// Modified by dbc-patcher V1.0F © 2009 Ingo Müller
VERSION "HNNBNNNYNNNNNNNNNNNNNNNNNNNNNNNNNNNNNNNNNN/4/%%%/4/'%**4NNN///"

NS_ :

BS_:

BU_: Airbag_MQB BAP_Tester_MQB BMS_MQB Datenlogger_MQB Gateway_MQB Getriebe_DQ_Hybrid_MQB Getriebe_DQ_MQB LEH_MQB Motor_Diesel_MQB Motor_Hybrid_MQB Motor_Otto_MQB SAK_MQB Waehlhebel_MQB

BO_ 262 ESP_05: 8 Gateway_MQB
 SG_ ESP_05_CRC : 0|8@1+ (1,0) [0|255] ""  Airbag_MQB,Getriebe_DQ_Hybrid_MQB,Getriebe_DQ_MQB,Motor_Diesel_MQB,Motor_Hybrid_MQB,Motor_Otto_MQB
 SG_ ESP_05_BZ : 8|4@1+ (1,0) [0|15] ""  Airbag_MQB,Getriebe_DQ_Hybrid_MQB,Getriebe_DQ_MQB,Motor_Diesel_MQB,Motor_Hybrid_MQB,Motor_Otto_MQB
 SG_ ESP_QBit_Bremsdruck : 12|1@1+ (1,0) [0|1] ""  Airbag_MQB,Getriebe_DQ_Hybrid_MQB,Getriebe_DQ_MQB,Motor_Diesel_MQB,Motor_Hybrid_MQB,Motor_Otto_MQB
 SG_ ESP_QBit_Fahrer_bremst : 13|1@1+ (1,0) [0|1] ""  Motor_Diesel_MQB,Motor_Hybrid_MQB,Motor_Otto_MQB
 SG_ ESP_Schwelle_Unterdruck : 14|2@1+ (1,0) [0|3] ""  Motor_Diesel_MQB,Motor_Hybrid_MQB,Motor_Otto_MQB
 SG_ ESP_Bremsdruck : 16|10@1+ (0.3,-30) [-30|276.6] "Unit_Bar"  Airbag_MQB,Getriebe_DQ_Hybrid_MQB,Getriebe_DQ_MQB,Motor_Diesel_MQB,Motor_Hybrid_MQB,Motor_Otto_MQB
 SG_ ESP_Fahrer_bremst : 26|1@1+ (1,0) [0|1] ""  Motor_Diesel_MQB,Motor_Hybrid_MQB,Motor_Otto_MQB
 SG_ ESP_Verz_TSK_aktiv : 27|1@1+ (1,0) [0|1] ""  Getriebe_DQ_Hybrid_MQB,Getriebe_DQ_MQB,Motor_Diesel_MQB,Motor_Hybrid_MQB,Motor_Otto_MQB
 SG_ ESP_Lenkeingriff_ADS : 28|1@1+ (1,0) [0|1] ""  Motor_Diesel_MQB,Motor_Hybrid_MQB,Motor_Otto_MQB
 SG_ ESP_Konsistenz_TSK : 29|1@1+ (1,0) [0|1] ""  Motor_Diesel_MQB,Motor_Hybrid_MQB,Motor_Otto_MQB
 SG_ ESP_Bremsruck_AWV2 : 30|1@1+ (1,0) [0|1] ""  Getriebe_DQ_Hybrid_MQB,Getriebe_DQ_MQB,Motor_Diesel_MQB,Motor_Hybrid_MQB,Motor_Otto_MQB
 SG_ ESP_Konsistenz_AWV2 : 31|1@1+ (1,0) [0|1] "" Vector__XXX
 SG_ ECD_Fehler : 32|1@1+ (1,0) [0|1] ""  Motor_Diesel_MQB,Motor_Hybrid_MQB,Motor_Otto_MQB
 SG_ ECD_nicht_verfuegbar : 33|1@1+ (1,0) [0|1] ""  Motor_Diesel_MQB,Motor_Hybrid_MQB,Motor_Otto_MQB
 SG_ ESP_Status_Bremsentemp : 34|1@1+ (1,0) [0|1] ""  Motor_Diesel_MQB,Motor_Hybrid_MQB,Motor_Otto_MQB
 SG_ ESP_Autohold_Standby : 35|1@1+ (1,0) [0|1] "" Vector__XXX
 SG_ ESP_HDC_Standby : 36|1@1+ (1,0) [0|1] ""  Getriebe_DQ_Hybrid_MQB,Getriebe_DQ_MQB
 SG_ ESP_HBA_aktiv : 37|1@1+ (1,0) [0|1] "" Vector__XXX
 SG_ ESP_Prefill_ausgeloest : 38|1@1+ (1,0) [0|1] ""  Motor_Diesel_MQB,Motor_Hybrid_MQB,Motor_Otto_MQB
 SG_ ESP_Rueckwaertsfahrt_erkannt : 39|1@1+ (1,0) [0|1] "" Vector__XXX
 SG_ ESP_Status_Anfahrhilfe : 40|1@1+ (1,0) [0|1] ""  Getriebe_DQ_Hybrid_MQB,Getriebe_DQ_MQB,Motor_Diesel_MQB,Motor_Hybrid_MQB,Motor_Otto_MQB
 SG_ ESP_HDC_aktiv : 41|1@1+ (1,0) [0|1] ""  Getriebe_DQ_Hybrid_MQB,Getriebe_DQ_MQB
 SG_ ESP_StartStopp_Info : 42|2@1+ (1,0) [0|3] ""  Motor_Diesel_MQB,Motor_Otto_MQB
 SG_ ESP_Eingr_HL : 44|1@1+ (1,0) [0|1] "" Vector__XXX
 SG_ ESP_Eingr_HR : 45|1@1+ (1,0) [0|1] "" Vector__XXX
 SG_ ESP_Eingr_VL : 46|1@1+ (1,0) [0|1] "" Vector__XXX
 SG_ ESP_Eingr_VR : 47|1@1+ (1,0) [0|1] "" Vector__XXX
 SG_ ESP_BKV_Unterdruck : 48|8@1+ (4,0) [0|1012] "Unit_MilliBar"  Motor_Diesel_MQB,Motor_Hybrid_MQB,Motor_Otto_MQB
 SG_ ESP_Autohold_aktiv : 56|1@1+ (1,0) [0|1] ""  Getriebe_DQ_Hybrid_MQB,Getriebe_DQ_MQB,Motor_Diesel_MQB,Motor_Hybrid_MQB,Motor_Otto_MQB
 SG_ ESP_FStatus_Anfahrhilfe : 57|1@1+ (1,0) [0|1] ""  Getriebe_DQ_Hybrid_MQB,Getriebe_DQ_MQB
 SG_ ESP_Verz_EPB_aktiv : 58|1@1+ (1,0) [0|1] "" Vector__XXX
 SG_ ECD_Bremslicht : 59|1@1+ (1,0) [0|1] ""  Motor_Diesel_MQB,Motor_Hybrid_MQB,Motor_Otto_MQB
 SG_ ESP_Verzoeg_EPB_verf : 60|1@1+ (1,0) [0|1] "" Vector__XXX
 SG_ ESP_Status_Bremsdruck : 61|1@1+ (1,0) [0|1] ""  Motor_Diesel_MQB,Motor_Hybrid_MQB,Motor_Otto_MQB
 SG_ ESP_Anforderung_EPB : 62|2@1+ (1,0) [0|3] "" Vector__XXX

BO_ 914 ESP_07: 8 Gateway_MQB
 SG_ ESP_07_CRC : 0|8@1+ (1,0) [0|255] ""  Airbag_MQB,Motor_Diesel_MQB,Motor_Hybrid_MQB,Motor_Otto_MQB
 SG_ ESP_07_BZ : 8|4@1+ (1,0) [0|15] ""  Airbag_MQB,Motor_Diesel_MQB,Motor_Hybrid_MQB,Motor_Otto_MQB
 SG_ ESP_ACC_LDE : 12|1@1+ (1,0) [0|1] "" Vector__XXX
 SG_ ESP_Quattro_Antrieb : 13|1@1+ (1,0) [0|1] "" Vector__XXX
 SG_ ESP_Codierung_ADS : 14|2@1+ (1,0) [0|3] "" Vector__XXX
 SG_ ESP_RTA_HL : 16|8@1+ (0.048828125,-6.20117) [-6.20117|6.152345625] "Unit_PerCent" Vector__XXX
 SG_ ESP_RTA_HR : 24|8@1+ (0.048828125,-6.20117) [-6.20117|6.152345625] "Unit_PerCent" Vector__XXX
 SG_ ESP_RTA_VR : 32|8@1+ (0.048828125,-6.20117) [-6.20117|6.152345625] "Unit_PerCent" Vector__XXX
 SG_ OBD_Fehler_Radsensor_HL : 40|4@1+ (1,0) [0|15] ""  Motor_Diesel_MQB,Motor_Hybrid_MQB,Motor_Otto_MQB
 SG_ OBD_Fehler_Radsensor_HR : 44|4@1+ (1,0) [0|15] ""  Motor_Diesel_MQB,Motor_Hybrid_MQB,Motor_Otto_MQB
 SG_ OBD_Fehler_Radsensor_VL : 48|4@1+ (1,0) [0|15] ""  Motor_Diesel_MQB,Motor_Hybrid_MQB,Motor_Otto_MQB
 SG_ OBD_Fehler_Radsensor_VR : 52|4@1+ (1,0) [0|15] ""  Motor_Diesel_MQB,Motor_Hybrid_MQB,Motor_Otto_MQB
 SG_ ESP_Qualifizierung_Antriebsart : 56|1@1+ (1,0) [0|1] "" Vector__XXX
 SG_ ESP_Offroad_Modus : 57|1@1+ (1,0) [0|1] "" Vector__XXX
 SG_ ESP_MKB_ausloesbar : 58|1@1+ (1,0) [0|1] ""  Airbag_MQB
 SG_ ESP_MKB_Status : 59|1@1+ (1,0) [0|1] ""  Airbag_MQB
 SG_ ESP_CM_Variante : 60|1@1+ (1,0) [0|1] "" Vector__XXX
 SG_ ESP_OBD_Status : 61|1@1+ (1,0) [0|1] "" Vector__XXX

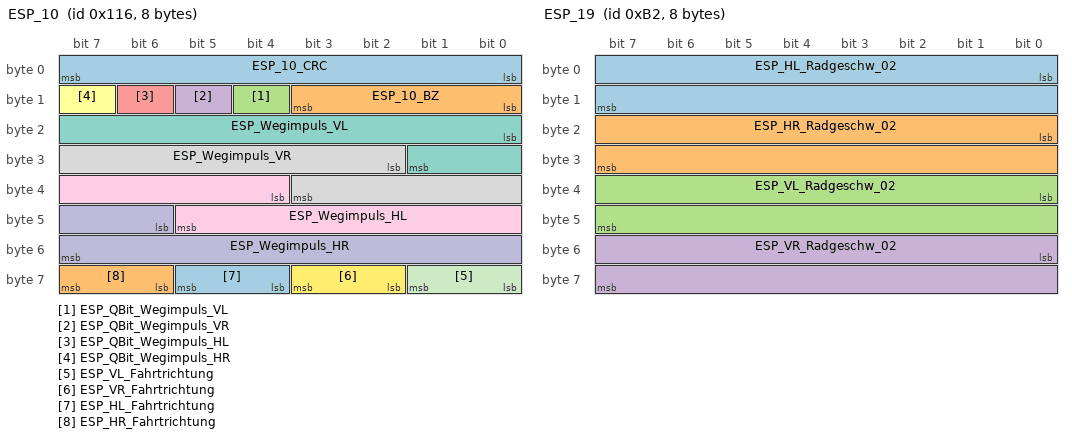
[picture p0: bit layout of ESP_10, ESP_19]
BO_ 278 ESP_10: 8 Gateway_MQB
 SG_ ESP_10_CRC : 0|8@1+ (1,0) [0|255] ""  Airbag_MQB,Motor_Diesel_MQB,Motor_Hybrid_MQB,Motor_Otto_MQB
 SG_ ESP_10_BZ : 8|4@1+ (1,0) [0|15] ""  Airbag_MQB,Motor_Diesel_MQB,Motor_Hybrid_MQB,Motor_Otto_MQB
 SG_ ESP_QBit_Wegimpuls_VL : 12|1@1+ (1,0) [0|1] ""  Getriebe_DQ_Hybrid_MQB,Getriebe_DQ_MQB,Motor_Diesel_MQB,Motor_Hybrid_MQB,Motor_Otto_MQB
 SG_ ESP_QBit_Wegimpuls_VR : 13|1@1+ (1,0) [0|1] ""  Getriebe_DQ_Hybrid_MQB,Getriebe_DQ_MQB,Motor_Diesel_MQB,Motor_Hybrid_MQB,Motor_Otto_MQB
 SG_ ESP_QBit_Wegimpuls_HL : 14|1@1+ (1,0) [0|1] ""  Getriebe_DQ_Hybrid_MQB,Getriebe_DQ_MQB,Motor_Diesel_MQB,Motor_Hybrid_MQB,Motor_Otto_MQB
 SG_ ESP_QBit_Wegimpuls_HR : 15|1@1+ (1,0) [0|1] ""  Getriebe_DQ_Hybrid_MQB,Getriebe_DQ_MQB,Motor_Diesel_MQB,Motor_Hybrid_MQB,Motor_Otto_MQB
 SG_ ESP_Wegimpuls_VL : 16|10@1+ (1,0) [0|1000] ""  Getriebe_DQ_Hybrid_MQB,Getriebe_DQ_MQB,Motor_Diesel_MQB,Motor_Hybrid_MQB,Motor_Otto_MQB
 SG_ ESP_Wegimpuls_VR : 26|10@1+ (1,0) [0|1000] ""  Getriebe_DQ_Hybrid_MQB,Getriebe_DQ_MQB,Motor_Diesel_MQB,Motor_Hybrid_MQB,Motor_Otto_MQB
 SG_ ESP_Wegimpuls_HL : 36|10@1+ (1,0) [0|1000] ""  Getriebe_DQ_Hybrid_MQB,Getriebe_DQ_MQB,Motor_Diesel_MQB,Motor_Hybrid_MQB,Motor_Otto_MQB
 SG_ ESP_Wegimpuls_HR : 46|10@1+ (1,0) [0|1000] ""  Getriebe_DQ_Hybrid_MQB,Getriebe_DQ_MQB,Motor_Diesel_MQB,Motor_Hybrid_MQB,Motor_Otto_MQB
 SG_ ESP_VL_Fahrtrichtung : 56|2@1+ (1,0) [0|3] ""  Airbag_MQB,Getriebe_DQ_Hybrid_MQB,Getriebe_DQ_MQB,Motor_Diesel_MQB,Motor_Hybrid_MQB,Motor_Otto_MQB
 SG_ ESP_VR_Fahrtrichtung : 58|2@1+ (1,0) [0|3] ""  Airbag_MQB,Getriebe_DQ_Hybrid_MQB,Getriebe_DQ_MQB,Motor_Diesel_MQB,Motor_Hybrid_MQB,Motor_Otto_MQB
 SG_ ESP_HL_Fahrtrichtung : 60|2@1+ (1,0) [0|3] ""  Airbag_MQB,Getriebe_DQ_Hybrid_MQB,Getriebe_DQ_MQB,Motor_Diesel_MQB,Motor_Hybrid_MQB,Motor_Otto_MQB
 SG_ ESP_HR_Fahrtrichtung : 62|2@1+ (1,0) [0|3] ""  Airbag_MQB,Getriebe_DQ_Hybrid_MQB,Getriebe_DQ_MQB,Motor_Diesel_MQB,Motor_Hybrid_MQB,Motor_Otto_MQB

BO_ 178 ESP_19: 8 Gateway_MQB
 SG_ ESP_HL_Radgeschw_02 : 0|16@1+ (0.0075,0) [0|491.49] "Unit_KiloMeterPerHour"  Airbag_MQB,Getriebe_DQ_Hybrid_MQB,Getriebe_DQ_MQB,Motor_Diesel_MQB,Motor_Hybrid_MQB,Motor_Otto_MQB
 SG_ ESP_HR_Radgeschw_02 : 16|16@1+ (0.0075,0) [0|491.49] "Unit_KiloMeterPerHour"  Airbag_MQB,Getriebe_DQ_Hybrid_MQB,Getriebe_DQ_MQB,Motor_Diesel_MQB,Motor_Hybrid_MQB,Motor_Otto_MQB
 SG_ ESP_VL_Radgeschw_02 : 32|16@1+ (0.0075,0) [0|491.49] "Unit_KiloMeterPerHour"  Airbag_MQB,Getriebe_DQ_Hybrid_MQB,Getriebe_DQ_MQB,Motor_Diesel_MQB,Motor_Hybrid_MQB,Motor_Otto_MQB
 SG_ ESP_VR_Radgeschw_02 : 48|16@1+ (0.0075,0) [0|491.49] "Unit_KiloMeterPerHour"  Airbag_MQB,Getriebe_DQ_Hybrid_MQB,Getriebe_DQ_MQB,Motor_Diesel_MQB,Motor_Hybrid_MQB,Motor_Otto_MQB

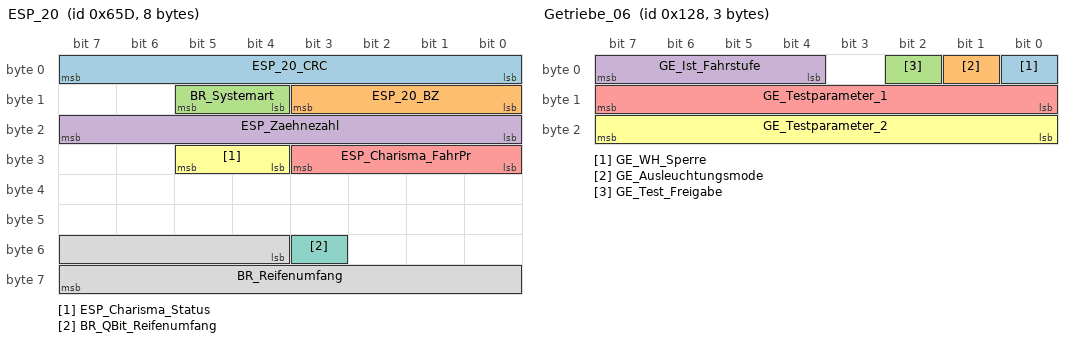
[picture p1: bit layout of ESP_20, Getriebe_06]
BO_ 1629 ESP_20: 8 Gateway_MQB
 SG_ ESP_20_CRC : 0|8@1+ (1,0) [0|255] "" Vector__XXX
 SG_ ESP_20_BZ : 8|4@1+ (1,0) [0|15] "" Vector__XXX
 SG_ BR_Systemart : 12|2@1+ (1,0) [0|3] "" Vector__XXX
 SG_ ESP_Zaehnezahl : 16|8@1+ (1,0) [0|255] ""  Getriebe_DQ_Hybrid_MQB,Getriebe_DQ_MQB
 SG_ ESP_Charisma_FahrPr : 24|4@1+ (1,0) [0|15] "" Vector__XXX
 SG_ ESP_Charisma_Status : 28|2@1+ (1,0) [0|3] "" Vector__XXX
 SG_ BR_QBit_Reifenumfang : 51|1@1+ (1,0) [0|1] ""  Getriebe_DQ_Hybrid_MQB,Getriebe_DQ_MQB
 SG_ BR_Reifenumfang : 52|12@1+ (1,0) [0|4095] "Unit_MilliMeter"  Getriebe_DQ_Hybrid_MQB,Getriebe_DQ_MQB

BO_ 253 ESP_21: 8 Gateway_MQB
 SG_ ESP_21_CRC : 0|8@1+ (1,0) [0|255] ""  Airbag_MQB,Getriebe_DQ_Hybrid_MQB,Getriebe_DQ_MQB,LEH_MQB,Motor_Diesel_MQB,Motor_Hybrid_MQB,Motor_Otto_MQB
 SG_ ESP_21_BZ : 8|4@1+ (1,0) [0|15] ""  Airbag_MQB,BMS_MQB,Getriebe_DQ_Hybrid_MQB,Getriebe_DQ_MQB,LEH_MQB,Motor_Diesel_MQB,Motor_Hybrid_MQB,Motor_Otto_MQB
 SG_ BR_Eingriffsmoment : 12|10@1+ (1,-509) [-509|509] "Unit_NewtoMeter"  Motor_Diesel_MQB,Motor_Hybrid_MQB,Motor_Otto_MQB
 SG_ ESP_v_Signal : 32|16@1+ (0.01,0) [0|655.32] "Unit_KiloMeterPerHour"  Airbag_MQB,BMS_MQB,Getriebe_DQ_Hybrid_MQB,Getriebe_DQ_MQB,LEH_MQB,Motor_Diesel_MQB,Motor_Hybrid_MQB,Motor_Otto_MQB,SAK_MQB
 SG_ ASR_Tastung_passiv : 48|1@1+ (1,0) [0|1] ""  Airbag_MQB,Getriebe_DQ_Hybrid_MQB,Getriebe_DQ_MQB,Motor_Diesel_MQB,Motor_Hybrid_MQB,Motor_Otto_MQB
 SG_ ESP_Tastung_passiv : 49|1@1+ (1,0) [0|1] ""  Airbag_MQB,Getriebe_DQ_Hybrid_MQB,Getriebe_DQ_MQB,Motor_Diesel_MQB,Motor_Hybrid_MQB,Motor_Otto_MQB
 SG_ ESP_Systemstatus : 50|1@1+ (1,0) [0|1] ""  Airbag_MQB,Getriebe_DQ_Hybrid_MQB,Getriebe_DQ_MQB,Motor_Diesel_MQB,Motor_Hybrid_MQB,Motor_Otto_MQB
 SG_ ASR_Schalteingriff : 51|2@1+ (1,0) [0|3] ""  Getriebe_DQ_Hybrid_MQB,Getriebe_DQ_MQB
 SG_ ESP_Haltebestaetigung : 53|1@1+ (1,0) [0|1] ""  Motor_Diesel_MQB,Motor_Hybrid_MQB,Motor_Otto_MQB
 SG_ ESP_QBit_v_Signal : 55|1@1+ (1,0) [0|1] ""  Airbag_MQB,Getriebe_DQ_Hybrid_MQB,Getriebe_DQ_MQB,LEH_MQB,Motor_Diesel_MQB,Motor_Hybrid_MQB,Motor_Otto_MQB
 SG_ ABS_Bremsung : 56|1@1+ (1,0) [0|1] ""  Airbag_MQB,Getriebe_DQ_Hybrid_MQB,Getriebe_DQ_MQB,Motor_Diesel_MQB,Motor_Hybrid_MQB,Motor_Otto_MQB
 SG_ ASR_Anf : 57|1@1+ (1,0) [0|1] ""  Getriebe_DQ_Hybrid_MQB,Getriebe_DQ_MQB,Motor_Diesel_MQB,Motor_Hybrid_MQB,Motor_Otto_MQB
 SG_ MSR_Anf : 58|1@1+ (1,0) [0|1] ""  Getriebe_DQ_Hybrid_MQB,Getriebe_DQ_MQB,Motor_Diesel_MQB,Motor_Hybrid_MQB,Motor_Otto_MQB
 SG_ EBV_Eingriff : 59|1@1+ (1,0) [0|1] ""  Motor_Diesel_MQB,Motor_Hybrid_MQB,Motor_Otto_MQB
 SG_ EDS_Eingriff : 60|1@1+ (1,0) [0|1] ""  Getriebe_DQ_Hybrid_MQB,Getriebe_DQ_MQB,Motor_Diesel_MQB,Motor_Hybrid_MQB,Motor_Otto_MQB
 SG_ ESP_Eingriff : 61|1@1+ (1,0) [0|1] ""  Airbag_MQB,Getriebe_DQ_Hybrid_MQB,Getriebe_DQ_MQB,Motor_Diesel_MQB,Motor_Hybrid_MQB,Motor_Otto_MQB
 SG_ ESP_ASP : 62|1@1+ (1,0) [0|1] ""  Getriebe_DQ_Hybrid_MQB,Getriebe_DQ_MQB,Motor_Diesel_MQB,Motor_Hybrid_MQB,Motor_Otto_MQB
 SG_ ESP_Anhaltevorgang_ACC_aktiv : 63|1@1+ (1,0) [0|1] ""  Motor_Diesel_MQB,Motor_Hybrid_MQB,Motor_Otto_MQB

BO_ 987 Gateway_72: 8 Gateway_MQB
 SG_ BCM_01_alt : 0|1@1+ (1,0) [0|1] ""  Airbag_MQB
 SG_ SMLS_01_alt : 1|1@1+ (1,0) [0|1] ""  Motor_Diesel_MQB,Motor_Otto_MQB
 SG_ ZV_02_alt : 2|1@1+ (1,0) [0|1] ""  Getriebe_DQ_Hybrid_MQB,Getriebe_DQ_MQB,Motor_Diesel_MQB,Motor_Hybrid_MQB,Motor_Otto_MQB
 SG_ Wischer_01_alt : 3|1@1+ (1,0) [0|1] ""  Motor_Diesel_MQB,Motor_Hybrid_MQB,Motor_Otto_MQB
 SG_ Anhaenger_01_alt : 4|1@1+ (1,0) [0|1] ""  Getriebe_DQ_Hybrid_MQB,Getriebe_DQ_MQB
 SG_ Klima_Sensor_02_alt : 5|1@1+ (1,0) [0|1] ""  Getriebe_DQ_Hybrid_MQB,Getriebe_DQ_MQB,Motor_Diesel_MQB,Motor_Hybrid_MQB,Motor_Otto_MQB
 SG_ VSG_01_alt : 6|1@1+ (1,0) [0|1] ""  Airbag_MQB
 SG_ Klima_01_alt : 7|1@1+ (1,0) [0|1] "" Vector__XXX
 SG_ WFS_01_alt : 8|1@1+ (1,0) [0|1] "" Vector__XXX
 SG_ Licht_Anf_01_alt : 9|1@1+ (1,0) [0|1] "" Vector__XXX
 SG_ ZV_HFS_offen : 20|1@1+ (1,0) [0|1] "" Vector__XXX
 SG_ ZV_HBFS_offen : 21|1@1+ (1,0) [0|1] "" Vector__XXX
 SG_ VS_VD_offen_ver : 22|1@1+ (1,0) [0|1] ""  Airbag_MQB
 SG_ VS_VD_zu_ver : 23|1@1+ (1,0) [0|1] "" Vector__XXX
 SG_ ZV_BT_offen : 24|1@1+ (1,0) [0|1] "" Vector__XXX
 SG_ BCM1_Rueckfahrlicht_Schalter : 25|1@1+ (1,0) [0|1] ""  Airbag_MQB
 SG_ ZV_FT_offen : 26|1@1+ (1,0) [0|1] ""  Getriebe_DQ_Hybrid_MQB,Getriebe_DQ_MQB,Motor_Diesel_MQB,Motor_Hybrid_MQB,Motor_Otto_MQB
 SG_ Wischer_vorne_aktiv : 27|1@1+ (1,0) [0|1] ""  Motor_Diesel_MQB,Motor_Hybrid_MQB,Motor_Otto_MQB
 SG_ AAG_Anhaenger_erkannt : 28|1@1+ (1,0) [0|1] ""  Getriebe_DQ_Hybrid_MQB,Getriebe_DQ_MQB
 SG_ BCM1_MH_Schalter : 29|1@1+ (1,0) [0|1] "" Vector__XXX
 SG_ ZV_HD_offen : 30|1@1+ (1,0) [0|1] "" Vector__XXX
 SG_ Waschen_vorne_aktiv : 31|1@1+ (1,0) [0|1] "" Vector__XXX
 SG_ KL_Thermomanagement : 32|2@1+ (1,0) [0|3] "" Vector__XXX
 SG_ WFS_Schluessel_Fahrberecht : 34|4@1+ (1,0) [0|15] "" Vector__XXX
 SG_ BCM1_RFahrlicht_Fzg_Anf : 38|1@1+ (1,0) [0|1] "" Vector__XXX
 SG_ BCM1_RFahrlicht_Ahg_Anf : 39|1@1+ (1,0) [0|1] "" Vector__XXX
 SG_ BH_Fernlicht : 49|1@1+ (1,0) [0|1] "" Vector__XXX
 SG_ BH_Blinker_li : 50|1@1+ (1,0) [0|1] ""  Motor_Diesel_MQB,Motor_Otto_MQB
 SG_ BH_Blinker_re : 51|1@1+ (1,0) [0|1] ""  Motor_Diesel_MQB,Motor_Otto_MQB
 SG_ BCM1_OBD_FStatus_ATemp : 52|4@1+ (1,0) [0|15] ""  Getriebe_DQ_Hybrid_MQB,Getriebe_DQ_MQB,Motor_Diesel_MQB,Motor_Hybrid_MQB,Motor_Otto_MQB
 SG_ BCM1_Aussen_Temp_ungef : 56|8@1+ (0.5,-50) [-50|76] "Unit_DegreCelsi"  Getriebe_DQ_Hybrid_MQB,Getriebe_DQ_MQB,Motor_Diesel_MQB,Motor_Hybrid_MQB,Motor_Otto_MQB

BO_ 989 Gateway_74: 8 Gateway_MQB
 SG_ LH_EPS_01_alt : 0|1@1+ (1,0) [0|1] ""  Motor_Diesel_MQB
 SG_ Kessy_04_alt : 1|1@1+ (1,0) [0|1] ""  Motor_Diesel_MQB,Motor_Otto_MQB
 SG_ LIN_2_alt : 2|1@1+ (1,0) [0|1] ""  Getriebe_DQ_Hybrid_MQB,Getriebe_DQ_MQB
 SG_ MFG_01_alt : 3|1@1+ (1,0) [0|1] ""  Motor_Diesel_MQB,Motor_Otto_MQB
 SG_ GW_74_va_14 : 4|1@1+ (1,0) [0|1] "" Vector__XXX
 SG_ Klima_02_alt : 5|1@1+ (1,0) [0|1] ""  BMS_MQB
 SG_ Parkhilfe_01_alt : 6|1@1+ (1,0) [0|1] ""  Motor_Diesel_MQB,Motor_Otto_MQB
 SG_ ELV_01_alt : 7|1@1+ (1,0) [0|1] ""  Motor_Diesel_MQB,Motor_Hybrid_MQB,Motor_Otto_MQB
 SG_ KY_StartStopp_Info : 16|2@1+ (1,0) [0|3] ""  Motor_Diesel_MQB,Motor_Otto_MQB
 SG_ PH_StartStopp_Info : 18|2@1+ (1,0) [0|3] ""  Motor_Diesel_MQB,Motor_Otto_MQB
 SG_ EPS_Lenkerposition : 20|2@1+ (1,0) [0|3] ""  Motor_Diesel_MQB
 SG_ ELV_Anf_Klemme_50 : 22|1@1+ (1,0) [0|1] ""  Motor_Diesel_MQB,Motor_Hybrid_MQB,Motor_Otto_MQB
 SG_ MF_StartStopp_Info : 25|2@1+ (1,0) [0|3] ""  Motor_Diesel_MQB,Motor_Otto_MQB
 SG_ KL_Geblaesespannung_Soll : 40|8@1+ (0.05,0.5) [2|13] "Unit_Volt"  BMS_MQB
 SG_ KL_Umluftklappe_Status : 48|4@1+ (1,0) [0|15] "" Vector__XXX
 SG_ MFL_Tip_Down : 56|1@1+ (1,0) [0|1] ""  Getriebe_DQ_Hybrid_MQB,Getriebe_DQ_MQB
 SG_ MFL_Tip_Up : 57|1@1+ (1,0) [0|1] ""  Getriebe_DQ_Hybrid_MQB,Getriebe_DQ_MQB
 SG_ LS_Tiptronic_Fehler : 58|1@1+ (1,0) [0|1] ""  Getriebe_DQ_Hybrid_MQB,Getriebe_DQ_MQB

BO_ 296 Getriebe_06: 3 Getriebe_DQ_Hybrid_MQB
 SG_ GE_WH_Sperre : 0|1@1+ (1,0) [0|1] ""  Waehlhebel_MQB
 SG_ GE_Ausleuchtungsmode : 1|1@1+ (1,0) [0|1] ""  Waehlhebel_MQB
 SG_ GE_Test_Freigabe : 2|1@1+ (1,0) [0|1] ""  Waehlhebel_MQB
 SG_ GE_Ist_Fahrstufe : 4|4@1+ (1,0) [0|15] ""  Waehlhebel_MQB
 SG_ GE_Testparameter_1 : 8|8@1+ (1,0) [0|255] ""  Waehlhebel_MQB
 SG_ GE_Testparameter_2 : 16|8@1+ (1,0) [0|255] ""  Waehlhebel_MQB

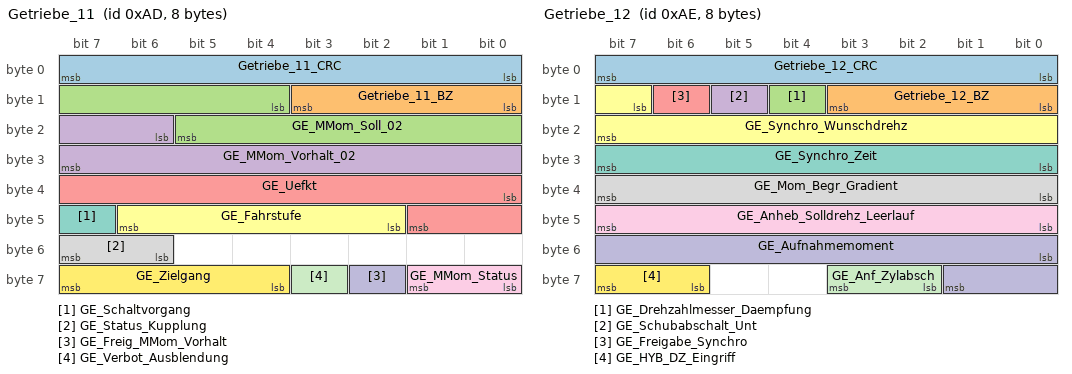
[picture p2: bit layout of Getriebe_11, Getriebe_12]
BO_ 173 Getriebe_11: 8 Getriebe_DQ_Hybrid_MQB
 SG_ Getriebe_11_CRC : 0|8@1+ (1,0) [0|255] ""  Gateway_MQB,Motor_Diesel_MQB,Motor_Hybrid_MQB,Motor_Otto_MQB
 SG_ Getriebe_11_BZ : 8|4@1+ (1,0) [0|15] ""  Gateway_MQB,Motor_Diesel_MQB,Motor_Hybrid_MQB,Motor_Otto_MQB
 SG_ GE_MMom_Soll_02 : 12|10@1+ (1,-509) [-509|509] "Unit_NewtoMeter"  Gateway_MQB,Motor_Diesel_MQB,Motor_Hybrid_MQB,Motor_Otto_MQB
 SG_ GE_MMom_Vorhalt_02 : 22|10@1+ (1,-509) [-509|509] "Unit_NewtoMeter"  Gateway_MQB,Motor_Diesel_MQB,Motor_Hybrid_MQB,Motor_Otto_MQB
 SG_ GE_Uefkt : 32|10@1+ (0.1,0) [0|102.2] ""  Gateway_MQB,Motor_Diesel_MQB,Motor_Hybrid_MQB,Motor_Otto_MQB
 SG_ GE_Fahrstufe : 42|5@1+ (1,0) [0|31] ""  Gateway_MQB,Motor_Diesel_MQB,Motor_Hybrid_MQB,Motor_Otto_MQB
 SG_ GE_Schaltvorgang : 47|1@1+ (1,0) [0|1] ""  Gateway_MQB,Motor_Diesel_MQB,Motor_Hybrid_MQB,Motor_Otto_MQB
 SG_ GE_Status_Kupplung : 54|2@1+ (1,0) [0|3] ""  Gateway_MQB,Motor_Diesel_MQB,Motor_Hybrid_MQB,Motor_Otto_MQB
 SG_ GE_MMom_Status : 56|2@1+ (1,0) [0|3] ""  Gateway_MQB,Motor_Diesel_MQB,Motor_Hybrid_MQB,Motor_Otto_MQB
 SG_ GE_Freig_MMom_Vorhalt : 58|1@1+ (1,0) [0|1] ""  Gateway_MQB,Motor_Diesel_MQB,Motor_Hybrid_MQB,Motor_Otto_MQB
 SG_ GE_Verbot_Ausblendung : 59|1@1+ (1,0) [0|1] ""  Gateway_MQB,Motor_Hybrid_MQB,Motor_Otto_MQB
 SG_ GE_Zielgang : 60|4@1+ (1,0) [0|15] ""  Gateway_MQB,Motor_Diesel_MQB,Motor_Hybrid_MQB,Motor_Otto_MQB

BO_ 174 Getriebe_12: 8 Getriebe_DQ_Hybrid_MQB
 SG_ Getriebe_12_CRC : 0|8@1+ (1,0) [0|255] ""  Motor_Diesel_MQB,Motor_Hybrid_MQB,Motor_Otto_MQB
 SG_ Getriebe_12_BZ : 8|4@1+ (1,0) [0|15] ""  Motor_Diesel_MQB,Motor_Hybrid_MQB,Motor_Otto_MQB
 SG_ GE_Drehzahlmesser_Daempfung : 12|1@1+ (1,0) [0|1] ""  Motor_Diesel_MQB,Motor_Hybrid_MQB,Motor_Otto_MQB
 SG_ GE_Schubabschalt_Unt : 13|1@1+ (1,0) [0|1] ""  Motor_Diesel_MQB,Motor_Hybrid_MQB,Motor_Otto_MQB
 SG_ GE_Freigabe_Synchro : 14|1@1+ (1,0) [0|1] ""  Motor_Diesel_MQB,Motor_Hybrid_MQB,Motor_Otto_MQB
 SG_ GE_Synchro_Wunschdrehz : 15|9@1+ (25,0) [0|12750] "Unit_MinutInver"  Motor_Diesel_MQB,Motor_Hybrid_MQB,Motor_Otto_MQB
 SG_ GE_Synchro_Zeit : 24|8@1+ (20,0) [0|5080] "Unit_MilliSecon"  Motor_Diesel_MQB,Motor_Hybrid_MQB,Motor_Otto_MQB
 SG_ GE_Mom_Begr_Gradient : 32|8@1+ (10,0) [0|2540] "Unit_NewtoMeterPerSecon"  Motor_Diesel_MQB,Motor_Hybrid_MQB,Motor_Otto_MQB
 SG_ GE_Anheb_Solldrehz_Leerlauf : 40|8@1+ (10,0) [0|2540] "Unit_MinutInver"  Motor_Diesel_MQB,Motor_Hybrid_MQB,Motor_Otto_MQB
 SG_ GE_Aufnahmemoment : 48|10@1+ (1,-509) [-509|509] "Unit_NewtoMeter"  Motor_Diesel_MQB,Motor_Hybrid_MQB,Motor_Otto_MQB
 SG_ GE_Anf_Zylabsch : 58|2@1+ (1,0) [0|3] "" Vector__XXX
 SG_ GE_HYB_DZ_Eingriff : 62|2@1+ (1,0) [0|3] ""  Motor_Hybrid_MQB

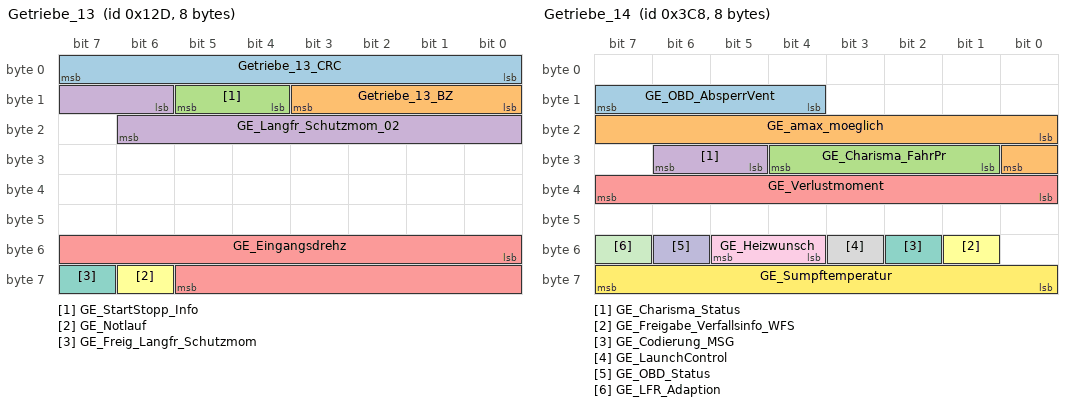
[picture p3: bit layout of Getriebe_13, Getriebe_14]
BO_ 301 Getriebe_13: 8 Getriebe_DQ_Hybrid_MQB
 SG_ Getriebe_13_CRC : 0|8@1+ (1,0) [0|255] ""  Motor_Diesel_MQB,Motor_Hybrid_MQB,Motor_Otto_MQB
 SG_ Getriebe_13_BZ : 8|4@1+ (1,0) [0|15] ""  Motor_Diesel_MQB,Motor_Hybrid_MQB,Motor_Otto_MQB
 SG_ GE_StartStopp_Info : 12|2@1+ (1,0) [0|3] ""  Motor_Diesel_MQB,Motor_Otto_MQB
 SG_ GE_Langfr_Schutzmom_02 : 14|9@1+ (1,0) [0|509] "Unit_NewtoMeter"  Motor_Diesel_MQB,Motor_Hybrid_MQB,Motor_Otto_MQB
 SG_ GE_Eingangsdrehz : 48|14@1+ (1,0) [0|16381] "Unit_MinutInver"  Motor_Diesel_MQB,Motor_Hybrid_MQB,Motor_Otto_MQB
 SG_ GE_Notlauf : 62|1@1+ (1,0) [0|1] ""  Gateway_MQB,Motor_Diesel_MQB,Motor_Hybrid_MQB,Motor_Otto_MQB
 SG_ GE_Freig_Langfr_Schutzmom : 63|1@1+ (1,0) [0|1] ""  Motor_Diesel_MQB,Motor_Hybrid_MQB,Motor_Otto_MQB

BO_ 968 Getriebe_14: 8 Getriebe_DQ_Hybrid_MQB
 SG_ GE_OBD_AbsperrVent : 12|4@1+ (1,0) [0|15] ""  Gateway_MQB,Motor_Diesel_MQB,Motor_Hybrid_MQB,Motor_Otto_MQB
 SG_ GE_amax_moeglich : 16|9@1+ (0.024,-2.016) [-2.016|10.224] "Unit_MeterPerSeconSquar"  Gateway_MQB,Motor_Diesel_MQB,Motor_Hybrid_MQB,Motor_Otto_MQB
 SG_ GE_Charisma_FahrPr : 25|4@1+ (1,0) [0|15] ""  Gateway_MQB
 SG_ GE_Charisma_Status : 29|2@1+ (1,0) [0|3] ""  Gateway_MQB
 SG_ GE_Verlustmoment : 32|8@1+ (1,0) [0|254] ""  Gateway_MQB,Motor_Diesel_MQB,Motor_Hybrid_MQB,Motor_Otto_MQB
 SG_ GE_Freigabe_Verfallsinfo_WFS : 49|1@1+ (1,0) [0|1] ""  Gateway_MQB
 SG_ GE_Codierung_MSG : 50|1@1+ (1,0) [0|1] ""  Gateway_MQB
 SG_ GE_LaunchControl : 51|1@1+ (1,0) [0|1] ""  Gateway_MQB
 SG_ GE_Heizwunsch : 52|2@1+ (1,0) [0|3] ""  Gateway_MQB,Motor_Diesel_MQB,Motor_Hybrid_MQB,Motor_Otto_MQB
 SG_ GE_OBD_Status : 54|1@1+ (1,0) [0|1] ""  Gateway_MQB,Motor_Diesel_MQB,Motor_Hybrid_MQB,Motor_Otto_MQB
 SG_ GE_LFR_Adaption : 55|1@1+ (1,0) [0|1] ""  Gateway_MQB,Motor_Diesel_MQB,Motor_Hybrid_MQB,Motor_Otto_MQB
 SG_ GE_Sumpftemperatur : 56|8@1+ (1,-58) [-58|196] "Unit_DegreCelsi"  Gateway_MQB,Motor_Diesel_MQB,Motor_Hybrid_MQB,Motor_Otto_MQB

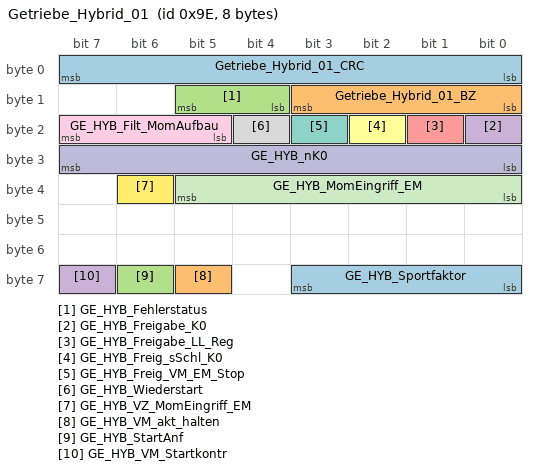
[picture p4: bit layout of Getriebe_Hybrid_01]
BO_ 158 Getriebe_Hybrid_01: 8 Getriebe_DQ_Hybrid_MQB
 SG_ Getriebe_Hybrid_01_CRC : 0|8@1+ (1,0) [0|255] ""  Motor_Hybrid_MQB
 SG_ Getriebe_Hybrid_01_BZ : 8|4@1+ (1,0) [0|15] ""  Motor_Hybrid_MQB
 SG_ GE_HYB_Fehlerstatus : 12|2@1+ (1,0) [0|3] ""  Motor_Hybrid_MQB
 SG_ GE_HYB_Freigabe_K0 : 16|1@1+ (1,0) [0|1] ""  Motor_Hybrid_MQB
 SG_ GE_HYB_Freigabe_LL_Reg : 17|1@1+ (1,0) [0|1] ""  Motor_Hybrid_MQB
 SG_ GE_HYB_Freig_sSchl_K0 : 18|1@1+ (1,0) [0|1] ""  Motor_Hybrid_MQB
 SG_ GE_HYB_Freig_VM_EM_Stop : 19|1@1+ (1,0) [0|1] ""  Motor_Hybrid_MQB
 SG_ GE_HYB_Wiederstart : 20|1@1+ (1,0) [0|1] ""  Motor_Hybrid_MQB
 SG_ GE_HYB_Filt_MomAufbau : 21|3@1+ (1,0) [0|7] ""  Motor_Hybrid_MQB
 SG_ GE_HYB_nK0 : 24|8@1+ (25,0) [0|6350] "Unit_MinutInver" Vector__XXX
 SG_ GE_HYB_MomEingriff_EM : 32|6@1+ (0.5,0) [0|31.5] "Unit_NewtoMeter"  LEH_MQB
 SG_ GE_HYB_VZ_MomEingriff_EM : 38|1@1+ (1,0) [0|1] ""  LEH_MQB
 SG_ GE_HYB_Sportfaktor : 56|4@1+ (1,0) [0|15] ""  Motor_Hybrid_MQB
 SG_ GE_HYB_VM_akt_halten : 61|1@1+ (1,0) [0|1] ""  Motor_Hybrid_MQB
 SG_ GE_HYB_StartAnf : 62|1@1+ (1,0) [0|1] ""  Motor_Hybrid_MQB
 SG_ GE_HYB_VM_Startkontr : 63|1@1+ (1,0) [0|1] ""  Motor_Hybrid_MQB

BO_TX_BU_ 296 : Getriebe_DQ_Hybrid_MQB,Getriebe_DQ_MQB;
BO_TX_BU_ 173 : Getriebe_DQ_Hybrid_MQB,Getriebe_DQ_MQB;
BO_TX_BU_ 174 : Getriebe_DQ_Hybrid_MQB,Getriebe_DQ_MQB;
BO_TX_BU_ 301 : Getriebe_DQ_Hybrid_MQB,Getriebe_DQ_MQB;
BO_TX_BU_ 968 : Getriebe_DQ_Hybrid_MQB,Getriebe_DQ_MQB;
CM_ SG_ 262 ESP_05_CRC "Für MLB:
Berechnung siehe Lastenheft 'Kommunikationsabsicherung für FlexRay und CAN''

Ab MQB und MLBevo:
Berechnung siehe Lastenheft 'End-to-End Kommunikationsabsicherung''

Endwerte siehe Begleitdokument 'S-PDU Kennungsfolgen'";
CM_ SG_ 262 ESP_QBit_Bremsdruck "QBit des Bremsdrucks. Gesetzt bei Ersatzwert, Init oder Fehler.";
CM_ SG_ 262 ESP_QBit_Fahrer_bremst "Gültigkeit der Bremsdruckschwelleninformation des Signals ESP_Fahrer_bremst vom ESP SG
0x1 = Druckschwelleninformation kann noch nicht oder aufgrund eines Fehlers nicht ausgegeben werden
";
CM_ SG_ 262 ESP_Schwelle_Unterdruck "Verwendung im MQB für HBV-Projekte";
CM_ SG_ 262 ESP_Bremsdruck "Rohwert des Bremsdrucks [Vordruck durch Fahrervorgabe (Pvor). Bei aktivem Druckaufbau (Stabilisierungseingriffe) kein Pvor]
";
CM_ SG_ 262 ESP_Fahrer_bremst "Bit wird gesetzt beim Überschreiten der Bremsdruckschwelle

Weiterführende Informationen im Lastenheft spezifiziert und in der entsprechenden Fachabteilung zu erfragen.
";
CM_ SG_ 262 ESP_Verz_TSK_aktiv "Rückmeldeinformation an den Triebsstrangkoordinator/ACC, dass die ECD-Verzögerungsanforderung aktuell umgesetzt wird";
CM_ SG_ 262 ESP_Lenkeingriff_ADS "Im Falle eines fahrzeugstabilisierenden Lenkeingriffs des ADS-Systems soll ACC/GRA deaktiviert werden.

Im MQB wird dieses Signal nicht unterstützt!";
CM_ SG_ 262 ESP_Konsistenz_TSK "Rückmeldung zum Sender einer Verzögerungsanforderung (Triebstrangskoordinator) bezüglich Prüfung der Checksumme, des Botschaftszählers, des langen Timeout und DLC. Wird auch gesetzt bei Verzögerungsanforderung größer einer applizierbaren Schwelle.
";
CM_ SG_ 262 ESP_Bremsruck_AWV2 "Das Signal dient als Rückmeldung zum ACC, dass ein angeforderter AWV2-Bremsruck durchgeführt wird. Die positive Rückmeldung löst u.a. eine entsprechende Fahrerinformation im Kombiinstrument aus";
CM_ SG_ 262 ESP_Konsistenz_AWV2 "Rückmeldung zum Sender einer AWV-Anforderung (ACC-Steuergerät) bezüglich Prüfung der Checksumme, des Botschaftszählers, des langen Timeout und DLC.
";
CM_ SG_ 262 ECD_Fehler "ESP kann die Verzögerungsregelung/Bremsenregelung aufgrund eines internen Fehlers nicht ausführen, mit Fehlereintrag im ESP.
";
CM_ SG_ 262 ECD_nicht_verfuegbar "ESP kann die Verzögerungsregelung/Bremsenregelung temporär nicht ausführen (z.B. Netzwerkmanagement-Betriebe - KL15 Aus; v<18km/h; ESP in Diagnose, ...), ohne Fehlereintrag im ESP.

";
CM_ SG_ 262 ESP_Status_Bremsentemp "ECD-Bremsscheibentemperaturmodell. Rückmeldung für Sender einer ECD Verzögerungsanforderung, ohne Fehlereintrag im ESP";
CM_ SG_ 262 ESP_Autohold_Standby "Rückmeldung an EPB, dass der Fahrer die Funktion Autohold mindestens einmal angefordert hat. Im Fall eines ESP-Ausfalles oder einer Übernahmeaufforderung erfolgt die EPB-Zuschaltung nur nach Setzen dieses Bits. Bit wird gesetzt nach Betätigung des Autohol";
CM_ SG_ 262 ESP_HDC_Standby "Verwendung/Bedienung im Q5 und MQB:
Flag wird vom ESP gesetzt, wenn über den HDC-Taster die HDC-Funktion eingeschalten wurde";
CM_ SG_ 262 ESP_HBA_aktiv "Verwendung/Bedienung ab D4
Signal gibt an, ob der hydraulische Bremsassistent im Regler aktiviert wurde

Im MQB wird das Signal nicht unterstützt!

";
CM_ SG_ 262 ESP_Prefill_ausgeloest "MLB: Verwendung/Bedienung ab D4
zeigt, ob die Funktion Prefill (aufgrund Fahrpedalgradient) ausgelöst wird; zeigt keinen Funktionszustand bezüglich Fehlerstilllegung

MQB: Wird gesetzt bei jeder Art von aktivem Prefill";
CM_ SG_ 262 ESP_Rueckwaertsfahrt_erkannt "nur bei AU57x und AU416
Info, ob Rückwärtsfahrt über internen Algorithmus sicher erkannt

Im MQB wird das Signal nicht unterstützt!";
CM_ SG_ 262 ESP_Status_Anfahrhilfe "Funktionsstatus des Berganfahrassistenten
MQB: Auswertung im Getriebe zwecks Standabkopplung";
CM_ SG_ 262 ESP_HDC_aktiv "MQB: Mit diesem Statusbit wird eine gerade aktive Regelung des Bergabfahrassistenten (Hill Descent Control) signalisiert.";
CM_ SG_ 262 ESP_StartStopp_Info "Stopp-Freigabe und Start-Anforderung an den Start-Stopp-Koordinator

Im MQB werden die Werte '1' und '2' nicht bedient!";
CM_ SG_ 262 ESP_Eingr_HL "nur für QSP
Flag wird vom ESP gesetzt, sobald aufgrund eines ESP-Eingriffs am Rad aktiv Druck aufgebaut wird.
Frühestens mit öffnen des Ventils und spätestens bei einem Bremsmoment von 100Nm. Flag bleibt solange gesetzt wie ein Bremsmoment von mehr als ";
CM_ SG_ 262 ESP_Eingr_HR "nur für QSP
Flag wird vom ESP gesetzt, sobald aufgrund eines ESP-Eingriffs am Rad aktiv Druck aufgebaut wird.
Frühestens mit öffnen des Ventils und spätestens bei einem Bremsmoment von 100Nm. Flag bleibt solange gesetzt wie ein Bremsmoment von mehr als ";
CM_ SG_ 262 ESP_Eingr_VL "nur für QSP
Flag wird vom ESP gesetzt, sobald aufgrund eines ESP-Eingriffs am Rad aktiv Druck aufgebaut wird.
Frühestens mit öffnen des Ventils und spätestens bei einem Bremsmoment von 100Nm. Flag bleibt solange gesetzt wie ein Bremsmoment von mehr als ";
CM_ SG_ 262 ESP_Eingr_VR "nur für QSP
Flag wird vom ESP gesetzt, sobald aufgrund eines ESP-Eingriffs am Rad aktiv Druck aufgebaut wird.
Frühestens mit öffnen des Ventils und spätestens bei einem Bremsmoment von 100Nm. Flag bleibt solange gesetzt wie ein Bremsmoment von mehr als ";
CM_ SG_ 262 ESP_BKV_Unterdruck "Der maximale Wert wird auf 1012 mbar begrenzt";
CM_ SG_ 262 ESP_Autohold_aktiv "Rückmeldung an EPB, dass Autohold aktiv ist.";
CM_ SG_ 262 ESP_FStatus_Anfahrhilfe "Bei gesetztem Bit steht die Funktion Berganfahrassistent (Hillhold) nicht zur Verfügung";
CM_ SG_ 262 ESP_Verz_EPB_aktiv "Bei gesetztem Bit wird die Verzögerungsanforderung von EPB umgesetzt.";
CM_ SG_ 262 ECD_Bremslicht "Bremslichtansteuerung durch ECD-Funktion";
CM_ SG_ 262 ESP_Verzoeg_EPB_verf "Bei gesetztem Bit ist der Verzögerungsregeler für EPB verfügbar.";
CM_ SG_ 262 ESP_Status_Bremsdruck "MLB: Bei gesetztem Bit liegt p > ca. 2 bar an, hervorgerufen durch Fahrer, ASR, FZR, ECD, Bremsregler ... bei Abfall des Bits ist p < X bar, bei aktivem ECD-Eingriff Ende des Eingriffs 

Im MQB wird das Signal nicht unterstützt!

Weiterführende Inform";
CM_ SG_ 262 ESP_Anforderung_EPB "ESP fordert von der EPB Öffnen bzw. Schliessen an. Notwendig wegen Autohold-Funktion.";
CM_ SG_ 914 ESP_07_CRC "Für MLB:
Berechnung siehe Lastenheft 'Kommunikationsabsicherung für FlexRay und CAN''

Ab MQB und MLBevo:
Berechnung siehe Lastenheft 'End-to-End Kommunikationsabsicherung''

Endwerte siehe Begleitdokument 'S-PDU Kennungsfolgen'";
CM_ SG_ 914 ESP_ACC_LDE "Verwendung/Bedienung ab Folgeprojekte D4, aber nicht im D4 selbst
Lebensdauerende für ACC-Bremsung erreicht";
CM_ SG_ 914 ESP_Quattro_Antrieb "Im MQB wird das Signal nicht unterstützt!";
CM_ SG_ 914 ESP_Codierung_ADS "ESP gibt für Empfänger im Fahrzeug aus, ob ADS verbaut/nicht verbaut ist.

Im MQB wird das Signal nicht unterstützt!
";
CM_ SG_ 914 ESP_RTA_HL "Physikalischer Wertebereich +/-5%. Der Reifentoleranzabgleich bezieht sich auf das linke Vorderrad.

physikalischer Wert = ( (Hex-Wert - 0x7F) / 2048 )*100%

Im MQB wird das Signal nicht unterstützt!";
CM_ SG_ 914 ESP_RTA_HR "Physikalischer Wertebereich +/-5%. Der Reifentoleranzabgleich bezieht sich auf das linke Vorderrad.

physikalischer Wert = ( (Hex-Wert - 0x7F) / 2048 )*100%

Im MQB wird das Signal nicht unterstützt!";
CM_ SG_ 914 ESP_RTA_VR "Physikalischer Wertebereich +/-5%. Der Reifentoleranzabgleich bezieht sich auf das linke Vorderrad.

physikalischer Wert = ( (Hex-Wert - 0x7F) / 2048 )*100%

Im MQB wird das Signal nicht unterstützt!";
CM_ SG_ 914 OBD_Fehler_Radsensor_HL "Für Motor-SG (gesetzliche Vorgabe)";
CM_ SG_ 914 OBD_Fehler_Radsensor_HR "Für Motor-SG (gesetzliche Vorgabe)";
CM_ SG_ 914 OBD_Fehler_Radsensor_VL "Für Motor-SG (gesetzliche Vorgabe)";
CM_ SG_ 914 OBD_Fehler_Radsensor_VR "Für Motor-SG (gesetzliche Vorgabe)";
CM_ SG_ 914 ESP_Qualifizierung_Antriebsart "Signal for Bentley BY83x: ESP_wheel_drive_selector

Bit qualifiziert für neue Projekte (ab D4 ff.) das Signal 'ESP_Quattro_Antrieb', d.h. ist 'ESP_Qualifizierung_Antriebsart'
auf 0x1 gesetzt, ändert sich die bisherige Bedeutung des Signals 'ESP_Quattro";
CM_ SG_ 914 ESP_Offroad_Modus "Nur VW526: Bei Offroad-Fahrzeugen kann über einen Schalter ein Offroadmodus gewählt werden, dieser wird hier angezeigt. Bei Offroad Plus- Fahrzeugen wird hier der Offroadmodus indirekt durch das Verteilergetriebe vorgegeben (ALR_Offroad = 1) und eingespie";
CM_ SG_ 914 ESP_MKB_ausloesbar "ESP hat Funktion Multi-Kollisions-Bremsung freigeschaltet";
CM_ SG_ 914 ESP_MKB_Status "ESP führt Multi-Kollisions-Bremsung durch";
CM_ SG_ 914 ESP_CM_Variante "Signal gibt an welche CM-Variante unterstuetzt wird. 
";
CM_ SG_ 914 ESP_OBD_Status "Dieses Bit steuert die MIL-Lampe an (Motorsteuergerät reicht diese Info an Kombi weiter).";
CM_ SG_ 278 ESP_10_CRC "Für MLB:
Berechnung siehe Lastenheft 'Kommunikationsabsicherung für FlexRay und CAN''

Ab MQB und MLBevo:
Berechnung siehe Lastenheft 'End-to-End Kommunikationsabsicherung''

Endwerte siehe Begleitdokument 'S-PDU Kennungsfolgen'";
CM_ SG_ 278 ESP_QBit_Wegimpuls_VL "Qualifizierungsbit Wegimpulszähler VL";
CM_ SG_ 278 ESP_QBit_Wegimpuls_VR "Qualifizierungsbit Wegimpulszähler VR";
CM_ SG_ 278 ESP_QBit_Wegimpuls_HL "Qualifizierungsbit Wegimpulszähler HL";
CM_ SG_ 278 ESP_QBit_Wegimpuls_HR "Qualifizierungsbit Wegimpulszähler HR";
CM_ SG_ 278 ESP_Wegimpuls_VL "Wegimpulszähler VL.
Anzahl der Wegimpulse Vorderrad links (steigende und fallende Flanke)
Zähler läuft grundsätzlich vorwärts, auch bei Rückwärtsfahrt.
Nach SG-Reset ist immer, ohne Ausnahme, 1mal der Init Wert 1021 zu senden.";
CM_ SG_ 278 ESP_Wegimpuls_VR "Wegimpulszähler VR.
Anzahl der Wegimpulse Vorderrad rechts (steigende und fallende Flanke)
Zähler läuft grundsätzlich vorwärts, auch bei Rückwärtsfahrt.
Nach SG-Reset ist immer, ohne Ausnahme, 1mal der Init Wert 1021 zu senden.";
CM_ SG_ 278 ESP_Wegimpuls_HL "Wegimpulszähler HL.
Anzahl der Wegimpulse Hinterrad links (steigende und fallende Flanke)
Zähler läuft grundsätzlich vorwärts, auch bei Rückwärtsfahrt.
Nach SG-Reset ist immer, ohne Ausnahme, 1mal der Init Wert 1021 zu senden.";
CM_ SG_ 278 ESP_Wegimpuls_HR "Wegimpulszähler HR.
Anzahl der Wegimpulse Hinterrad rechts (steigende und fallende Flanke)
Zähler läuft grundsätzlich vorwärts, auch bei Rückwärtsfahrt.
Nach SG-Reset ist immer, ohne Ausnahme, 1mal der Init Wert 1021 zu senden.";
CM_ SG_ 278 ESP_VL_Fahrtrichtung "Drehrichtung Rad VL

Weiterführende Informationen im Lastenheft spezifiziert und in der entsprechenden Fachabteilung zu erfragen.";
CM_ SG_ 278 ESP_VR_Fahrtrichtung "Drehrichtung Rad VR

Weiterführende Informationen im Lastenheft spezifiziert und in der entsprechenden Fachabteilung zu erfragen.";
CM_ SG_ 278 ESP_HL_Fahrtrichtung "Drehrichtung Rad HL

Weiterführende Informationen im Lastenheft spezifiziert und in der entsprechenden Fachabteilung zu erfragen.";
CM_ SG_ 278 ESP_HR_Fahrtrichtung "Drehrichtung Rad HR

Weiterführende Informationen im Lastenheft spezifiziert und in der entsprechenden Fachabteilung zu erfragen.";
CM_ BO_ 178 "Botschaft exklusiv für LB83x - alte Haldex-Schnittstelle, nicht zur Weiterentwicklung verwenden!";
CM_ SG_ 178 ESP_HL_Radgeschw_02 "Radgeschwindigkeit hinten links";
CM_ SG_ 178 ESP_HR_Radgeschw_02 "Radgeschwindigkeit hinten rechts";
CM_ SG_ 178 ESP_VL_Radgeschw_02 "Radgeschwindigkeit vorne links";
CM_ SG_ 178 ESP_VR_Radgeschw_02 "Radgeschwindigkeit vorne rechts";
CM_ BO_ 1629 "neu im MQB";
CM_ SG_ 1629 ESP_20_CRC "Für MLB:
Berechnung siehe Lastenheft 'Kommunikationsabsicherung für FlexRay und CAN''

Ab MQB und MLBevo:
Berechnung siehe Lastenheft 'End-to-End Kommunikationsabsicherung''

Endwerte siehe Begleitdokument 'S-PDU Kennungsfolgen'";
CM_ SG_ 1629 BR_Systemart "Identifikation des verbauten Bremssystems

Dient dem Kombi zur Plausibilisierung";
CM_ SG_ 1629 ESP_Zaehnezahl "Konstanter Wert der Zähnezahl des verwendeten Impulsrades wird ausgegeben, jeder Empfänger der Wegimpulse muss die Zähnezahl einlesen, um eine volle Umdrehung des Rades zu erkennen. 

Weiterführende Informationen im Lastenheft spezifiziert und in der en";
CM_ SG_ 1629 ESP_Charisma_FahrPr "MLBevo: Aktuelles Fahrprogramm des Charisma-Teilnehmers (siehe Systemlastenheft Drive Select)
MQB: Istwert der Kennlinie (siehe Systemlastenheft MQB FPA)

";
CM_ SG_ 1629 ESP_Charisma_Status "Systemstatus des Charismateilnehmers

Wert 0x3 ist nur für Fahrzeuge ab MQB relevant";
CM_ SG_ 1629 BR_QBit_Reifenumfang "Gesetzt bei Ersatzwert, Init oder Fehler.";
CM_ SG_ 1629 BR_Reifenumfang "Mittlerer Radumfang gerechnet in Millimeter.
Von der Bremse plausibilisierter Wert (Kopie von KBI_Reifenumfang wenn dieser plausibel) oder Ersatzwert aus Bremse wenn KBI_Reifenumfang unplausibel. Bitte das QBit beachten!";
CM_ BO_ 253 "Neue Momente im MQB
Struktur ab MQB mit CRC8 entstanden aus ESP_01";
CM_ SG_ 253 ESP_21_CRC "Für MLB:
Berechnung siehe Lastenheft 'Kommunikationsabsicherung für FlexRay und CAN''

Ab MQB und MLBevo:
Berechnung siehe Lastenheft 'End-to-End Kommunikationsabsicherung''

Endwerte siehe Begleitdokument 'S-PDU Kennungsfolgen'";
CM_ SG_ 253 BR_Eingriffsmoment "Faktor in MO_Faktor_Momente_02 in Motor_Code_01 beachten!
Schnelle reduzierende (ASR) oder erhöhende (MSR) Momentanforderung an den Motor.";
CM_ SG_ 253 ESP_v_Signal "Geschwindigkeitssignal vom ABS/ASR oder ESP. Mittelwert der angetriebenen Räder.
Bei MSR oder ABS Eingriffen wird die ABS-Referenzgeschwindigkeit für >= 200ms eingespiegelt (Zeit wird mit Aktiv-Flanke der Funktionsbits getriggert)

MQB: Bei Frontantrie";
CM_ SG_ 253 ASR_Tastung_passiv "ASR deaktiviert oder Schwellen geändert (projektabhängig)
Weiterführende Informationen im Lastenheft spezifiziert und in der entsprechenden Fachabteilung zu erfragen.
";
CM_ SG_ 253 ESP_Tastung_passiv "ESP deaktiviert oder Schwellen geändert (projektabhängig)
Weiterführende Informationen im Lastenheft spezifiziert und in der entsprechenden Fachabteilung zu erfragen.";
CM_ SG_ 253 ESP_Systemstatus "Fehler steht für Stillegung ESP mit Fehlereintrag.

MLB: Flag wird bei Unterspannung im Stand bis einmalig 6km/h (AU48x) oder 10 km/h (AU641, AU57x) überschritten nicht gesetzt (Ausblendung Startvorgang)
Im AU64x, AU57x gilt ESP D4 Funktionsanforderung";
CM_ SG_ 253 ASR_Schalteingriff "Wunsch an das Getriebe während einer ASR Regelung

MLB: Es wird nur 0x0 und 0x1 genutzt

";
CM_ SG_ 253 ESP_Haltebestaetigung "Rückmeldung vom ESP-SG, dass das Fahrzeug aufgrund einer externen Bremsanforderung (z. B. ACC, PLA, ANB, o. ä.) abgebremst wurde und im Stillstand gehalten wird.";
CM_ SG_ 253 ESP_QBit_v_Signal "Geschwindigkeit wird vom ABS/ASR oder ESP aus Ersatzwerten errechnet, wenn Bit gesetzt ist. Güte des Signals ist verändert.";
CM_ SG_ 253 ABS_Bremsung "Antiblockiersystem, Bit zeigt auch Druckabbau an (z.B. ESP hat zuviel Druck aufgebaut oder ungebremste Regelung auf Bahnübergang)
Weiterführende Informationen im Lastenheft spezifiziert und in der entsprechenden Fachabteilung zu erfragen.";
CM_ SG_ 253 ASR_Anf "MLB: Die Momentenanforderung 'ASR_MSR_Moment_schnell' und 'ASR_Moment_langsam' sind auszuführen
MQB: Die Momentenanforderung 'BR_Eingriffsmoment' ist auszuführen";
CM_ SG_ 253 MSR_Anf "MLB: Die Momentenanforderung 'ASR_MSR_Moment_schnell' ist auszuführen.
MQB: Die Momentenanforderung 'BR_Eingriffsmoment' ist auszuführen";
CM_ SG_ 253 EBV_Eingriff "Elektronische Bremskraftverteilung, aktueller Eingriff (Druckhalten, Druckabbau)

Im MLB: kein ABS / ESP-Eingriff ???";
CM_ SG_ 253 EDS_Eingriff "Elektronische Differentialsperre";
CM_ SG_ 253 ESP_Eingriff "Eingriff des Fahrdynamikreglers";
CM_ SG_ 253 ESP_ASP "MLB: Anhaenger-Stabilisierungs-Programm
MQB: Gespannstabilisierung";
CM_ SG_ 253 ESP_Anhaltevorgang_ACC_aktiv "Zeigt an, ob ACC-Anhaltevorgang aktiv";
CM_ BO_ 987 "Komfort -> Antrieb, Extended, Fahrwerk, Infotainment";
CM_ SG_ 987 BCM_01_alt "Veraltet Bit MQB für die Signale:

Botschaft Gateway_72:
BCM1_Rueckfahrlicht_Schalter
BCM1_MH_Schalter

";
CM_ SG_ 987 SMLS_01_alt "Veraltet Bit für die Signale:

Botschaft Gateway_72:
BH_Blinker_li
BH_Blinker_re
BH_Fernlicht";
CM_ SG_ 987 ZV_02_alt "Veraltet Bit MQB für die Signale:

Botschaft Gateway_72:
ZV_HD_offen
ZV_FT_offen
ZV_BT_offen
ZV_HFS_offen
ZV_HBFS_offen";
CM_ SG_ 987 Wischer_01_alt "Veraltet Bit MQB für die Signale:

Botschaft Gateway_72:
Wischer_vorne_aktiv";
CM_ SG_ 987 Anhaenger_01_alt "Veraltet Bit MQB für die Signale:

Botschaft Gateway_72:
AAG_Anhaenger_erkannt

Botschaft Gateway_76:
AAG_Bremslicht_H_def";
CM_ SG_ 987 Klima_Sensor_02_alt "Veraltet Bit für die Signale:

Botschaft Gateway_72:
BCM1_FStatus_Aussentemp_ungef
BCM1_Aussen_Temp_ungef";
CM_ SG_ 987 VSG_01_alt "Veraltet Bit für die Signale:

Botschaft Gateway_72:
VS_VD_offen_ver
VS_VD_zu_ver";
CM_ SG_ 987 Klima_01_alt "Veraltet Bit für die Signale:

Botschaft Gateway_72:
KL_Thermomanagement

Botschaft Gateway_76:
KL_Comp_rev_rq
KL_Comp_enable";
CM_ SG_ 987 WFS_01_alt "Veraltet-Bit für die Signale:

Botschaft Gateway_72:
WFS_Schluessel_Fahrberecht";
CM_ SG_ 987 Licht_Anf_01_alt "Veraltet Bit MQB für die Signale:

Botschaft Gateway_72:
BCM1_RFahrlicht_Fzg_Anf
BCM1_RFahrlicht_Ahg_Anf";
CM_ SG_ 987 ZV_HFS_offen "gespiegeltes Bit HFS_Tuer_geoeffnet TSG_HFS_1 Botschaft";
CM_ SG_ 987 ZV_HBFS_offen "gespiegeltes Bit HBFS_Tuer_geoeffnet TSG_HBFS_1 Botschaft";
CM_ SG_ 987 VS_VD_offen_ver "

";
CM_ SG_ 987 VS_VD_zu_ver "
";
CM_ SG_ 987 ZV_BT_offen "gespiegeltes Bit BT_Tuer_geoeffnet TSG_BT_1 Botschaft";
CM_ SG_ 987 BCM1_Rueckfahrlicht_Schalter "Rückfahrlichtschalter
Die Ganginformation wird unentprellt übertragen, im AT-Getriebe wird evtl. kurzzeitig der R-Gang angezeigt.
Eine Entprellung muß im Empfänger erfolgen (typisch 400ms).";
CM_ SG_ 987 ZV_FT_offen "gespiegeltes Bit FT_Tuer_geoeffnet TSG_FT_1 Botschaft";
CM_ SG_ 987 Wischer_vorne_aktiv "Status: Wischer vorne ";
CM_ SG_ 987 AAG_Anhaenger_erkannt "Erkennung Anhaenger ";
CM_ SG_ 987 BCM1_MH_Schalter "Motorhaubenkontakt";
CM_ SG_ 987 ZV_HD_offen "Status Heckdeckel
";
CM_ SG_ 987 Waschen_vorne_aktiv "Status: Waschen vorne aktiv 
";
CM_ SG_ 987 KL_Thermomanagement "Stufen des Thermomanagements";
CM_ SG_ 987 WFS_Schluessel_Fahrberecht "Schlüsselnummer Fahrberechtigung
0 = ungueltig, xxxx = Schluessel-Nr.";
CM_ SG_ 987 BCM1_RFahrlicht_Fzg_Anf "Anforderung: Rückfahrlicht Fahrzeug (Sollzustand)";
CM_ SG_ 987 BCM1_RFahrlicht_Ahg_Anf "Anforderung: Rückfahrlicht Anhänger (Sollzustand)";
CM_ SG_ 987 BH_Fernlicht "Betaetigung Fernlicht
";
CM_ SG_ 987 BH_Blinker_li "Blinkerhebel Richtung links
";
CM_ SG_ 987 BH_Blinker_re "Blinkerhebel Richtung rechts
";
CM_ SG_ 987 BCM1_OBD_FStatus_ATemp "Fehlerstatus Umgebungstemperatursensor (OBD relevanter Sensor)
";
CM_ SG_ 987 BCM1_Aussen_Temp_ungef "ungefilterter Wert des Aussentemperatursensors
";
CM_ BO_ 989 "Fahrwerk, Komfort, MFL -> Antrieb";
CM_ SG_ 989 LH_EPS_01_alt "Veraltet Bit MQB für die Signale:

Botschaft Gateway_74:
EPS_Lenkerposition
";
CM_ SG_ 989 Kessy_04_alt "Veraltet Bit MQB für die Signale:

Botschaft Gateway_74:
KY_StartStopp_Info";
CM_ SG_ 989 LIN_2_alt "ACHTUNG: Signalname kann sich noch ändern!
Veraltet Bit MQB für die (LIN)-Signale vom MFL:

Botschaft Gateway_74:
MFL_Tip_Down
MFL_Tip_Up
LS_Tiptronic_Fehler";
CM_ SG_ 989 MFG_01_alt "Veraltet Bit MQB für die Signale:

Botschaft Gateway_74:
MF_StartStopp_Info";
CM_ SG_ 989 Klima_02_alt "Veraltet Bit für die Signale:

Botschaft Gateway_74:
KL_Geblaese_Status
KL_Umluftklappe_Status

Botschaft Gateway_76:
KL_Beschlaggefahr";
CM_ SG_ 989 Parkhilfe_01_alt "Veraltet-Bit MQB für die Signale:

Botschaft Gateway_71:
PH_Anf_Audioabsenkung
PH_Systemzustand
PH_Taster

Botschaft Gateway_74:
PH_StartStopp_Info";
CM_ SG_ 989 ELV_01_alt "Veraltet-Bit MQB für die Signale:

Botschaft Gateway_74:
ELV_Anf_Klemme_50";
CM_ SG_ 989 KY_StartStopp_Info "Stopp-Freigabe und Start-Anforderung an den Start-Stopp-Koordinator";
CM_ SG_ 989 PH_StartStopp_Info "Stopp-Freigabe und Start-Anforderung an den Start-Stopp-Koordinator";
CM_ SG_ 989 EPS_Lenkerposition "Position des Lenkers im Fahrzeug";
CM_ SG_ 989 ELV_Anf_Klemme_50 "Signal wird zur Plausibilisierung parrallel zum Klemmensignal auf dem CAN übertragen
Anforderung Klemme_50";
CM_ SG_ 989 MF_StartStopp_Info "Stopp-Freigabe und Start-Anforderung an den Start-Stopp-Koordinator";
CM_ SG_ 989 KL_Geblaesespannung_Soll "Ausgabe des Sollwertes für die Spannung des Klimagebläsemotores vorne.

1..29 = 0 Volt
30..250 = 2 .. 13 Volt
251..255 = 13 Volt







";
CM_ SG_ 989 KL_Umluftklappe_Status "Status Umluftklappe

";
CM_ SG_ 989 MFL_Tip_Down "MFL-Tiptronic Tasten vom MFL für Getriebe
    0x0 = kein Tip_Down
    0x1 = Tip_Down";
CM_ SG_ 989 MFL_Tip_Up "MFL-Tiptronic Tasten vom MFL für Getriebe
    0x0 = kein Tip_Up
    0x1 = Tip_Up";
CM_ SG_ 296 GE_WH_Sperre "Bit wird auf 1 gesetzt, wenn getriebeseitigen Bedingungen erfüllt sind, um Wählhebel zu bewegen.";
CM_ SG_ 296 GE_Ausleuchtungsmode "Begrenzt die Ausleuchtungsdauer, wenn Wählhebel nicht in P (nur RDW)";
CM_ SG_ 296 GE_Test_Freigabe "Das Bit wird auf 1 gesetzt, wenn gültige Testparameter gesendet werden.";
CM_ SG_ 296 GE_Ist_Fahrstufe "Im Getriebe eingelegte Fahrstufe zur Anzeige am Bedienelement. Ist die Fahrstufe ungültig, wird keine Fahrstufe angezeigt.";
CM_ SG_ 296 GE_Testparameter_1 "Testparameter 1 (Frage) zur Überwachung des Wählhebel-SG";
CM_ SG_ 296 GE_Testparameter_2 "Testparameter 2 (Frage) zur Überwachung des Wählhebel-SG";
CM_ SG_ 173 Getriebe_11_CRC "Für MLB:
Berechnung siehe Lastenheft 'Kommunikationsabsicherung für FlexRay und CAN''

Ab MQB und MLBevo:
Berechnung siehe Lastenheft 'End-to-End Kommunikationsabsicherung''

Endwerte siehe Begleitdokument 'S-PDU Kennungsfolgen'";
CM_ SG_ 173 GE_MMom_Soll_02 "Achtung:
Faktor in MO_Faktor_Momente_02 in Motor_Code_01 beachten!

Getriebeeingriff an den Motor.";
CM_ SG_ 173 GE_MMom_Vorhalt_02 "Anforderung einer Momentenreserve durch das Getriebe, gilt nur mit Freigabe durch 
GE_Freig_MMom_Vorhalt

Achtung!
Faktor in MO_Faktor_Momente_02 in Motor_Code_01 beachten!";
CM_ SG_ 173 GE_Uefkt "Übertragungsfunktion des Getriebes
Drehzahlverhältnis = Eingangsdrehzahl / Ausgangsdrehzahl

AL: Wandlerverstärkung x Drehzahlverhältnis
VL: Drehzahlverhältnis
DL: Drehzahlverhältnis der aktiven und kraftschluß führenden Welle zum Abtrieb, bei Schalt";
CM_ SG_ 173 GE_Fahrstufe "Fahrprogramm des Getriebes

Hinweis: Zwischenstellung '0x0' darf nur für Zustandswechsel P/R, R/N, N/D ausgegeben werden, nicht für D/S oder D/Tippgasse wegen Abschaltkriterium GRA/ACC";
CM_ SG_ 173 GE_Schaltvorgang "AL-Getriebe:
Signalisiert wenn ein Gangwechsel durch die jeweiligen Gangssteller durchgeführt wird. Gangwechsel in und aus R werden nicht als Schaltvorgang signalisiert.

DL-Getriebe:
Signalisiert wenn ein Gangwechsel durch die jeweiligen Gangssteller";
CM_ SG_ 173 GE_Status_Kupplung "Status Kupplung
VL: Statusausgabe der Vorwärtskupplung
DL: Statusausgabe der Kraftschluss führenden Kupplung
AL: Statusausgabe der Wandlerüberbrückungskupplung

Alle: Keine Statusausgabe bei Rückwärtsfahrt.";
CM_ SG_ 173 GE_MMom_Status "Qualifiziert 
MLB: GE_MMom_Soll
MQB: GE_MMom_Soll_02";
CM_ SG_ 173 GE_Freig_MMom_Vorhalt "Freigabe für die Anforderung einer Momentenreserve durch das Getriebe über das Signal
MLB: GE_MMom_Vorhalt
MQB: GE_MMom_Vorhalt_02";
CM_ SG_ 173 GE_Verbot_Ausblendung "Verbot Einspritzausblendung für komfortable Schaltungen";
CM_ SG_ 173 GE_Zielgang "VL-Getriebe:
Signalisiert den Zielgang im manuellen Modus während eines Schaltvorgangs bzw. die momentane simulierte Gangstufe wenn kein Schaltvorgang aktiv ist. In den Fahrprogrammen 'D' und 'S' ist die Übersetzung variabel und somit wird dauerhaft 'Ist";
CM_ SG_ 174 Getriebe_12_CRC "Für MLB:
Berechnung siehe Lastenheft 'Kommunikationsabsicherung für FlexRay und CAN''

Ab MQB und MLBevo:
Berechnung siehe Lastenheft 'End-to-End Kommunikationsabsicherung''

Endwerte siehe Begleitdokument 'S-PDU Kennungsfolgen'";
CM_ SG_ 174 GE_Drehzahlmesser_Daempfung "Beim DQ-Getriebe kann die Anzeigedämpfung des Drehzahlmessers beim Schalten geändert werden.";
CM_ SG_ 174 GE_Schubabschalt_Unt "Signalisiert wenn aus der Sicht des Getriebes eine Schubabschaltung des Motors möglich ist. Bei aktiver Schubabschalt-Unterstützung wird sicher gestellt, dass die Kupplung nicht schlagartig geöffnet wird";
CM_ SG_ 174 GE_Freigabe_Synchro "Freigabe der Signale
GE_Synchro_Wunschdrehz' und 'GE_Synchro_Zeit'";
CM_ SG_ 174 GE_Synchro_Wunschdrehz "Gibt dem Motor eine einzuregelnde Wunschdrehzahl vor, z.B. bei einer Rückschaltung (Zwischengas). Die Motorwunschdrehzahl wird durch GE_Freigabe_Synchro freigegeben";
CM_ SG_ 174 GE_Synchro_Zeit "Signalisiert wie schnell die Wunschdrehzahl bei einem Synchronisations-Wunschdrehzahl-Eingriff aufgebaut werden soll. Die Zeitvorgabe 0x0 bedeutet so schnell wie möglich. Die geforderte Synchronisationszeit bleibt bis zum Abbruch oder erreichen der Zeit k";
CM_ SG_ 174 GE_Mom_Begr_Gradient "Gradientenbegrenzung des Motormoments durch das Getriebe";
CM_ SG_ 174 GE_Anheb_Solldrehz_Leerlauf "Anforderung einer absoluten Leerlaufdrehzahl";
CM_ SG_ 174 GE_Aufnahmemoment "Achtung:
Faktor in MO_Faktor_Momente in Motor_Code_01 beachten!

Getriebeaufnahmemoment

Beispiel: Vorsteuermoment für Leerlaufdrehzahlregler im Motor";
CM_ SG_ 174 GE_Anf_Zylabsch "GE_Anforderung_Zylinderabschaltung
Getriebe-Koordination Zylinderumschaltung TMB / VMB (Teilmotorbetrieb / Vollmotorbetrieb)";
CM_ SG_ 174 GE_HYB_DZ_Eingriff "Freigabebedingung für Drehzahleingriff-Hybrid";
CM_ SG_ 301 Getriebe_13_CRC "Für MLB:
Berechnung siehe Lastenheft 'Kommunikationsabsicherung für FlexRay und CAN''

Ab MQB und MLBevo:
Berechnung siehe Lastenheft 'End-to-End Kommunikationsabsicherung''

Endwerte siehe Begleitdokument 'S-PDU Kennungsfolgen'";
CM_ SG_ 301 GE_StartStopp_Info "Stopp-Freigabe und Start-Anforderung an den Start-Stopp-Koordinator";
CM_ SG_ 301 GE_Langfr_Schutzmom_02 "Achtung:
Faktor in MO_Faktor_Momente in Motor_Code_01 beachten!

geführter Getriebeschutz

Bei Parallelhybrid: Begrenzung des Summenmoments von VKM und ELM beachten. Begrenzung betragsmäßig sowohl in positiver als auch negativer Richtung.";
CM_ SG_ 301 GE_Eingangsdrehz "Wird gesendet, um das Lastschlagverhalten bei Schaltvorgängen zu verbessern.";
CM_ SG_ 301 GE_Notlauf "AL/DL: Signalisiert wenn sich das Getriebe (bei DL ein Teilgetriebe) im Notlauf befindet.
VL: Wird gesetzt wenn kein Kraftschluss möglich ist.";
CM_ SG_ 301 GE_Freig_Langfr_Schutzmom "Freigabeflag für das langfristige Schutzmoment für
MLB: GE_Langfr_Schutzmom
MQB: GE_Langfr_Schutzmom_02";
CM_ SG_ 968 GE_OBD_AbsperrVent "Das Getriebesteuergerät führt eine elektrische Diagnose des von ihm angesteuerten Absperrventils für den Öl-Wasser-Wärmetauscher durch und übermittelt das Ergebnis an das MSG (Standard-4Bit-OBD-Status, nicht alle Zustände müssen genutzt werden; so sind z.";
CM_ SG_ 968 GE_amax_moeglich "VL: maximal mögliche Beschleunigung bei Nenndrehzahl
AL/DL: maximal mögliche Beschleunigung im eingelegten Gang";
CM_ SG_ 968 GE_Charisma_FahrPr "MLBevo: Aktuelles Fahrprogramm des Charisma-Teilnehmers (siehe Systemlastenheft Drive Select)
MQB: Istwert der Kennlinie (siehe Systemlastenheft MQB FPA)";
CM_ SG_ 968 GE_Charisma_Status "Charisma Systemstatus des Charisma-Teilnehmers

Wert 0x3 ist nur für Fahrzeuge ab MQB relevant";
CM_ SG_ 968 GE_Verlustmoment "Achtung:
Einheitenloser CAN-Wert.
Faktor in MO_Faktor_Momente in Motor_Code_01 beachten!

Es gilt: Signalspec GE_Verlustmoment v1.0

Verlustmoment inklusive Pumpenaufnahmemoment (Rechenwert aus CAN-Werten und Kennfeldern ermittelt). Inhalt wird alle";
CM_ SG_ 968 GE_Freigabe_Verfallsinfo_WFS "WFS";
CM_ SG_ 968 GE_Codierung_MSG "Statusausgabe der Diagnose für Falschverbau. Plausibilisierung der empfangenen Motor- und Getriebevariante mit der erwarteten Motor- und Getriebevarianten.";
CM_ SG_ 968 GE_LaunchControl "Während einer LaunchControl-Anfahrt sendet das Getriebesteuergerät das Bit LaunchControl_aktiv. Die Bremse wertet dieses Bit aus, um während einer solchen Anfahrt die Regelgrenzen der Schlupfregelung zu erweitern";
CM_ SG_ 968 GE_OBD_Status "Dieses Bit steuert die MIL-Lampe an (Motorsteuergerät reicht diese Info an Kombi weiter).";
CM_ SG_ 968 GE_LFR_Adaption "Qualifiziert das ausgegeben Motorbelastungsmoment (durch GE_Vorsteuermoment) für die Verwendung zur LFR (Leerlauffüllungsregelung) im Moto";
CM_ SG_ 968 GE_Sumpftemperatur "Getriebesumpftemperatur wird über den Temperatursensor auf der Getriebeplatine ermittelt. Die absolute Sumpftemperatur wird vom Motor empfangen, um entsprechende Kühlleistung für das Getriebe einzustellen.";
CM_ BO_ 158 "Motor - Getriebe - Schnittstelle auf CAN-Antrieb (Hybrid)
ab MQB mit CRC-8";
CM_ SG_ 158 Getriebe_Hybrid_01_CRC "Für MLB:
Berechnung siehe Lastenheft 'Kommunikationsabsicherung für FlexRay und CAN''

Ab MQB und MLBevo:
Berechnung siehe Lastenheft 'End-to-End Kommunikationsabsicherung''

Endwerte siehe Begleitdokument 'S-PDU Kennungsfolgen'";
CM_ SG_ 158 Getriebe_Hybrid_01_BZ "überlaufender 4bit Botschaftszaehler; wird in jeder Sendebotschaft inkrementiert";
CM_ SG_ 158 GE_HYB_Fehlerstatus "Hybrid-spezifische Fehlerstati
PQ3x: Fehlerstatus x1b signalisiert, dass der Druck zum Öffnen der K0 nicht ausreicht (nach Kl15 ein)
PL71: Fehlerstatus x1b signalisiert eine unzureichende Druckversorgung durch die EOP.
Fehlerstatus 1xb : Verhinderung u";
CM_ SG_ 158 GE_HYB_Freigabe_K0 "PQ3x: Bit ist Zwangsanforderung für Status der K0
0 = K0 auf
1 = K0 zu
PL72: Übergang von 0 nach 1 (bzw von 1 nach 0) ist Teil des Wiederstart- (Stop-) Handshakes
0 = Freigabe K0 öffnen
1 = Freigabe K0 schließen";
CM_ SG_ 158 GE_HYB_Freigabe_LL_Reg "GSG gibt hier die Aktivierung einer DZ-Regelung von VM und/oder EM frei. (Verhinderung Selbstbeschleuniger)";
CM_ SG_ 158 GE_HYB_Freig_sSchl_K0 "PL72 Hybrid: GSG zeigt an, dass K0 bei Wiederstart schnell geschlossen werden soll (Zweck: Verwendung des folgenden DZ-Sprunges zur Synchronisierung)";
CM_ SG_ 158 GE_HYB_Freig_VM_EM_Stop "Signalisiert Bereitschaft GSG, dass VM gestoppt werden darf (Soft Stop) oder dass EM gestoppt werden darf (Übergang EM-Fahren => EMFahrbereitschaft)";
CM_ SG_ 158 GE_HYB_Wiederstart "Getriebe zeigt an, ob Wiederstart aktiv ist.";
CM_ SG_ 158 GE_HYB_Filt_MomAufbau "Faktor, der im MSG zur Berechnung der Filterkonstanten für den Fahrerwunschmomentenaufbau im Impulsstart verwendet wird.";
CM_ SG_ 158 GE_HYB_nK0 "Nur PQ3x Hybrid:
GSG teilt MSG mit, auf welcher DZ die EM nach schnellem Schließen der K0 und nach DZAngleichung durch das GSG landen wird.
Wenn Signal 'Wiederstart' nicht aktiv: EM-Drehzahl wird gespiegelt.
Wenn Signal 'Wiederstart' aktiv: DZ, auf der";
CM_ SG_ 158 GE_HYB_MomEingriff_EM "Nur PQ3x Hybrid: Direkter Eingriff des GSG auf EM.
Ist der Betrag des Absolutwertes des Eingriffsmomentes in Nm. Verwendet zur Dämpfung des Triebstranges nach Impulsstart, wenn VM-Momente noch ungenau sind.
E-Gas-Sicherheit: begrenzt auf 30 Nm, zusätzli";
CM_ SG_ 158 GE_HYB_VZ_MomEingriff_EM "PQ3x Hybrid:Vorzeichen für Getriebeeingriff auf EM (MomEingriff_EM)";
CM_ SG_ 158 GE_HYB_Sportfaktor "Sportlichkeitsfaktor Getriebe, zur Verwendung in der Hybrid-Fahrstrategie
0 = nicht sportlich
1..15 = sportlich";
CM_ SG_ 158 GE_HYB_VM_akt_halten "Im elektrischen Fahren/Tipp: Übergang von 0 auf 1 zeigt VM-Startanforderung des GSG an.
Empfehlung GSG an MSG, dass VM aktiv gehalten werden soll. Verwendbar z.B. bei den Funktionen 'fast off (Gang halten)' oder bei 'Rückschaltung bei Bremsen'.";
CM_ SG_ 158 GE_HYB_StartAnf "Auslösen des VM_Widerstart bei EM-Betrieb";
CM_ SG_ 158 GE_HYB_VM_Startkontr "Freigabe der Wiederstartkontrolle";
BA_DEF_ BO_  "GenMsgPDUConstants" STRING ;
BA_DEF_ BO_  "GenMsgAutoGenDsp" ENUM  "No","Yes";
BA_DEF_ BO_  "GenMsgAutoGenSnd" ENUM  "No","Yes";
BA_DEF_ BO_  "GenMsgCycleTime" INT 0 65535;
BA_DEF_ BO_  "GenMsgCycleTimeFast" INT 0 65535;
BA_DEF_ BO_  "GenMsgDelayTime" INT 0 100000;
BA_DEF_ BO_  "GenMsgILSupport" ENUM  "No","Yes";
BA_DEF_ BO_  "GenMsgNrOfRepetition" INT 0 100;
BA_DEF_ BO_  "GenMsgSendType" ENUM  "Cyclic","not_used","not_used","not_used","not_used","not_used","not_used","IfActive","NoMsgSendType";
BA_DEF_ BO_  "GenMsgStartDelayTime" INT 0 100000;
BA_DEF_ BO_  "NmMessage" ENUM  "No","Yes";
BA_DEF_ BO_  "NmhMessage" ENUM  "No","Yes";
BA_DEF_ BO_  "VAGTP20_API" HEX 0 255;
BA_DEF_ BO_  "VAGTP20_DynConnection" ENUM  "No","Yes";
BA_DEF_ BO_  "VAGTP20_DynSetup" ENUM  "No","Yes";
BA_DEF_ BO_  "VAGTP20_StatConnection" ENUM  "No","Yes";
BA_DEF_ BO_  "Timeoutzeit" INT 0 1000000;
BA_DEF_ BO_  "DiagRequest" ENUM  "No","Yes";
BA_DEF_ BO_  "DiagResponse" ENUM  "No","Yes";
BA_DEF_ BO_  "DiagState" ENUM  "No","Yes";
BA_DEF_ BO_  "GenMsgChkConstant" HEX 0 4095;
BA_DEF_ SG_  "GenSigAutoGenDsp" ENUM  "No","Yes";
BA_DEF_ SG_  "GenSigAutoGenSnd" ENUM  "No","Yes";
BA_DEF_ SG_  "GenSigEnvVarType" ENUM  "int","float","undef";
BA_DEF_ SG_  "GenSigInactiveValue" INT -2147483648 2147483647;
BA_DEF_ SG_  "GenSigSendType" ENUM  "Cyclic","OnWrite","OnWriteWithRepetition","OnChange","OnChangeWithRepetition","IfActive","IfActiveWithRepetition","NoSigSendType","OnChangeAndIfActive","OnChangeAndIfActiveWithRepetition";
BA_DEF_ SG_  "GenSigStartValue" INT -2147483648 2147483647;
BA_DEF_ SG_  "NWM-WakeupAllowed" ENUM  "No","Yes";
BA_DEF_ SG_  "GenSigFuncType" ENUM  "NoFunction","MsgCounter","CRC-8","XOR","XOR-2","DatedBit","SW-Kl15","CHK","Constant","Protocol";
BA_DEF_ SG_  "GenSigSwitchedByIgnition" ENUM  "No","Yes";
BA_DEF_ SG_  "Fehlerwert" HEX 0 2147483647;
BA_DEF_ SG_  "GenSigMissingSourceValue" HEX 0 2147483647;
BA_DEF_REL_ BU_SG_REL_  "GenSigTimeoutTime" INT 0 65535;
BA_DEF_DEF_  "GenMsgPDUConstants" "";
BA_DEF_DEF_  "GenMsgAutoGenDsp" "Yes";
BA_DEF_DEF_  "GenMsgAutoGenSnd" "Yes";
BA_DEF_DEF_  "GenMsgCycleTime" 0;
BA_DEF_DEF_  "GenMsgCycleTimeFast" 0;
BA_DEF_DEF_  "GenMsgDelayTime" 0;
BA_DEF_DEF_  "GenMsgILSupport" "No";
BA_DEF_DEF_  "GenMsgNrOfRepetition" 0;
BA_DEF_DEF_  "GenMsgSendType" "NoMsgSendType";
BA_DEF_DEF_  "GenMsgStartDelayTime" 0;
BA_DEF_DEF_  "NmMessage" "No";
BA_DEF_DEF_  "NmhMessage" "No";
BA_DEF_DEF_  "VAGTP20_API" 0;
BA_DEF_DEF_  "VAGTP20_DynConnection" "No";
BA_DEF_DEF_  "VAGTP20_DynSetup" "No";
BA_DEF_DEF_  "VAGTP20_StatConnection" "No";
BA_DEF_DEF_  "Timeoutzeit" 0;
BA_DEF_DEF_  "DiagRequest" "No";
BA_DEF_DEF_  "DiagResponse" "No";
BA_DEF_DEF_  "DiagState" "No";
BA_DEF_DEF_  "GenMsgChkConstant" 0;
BA_DEF_DEF_  "GenSigAutoGenDsp" "No";
BA_DEF_DEF_  "GenSigAutoGenSnd" "No";
BA_DEF_DEF_  "GenSigEnvVarType" "undef";
BA_DEF_DEF_  "GenSigInactiveValue" 0;
BA_DEF_DEF_  "GenSigSendType" "NoSigSendType";
BA_DEF_DEF_  "GenSigStartValue" 0;
BA_DEF_DEF_  "NWM-WakeupAllowed" "No";
BA_DEF_DEF_  "GenSigFuncType" "NoFunction";
BA_DEF_DEF_  "GenSigSwitchedByIgnition" "Yes";
BA_DEF_DEF_  "Fehlerwert" 0;
BA_DEF_DEF_  "GenSigMissingSourceValue" 0;
BA_DEF_DEF_REL_ "GenSigTimeoutTime" 0;
BA_ "GenMsgPDUConstants" BO_ 262 "0x07,0x07,0x07,0x07,0x07,0x07,0x07,0x07,0x07,0x07,0x07,0x07,0x07,0x07,0x07,0x07";
BA_ "GenMsgChkConstant" BO_ 262 7;
BA_ "GenMsgSendType" BO_ 262 0;
BA_ "GenMsgILSupport" BO_ 262 1;
BA_ "GenMsgCycleTime" BO_ 262 20;
BA_ "GenMsgPDUConstants" BO_ 914 "0x91,0x91,0x91,0x91,0x91,0x91,0x91,0x91,0x91,0x91,0x91,0x91,0x91,0x91,0x91,0x91";
BA_ "GenMsgChkConstant" BO_ 914 145;
BA_ "GenMsgSendType" BO_ 914 0;
BA_ "GenMsgILSupport" BO_ 914 1;
BA_ "GenMsgCycleTime" BO_ 914 100;
BA_ "GenMsgPDUConstants" BO_ 278 "0xac,0xac,0xac,0xac,0xac,0xac,0xac,0xac,0xac,0xac,0xac,0xac,0xac,0xac,0xac,0xac";
BA_ "GenMsgChkConstant" BO_ 278 172;
BA_ "GenMsgSendType" BO_ 278 0;
BA_ "GenMsgILSupport" BO_ 278 1;
BA_ "GenMsgCycleTime" BO_ 278 20;
BA_ "GenMsgSendType" BO_ 178 0;
BA_ "GenMsgCycleTime" BO_ 178 10;
BA_ "GenMsgPDUConstants" BO_ 1629 "0xac,0xb3,0xab,0xeb,0x7a,0xe1,0x3b,0xf7,0x73,0xba,0x7c,0x9e,0x06,0x5f,0x02,0xd9";
BA_ "GenMsgSendType" BO_ 1629 0;
BA_ "GenMsgILSupport" BO_ 1629 1;
BA_ "GenMsgCycleTime" BO_ 1629 1000;
BA_ "GenMsgPDUConstants" BO_ 253 "0xb4,0xef,0xf8,0x49,0x1e,0xe5,0xc2,0xc0,0x97,0x19,0x3c,0xc9,0xf1,0x98,0xd6,0x61";
BA_ "GenMsgSendType" BO_ 253 0;
BA_ "GenMsgILSupport" BO_ 253 1;
BA_ "GenMsgCycleTime" BO_ 253 20;
BA_ "GenMsgSendType" BO_ 987 0;
BA_ "GenMsgILSupport" BO_ 987 1;
BA_ "GenMsgDelayTime" BO_ 987 10;
BA_ "GenMsgCycleTime" BO_ 987 100;
BA_ "GenMsgSendType" BO_ 989 0;
BA_ "GenMsgILSupport" BO_ 989 1;
BA_ "GenMsgDelayTime" BO_ 989 10;
BA_ "GenMsgCycleTime" BO_ 989 100;
BA_ "GenMsgSendType" BO_ 296 0;
BA_ "GenMsgCycleTime" BO_ 296 20;
BA_ "GenMsgPDUConstants" BO_ 173 "0x3f,0x69,0x39,0xdc,0x94,0xf9,0x14,0x64,0xd8,0x6a,0x34,0xce,0xa2,0x55,0xb5,0x2c";
BA_ "GenMsgSendType" BO_ 173 0;
BA_ "GenMsgILSupport" BO_ 173 1;
BA_ "GenMsgCycleTime" BO_ 173 10;
BA_ "GenMsgPDUConstants" BO_ 174 "0xe6,0x58,0xed,0xb7,0xcc,0x03,0xf2,0x85,0x1c,0x41,0x3d,0x13,0xc3,0x20,0xc6,0x34";
BA_ "GenMsgSendType" BO_ 174 0;
BA_ "GenMsgILSupport" BO_ 174 1;
BA_ "GenMsgCycleTime" BO_ 174 10;
BA_ "GenMsgPDUConstants" BO_ 301 "0x71,0x8d,0xaa,0x78,0x12,0x0c,0xf1,0x68,0xb3,0x7e,0xd0,0x3a,0xd2,0x5e,0x34,0x31";
BA_ "GenMsgSendType" BO_ 301 0;
BA_ "GenMsgILSupport" BO_ 301 1;
BA_ "GenMsgCycleTime" BO_ 301 20;
BA_ "GenMsgSendType" BO_ 968 0;
BA_ "GenMsgILSupport" BO_ 968 1;
BA_ "GenMsgCycleTime" BO_ 968 100;
BA_ "GenMsgPDUConstants" BO_ 158 "0x9e,0x9e,0x9e,0x9e,0x9e,0x9e,0x9e,0x9e,0x9e,0x9e,0x9e,0x9e,0x9e,0x9e,0x9e,0x9e";
BA_ "GenMsgChkConstant" BO_ 158 158;
BA_ "GenMsgSendType" BO_ 158 0;
BA_ "GenMsgILSupport" BO_ 158 1;
BA_ "GenMsgCycleTime" BO_ 158 20;
BA_ "GenSigSwitchedByIgnition" SG_ 262 ESP_05_CRC 0;
BA_ "GenSigFuncType" SG_ 262 ESP_05_CRC 2;
BA_ "GenSigSendType" SG_ 262 ESP_05_CRC 0;
BA_ "GenSigEnvVarType" SG_ 262 ESP_05_CRC 0;
BA_ "GenSigAutoGenSnd" SG_ 262 ESP_05_CRC 1;
BA_ "GenSigAutoGenDsp" SG_ 262 ESP_05_CRC 1;
BA_ "GenSigSwitchedByIgnition" SG_ 262 ESP_05_BZ 0;
BA_ "GenSigFuncType" SG_ 262 ESP_05_BZ 1;
BA_ "GenSigSendType" SG_ 262 ESP_05_BZ 0;
BA_ "GenSigEnvVarType" SG_ 262 ESP_05_BZ 0;
BA_ "GenSigAutoGenSnd" SG_ 262 ESP_05_BZ 1;
BA_ "GenSigAutoGenDsp" SG_ 262 ESP_05_BZ 1;
BA_ "GenSigSwitchedByIgnition" SG_ 262 ESP_QBit_Bremsdruck 0;
BA_ "GenSigStartValue" SG_ 262 ESP_QBit_Bremsdruck 1;
BA_ "GenSigSendType" SG_ 262 ESP_QBit_Bremsdruck 0;
BA_ "GenSigEnvVarType" SG_ 262 ESP_QBit_Bremsdruck 0;
BA_ "GenSigAutoGenSnd" SG_ 262 ESP_QBit_Bremsdruck 1;
BA_ "GenSigAutoGenDsp" SG_ 262 ESP_QBit_Bremsdruck 1;
BA_ "GenSigSwitchedByIgnition" SG_ 262 ESP_QBit_Fahrer_bremst 0;
BA_ "GenSigStartValue" SG_ 262 ESP_QBit_Fahrer_bremst 1;
BA_ "GenSigSendType" SG_ 262 ESP_QBit_Fahrer_bremst 0;
BA_ "GenSigEnvVarType" SG_ 262 ESP_QBit_Fahrer_bremst 0;
BA_ "GenSigAutoGenSnd" SG_ 262 ESP_QBit_Fahrer_bremst 1;
BA_ "GenSigAutoGenDsp" SG_ 262 ESP_QBit_Fahrer_bremst 1;
BA_ "GenSigSwitchedByIgnition" SG_ 262 ESP_Schwelle_Unterdruck 0;
BA_ "GenSigSendType" SG_ 262 ESP_Schwelle_Unterdruck 0;
BA_ "GenSigEnvVarType" SG_ 262 ESP_Schwelle_Unterdruck 0;
BA_ "GenSigAutoGenSnd" SG_ 262 ESP_Schwelle_Unterdruck 1;
BA_ "GenSigAutoGenDsp" SG_ 262 ESP_Schwelle_Unterdruck 1;
BA_ "Fehlerwert" SG_ 262 ESP_Bremsdruck 1023;
BA_ "GenSigSwitchedByIgnition" SG_ 262 ESP_Bremsdruck 0;
BA_ "GenSigStartValue" SG_ 262 ESP_Bremsdruck 100;
BA_ "GenSigSendType" SG_ 262 ESP_Bremsdruck 0;
BA_ "GenSigEnvVarType" SG_ 262 ESP_Bremsdruck 1;
BA_ "GenSigAutoGenSnd" SG_ 262 ESP_Bremsdruck 1;
BA_ "GenSigAutoGenDsp" SG_ 262 ESP_Bremsdruck 1;
BA_ "GenSigSwitchedByIgnition" SG_ 262 ESP_Fahrer_bremst 0;
BA_ "GenSigSendType" SG_ 262 ESP_Fahrer_bremst 0;
BA_ "GenSigEnvVarType" SG_ 262 ESP_Fahrer_bremst 0;
BA_ "GenSigAutoGenSnd" SG_ 262 ESP_Fahrer_bremst 1;
BA_ "GenSigAutoGenDsp" SG_ 262 ESP_Fahrer_bremst 1;
BA_ "GenSigSwitchedByIgnition" SG_ 262 ESP_Verz_TSK_aktiv 0;
BA_ "GenSigSendType" SG_ 262 ESP_Verz_TSK_aktiv 0;
BA_ "GenSigEnvVarType" SG_ 262 ESP_Verz_TSK_aktiv 0;
BA_ "GenSigAutoGenSnd" SG_ 262 ESP_Verz_TSK_aktiv 1;
BA_ "GenSigAutoGenDsp" SG_ 262 ESP_Verz_TSK_aktiv 1;
BA_ "GenSigSwitchedByIgnition" SG_ 262 ESP_Lenkeingriff_ADS 0;
BA_ "GenSigSendType" SG_ 262 ESP_Lenkeingriff_ADS 0;
BA_ "GenSigEnvVarType" SG_ 262 ESP_Lenkeingriff_ADS 0;
BA_ "GenSigAutoGenSnd" SG_ 262 ESP_Lenkeingriff_ADS 1;
BA_ "GenSigAutoGenDsp" SG_ 262 ESP_Lenkeingriff_ADS 1;
BA_ "GenSigSwitchedByIgnition" SG_ 262 ESP_Konsistenz_TSK 0;
BA_ "GenSigSendType" SG_ 262 ESP_Konsistenz_TSK 0;
BA_ "GenSigEnvVarType" SG_ 262 ESP_Konsistenz_TSK 0;
BA_ "GenSigAutoGenSnd" SG_ 262 ESP_Konsistenz_TSK 1;
BA_ "GenSigAutoGenDsp" SG_ 262 ESP_Konsistenz_TSK 1;
BA_ "GenSigSwitchedByIgnition" SG_ 262 ESP_Bremsruck_AWV2 0;
BA_ "GenSigSendType" SG_ 262 ESP_Bremsruck_AWV2 0;
BA_ "GenSigEnvVarType" SG_ 262 ESP_Bremsruck_AWV2 0;
BA_ "GenSigAutoGenSnd" SG_ 262 ESP_Bremsruck_AWV2 1;
BA_ "GenSigAutoGenDsp" SG_ 262 ESP_Bremsruck_AWV2 1;
BA_ "GenSigSwitchedByIgnition" SG_ 262 ESP_Konsistenz_AWV2 0;
BA_ "GenSigSendType" SG_ 262 ESP_Konsistenz_AWV2 0;
BA_ "GenSigEnvVarType" SG_ 262 ESP_Konsistenz_AWV2 0;
BA_ "GenSigAutoGenSnd" SG_ 262 ESP_Konsistenz_AWV2 1;
BA_ "GenSigAutoGenDsp" SG_ 262 ESP_Konsistenz_AWV2 1;
BA_ "GenSigSwitchedByIgnition" SG_ 262 ECD_Fehler 0;
BA_ "GenSigSendType" SG_ 262 ECD_Fehler 0;
BA_ "GenSigEnvVarType" SG_ 262 ECD_Fehler 0;
BA_ "GenSigAutoGenSnd" SG_ 262 ECD_Fehler 1;
BA_ "GenSigAutoGenDsp" SG_ 262 ECD_Fehler 1;
BA_ "GenSigSwitchedByIgnition" SG_ 262 ECD_nicht_verfuegbar 0;
BA_ "GenSigStartValue" SG_ 262 ECD_nicht_verfuegbar 1;
BA_ "GenSigSendType" SG_ 262 ECD_nicht_verfuegbar 0;
BA_ "GenSigEnvVarType" SG_ 262 ECD_nicht_verfuegbar 0;
BA_ "GenSigAutoGenSnd" SG_ 262 ECD_nicht_verfuegbar 1;
BA_ "GenSigAutoGenDsp" SG_ 262 ECD_nicht_verfuegbar 1;
BA_ "GenSigSwitchedByIgnition" SG_ 262 ESP_Status_Bremsentemp 0;
BA_ "GenSigSendType" SG_ 262 ESP_Status_Bremsentemp 0;
BA_ "GenSigEnvVarType" SG_ 262 ESP_Status_Bremsentemp 0;
BA_ "GenSigAutoGenSnd" SG_ 262 ESP_Status_Bremsentemp 1;
BA_ "GenSigAutoGenDsp" SG_ 262 ESP_Status_Bremsentemp 1;
BA_ "GenSigSwitchedByIgnition" SG_ 262 ESP_Autohold_Standby 0;
BA_ "GenSigSendType" SG_ 262 ESP_Autohold_Standby 0;
BA_ "GenSigEnvVarType" SG_ 262 ESP_Autohold_Standby 0;
BA_ "GenSigAutoGenSnd" SG_ 262 ESP_Autohold_Standby 1;
BA_ "GenSigAutoGenDsp" SG_ 262 ESP_Autohold_Standby 1;
BA_ "GenSigSwitchedByIgnition" SG_ 262 ESP_HDC_Standby 0;
BA_ "GenSigSendType" SG_ 262 ESP_HDC_Standby 0;
BA_ "GenSigEnvVarType" SG_ 262 ESP_HDC_Standby 0;
BA_ "GenSigAutoGenSnd" SG_ 262 ESP_HDC_Standby 1;
BA_ "GenSigAutoGenDsp" SG_ 262 ESP_HDC_Standby 1;
BA_ "GenSigSwitchedByIgnition" SG_ 262 ESP_HBA_aktiv 0;
BA_ "GenSigSendType" SG_ 262 ESP_HBA_aktiv 0;
BA_ "GenSigAutoGenSnd" SG_ 262 ESP_HBA_aktiv 1;
BA_ "GenSigAutoGenDsp" SG_ 262 ESP_HBA_aktiv 1;
BA_ "GenSigSwitchedByIgnition" SG_ 262 ESP_Prefill_ausgeloest 0;
BA_ "GenSigSendType" SG_ 262 ESP_Prefill_ausgeloest 0;
BA_ "GenSigAutoGenSnd" SG_ 262 ESP_Prefill_ausgeloest 1;
BA_ "GenSigAutoGenDsp" SG_ 262 ESP_Prefill_ausgeloest 1;
BA_ "GenSigSwitchedByIgnition" SG_ 262 ESP_Rueckwaertsfahrt_erkannt 0;
BA_ "GenSigSendType" SG_ 262 ESP_Rueckwaertsfahrt_erkannt 0;
BA_ "GenSigAutoGenSnd" SG_ 262 ESP_Rueckwaertsfahrt_erkannt 1;
BA_ "GenSigAutoGenDsp" SG_ 262 ESP_Rueckwaertsfahrt_erkannt 1;
BA_ "GenSigSwitchedByIgnition" SG_ 262 ESP_Status_Anfahrhilfe 0;
BA_ "GenSigSendType" SG_ 262 ESP_Status_Anfahrhilfe 0;
BA_ "GenSigEnvVarType" SG_ 262 ESP_Status_Anfahrhilfe 0;
BA_ "GenSigAutoGenSnd" SG_ 262 ESP_Status_Anfahrhilfe 1;
BA_ "GenSigAutoGenDsp" SG_ 262 ESP_Status_Anfahrhilfe 1;
BA_ "GenSigSwitchedByIgnition" SG_ 262 ESP_HDC_aktiv 0;
BA_ "GenSigSendType" SG_ 262 ESP_HDC_aktiv 0;
BA_ "GenSigSwitchedByIgnition" SG_ 262 ESP_StartStopp_Info 0;
BA_ "GenSigSendType" SG_ 262 ESP_StartStopp_Info 0;
BA_ "GenSigAutoGenSnd" SG_ 262 ESP_StartStopp_Info 1;
BA_ "GenSigAutoGenDsp" SG_ 262 ESP_StartStopp_Info 1;
BA_ "GenSigSwitchedByIgnition" SG_ 262 ESP_Eingr_HL 0;
BA_ "GenSigSendType" SG_ 262 ESP_Eingr_HL 0;
BA_ "GenSigEnvVarType" SG_ 262 ESP_Eingr_HL 0;
BA_ "GenSigAutoGenSnd" SG_ 262 ESP_Eingr_HL 1;
BA_ "GenSigAutoGenDsp" SG_ 262 ESP_Eingr_HL 1;
BA_ "GenSigSwitchedByIgnition" SG_ 262 ESP_Eingr_HR 0;
BA_ "GenSigSendType" SG_ 262 ESP_Eingr_HR 0;
BA_ "GenSigEnvVarType" SG_ 262 ESP_Eingr_HR 0;
BA_ "GenSigAutoGenSnd" SG_ 262 ESP_Eingr_HR 1;
BA_ "GenSigAutoGenDsp" SG_ 262 ESP_Eingr_HR 1;
BA_ "GenSigSwitchedByIgnition" SG_ 262 ESP_Eingr_VL 0;
BA_ "GenSigSendType" SG_ 262 ESP_Eingr_VL 0;
BA_ "GenSigEnvVarType" SG_ 262 ESP_Eingr_VL 0;
BA_ "GenSigAutoGenSnd" SG_ 262 ESP_Eingr_VL 1;
BA_ "GenSigAutoGenDsp" SG_ 262 ESP_Eingr_VL 1;
BA_ "GenSigSwitchedByIgnition" SG_ 262 ESP_Eingr_VR 0;
BA_ "GenSigSendType" SG_ 262 ESP_Eingr_VR 0;
BA_ "GenSigEnvVarType" SG_ 262 ESP_Eingr_VR 0;
BA_ "GenSigAutoGenSnd" SG_ 262 ESP_Eingr_VR 1;
BA_ "GenSigAutoGenDsp" SG_ 262 ESP_Eingr_VR 1;
BA_ "Fehlerwert" SG_ 262 ESP_BKV_Unterdruck 255;
BA_ "GenSigSwitchedByIgnition" SG_ 262 ESP_BKV_Unterdruck 0;
BA_ "GenSigStartValue" SG_ 262 ESP_BKV_Unterdruck 254;
BA_ "GenSigSendType" SG_ 262 ESP_BKV_Unterdruck 0;
BA_ "GenSigEnvVarType" SG_ 262 ESP_BKV_Unterdruck 0;
BA_ "GenSigAutoGenSnd" SG_ 262 ESP_BKV_Unterdruck 1;
BA_ "GenSigAutoGenDsp" SG_ 262 ESP_BKV_Unterdruck 1;
BA_ "GenSigSwitchedByIgnition" SG_ 262 ESP_Autohold_aktiv 0;
BA_ "GenSigSendType" SG_ 262 ESP_Autohold_aktiv 0;
BA_ "GenSigEnvVarType" SG_ 262 ESP_Autohold_aktiv 0;
BA_ "GenSigAutoGenSnd" SG_ 262 ESP_Autohold_aktiv 1;
BA_ "GenSigAutoGenDsp" SG_ 262 ESP_Autohold_aktiv 1;
BA_ "GenSigSwitchedByIgnition" SG_ 262 ESP_FStatus_Anfahrhilfe 0;
BA_ "GenSigSendType" SG_ 262 ESP_FStatus_Anfahrhilfe 0;
BA_ "GenSigEnvVarType" SG_ 262 ESP_FStatus_Anfahrhilfe 0;
BA_ "GenSigAutoGenSnd" SG_ 262 ESP_FStatus_Anfahrhilfe 1;
BA_ "GenSigAutoGenDsp" SG_ 262 ESP_FStatus_Anfahrhilfe 1;
BA_ "GenSigSwitchedByIgnition" SG_ 262 ESP_Verz_EPB_aktiv 0;
BA_ "GenSigSendType" SG_ 262 ESP_Verz_EPB_aktiv 0;
BA_ "GenSigEnvVarType" SG_ 262 ESP_Verz_EPB_aktiv 0;
BA_ "GenSigAutoGenSnd" SG_ 262 ESP_Verz_EPB_aktiv 1;
BA_ "GenSigAutoGenDsp" SG_ 262 ESP_Verz_EPB_aktiv 1;
BA_ "GenSigSwitchedByIgnition" SG_ 262 ECD_Bremslicht 0;
BA_ "GenSigSendType" SG_ 262 ECD_Bremslicht 0;
BA_ "GenSigEnvVarType" SG_ 262 ECD_Bremslicht 0;
BA_ "GenSigAutoGenSnd" SG_ 262 ECD_Bremslicht 1;
BA_ "GenSigAutoGenDsp" SG_ 262 ECD_Bremslicht 1;
BA_ "GenSigSwitchedByIgnition" SG_ 262 ESP_Verzoeg_EPB_verf 0;
BA_ "GenSigSendType" SG_ 262 ESP_Verzoeg_EPB_verf 0;
BA_ "GenSigEnvVarType" SG_ 262 ESP_Verzoeg_EPB_verf 0;
BA_ "GenSigAutoGenSnd" SG_ 262 ESP_Verzoeg_EPB_verf 1;
BA_ "GenSigAutoGenDsp" SG_ 262 ESP_Verzoeg_EPB_verf 1;
BA_ "GenSigSwitchedByIgnition" SG_ 262 ESP_Status_Bremsdruck 0;
BA_ "GenSigSendType" SG_ 262 ESP_Status_Bremsdruck 0;
BA_ "GenSigEnvVarType" SG_ 262 ESP_Status_Bremsdruck 0;
BA_ "GenSigAutoGenSnd" SG_ 262 ESP_Status_Bremsdruck 1;
BA_ "GenSigAutoGenDsp" SG_ 262 ESP_Status_Bremsdruck 1;
BA_ "GenSigSwitchedByIgnition" SG_ 262 ESP_Anforderung_EPB 0;
BA_ "GenSigSendType" SG_ 262 ESP_Anforderung_EPB 0;
BA_ "GenSigEnvVarType" SG_ 262 ESP_Anforderung_EPB 0;
BA_ "GenSigAutoGenSnd" SG_ 262 ESP_Anforderung_EPB 1;
BA_ "GenSigAutoGenDsp" SG_ 262 ESP_Anforderung_EPB 1;
BA_ "GenSigSwitchedByIgnition" SG_ 914 ESP_07_CRC 0;
BA_ "GenSigFuncType" SG_ 914 ESP_07_CRC 2;
BA_ "GenSigSendType" SG_ 914 ESP_07_CRC 0;
BA_ "GenSigEnvVarType" SG_ 914 ESP_07_CRC 0;
BA_ "GenSigAutoGenSnd" SG_ 914 ESP_07_CRC 1;
BA_ "GenSigAutoGenDsp" SG_ 914 ESP_07_CRC 1;
BA_ "GenSigSwitchedByIgnition" SG_ 914 ESP_07_BZ 0;
BA_ "GenSigFuncType" SG_ 914 ESP_07_BZ 1;
BA_ "GenSigSendType" SG_ 914 ESP_07_BZ 0;
BA_ "GenSigEnvVarType" SG_ 914 ESP_07_BZ 0;
BA_ "GenSigAutoGenSnd" SG_ 914 ESP_07_BZ 1;
BA_ "GenSigAutoGenDsp" SG_ 914 ESP_07_BZ 1;
BA_ "GenSigSwitchedByIgnition" SG_ 914 ESP_ACC_LDE 0;
BA_ "GenSigSendType" SG_ 914 ESP_ACC_LDE 0;
BA_ "GenSigAutoGenSnd" SG_ 914 ESP_ACC_LDE 1;
BA_ "GenSigAutoGenDsp" SG_ 914 ESP_ACC_LDE 1;
BA_ "GenSigSwitchedByIgnition" SG_ 914 ESP_Quattro_Antrieb 0;
BA_ "GenSigSendType" SG_ 914 ESP_Quattro_Antrieb 0;
BA_ "GenSigEnvVarType" SG_ 914 ESP_Quattro_Antrieb 0;
BA_ "GenSigAutoGenSnd" SG_ 914 ESP_Quattro_Antrieb 1;
BA_ "GenSigAutoGenDsp" SG_ 914 ESP_Quattro_Antrieb 1;
BA_ "GenSigSwitchedByIgnition" SG_ 914 ESP_Codierung_ADS 0;
BA_ "GenSigSendType" SG_ 914 ESP_Codierung_ADS 0;
BA_ "GenSigEnvVarType" SG_ 914 ESP_Codierung_ADS 0;
BA_ "GenSigAutoGenSnd" SG_ 914 ESP_Codierung_ADS 1;
BA_ "GenSigAutoGenDsp" SG_ 914 ESP_Codierung_ADS 1;
BA_ "Fehlerwert" SG_ 914 ESP_RTA_HL 255;
BA_ "GenSigSwitchedByIgnition" SG_ 914 ESP_RTA_HL 0;
BA_ "GenSigStartValue" SG_ 914 ESP_RTA_HL 254;
BA_ "GenSigSendType" SG_ 914 ESP_RTA_HL 0;
BA_ "GenSigEnvVarType" SG_ 914 ESP_RTA_HL 1;
BA_ "GenSigAutoGenSnd" SG_ 914 ESP_RTA_HL 1;
BA_ "GenSigAutoGenDsp" SG_ 914 ESP_RTA_HL 1;
BA_ "Fehlerwert" SG_ 914 ESP_RTA_HR 255;
BA_ "GenSigSwitchedByIgnition" SG_ 914 ESP_RTA_HR 0;
BA_ "GenSigStartValue" SG_ 914 ESP_RTA_HR 254;
BA_ "GenSigSendType" SG_ 914 ESP_RTA_HR 0;
BA_ "GenSigEnvVarType" SG_ 914 ESP_RTA_HR 1;
BA_ "GenSigAutoGenSnd" SG_ 914 ESP_RTA_HR 1;
BA_ "GenSigAutoGenDsp" SG_ 914 ESP_RTA_HR 1;
BA_ "Fehlerwert" SG_ 914 ESP_RTA_VR 255;
BA_ "GenSigSwitchedByIgnition" SG_ 914 ESP_RTA_VR 0;
BA_ "GenSigStartValue" SG_ 914 ESP_RTA_VR 254;
BA_ "GenSigSendType" SG_ 914 ESP_RTA_VR 0;
BA_ "GenSigEnvVarType" SG_ 914 ESP_RTA_VR 1;
BA_ "GenSigAutoGenSnd" SG_ 914 ESP_RTA_VR 1;
BA_ "GenSigAutoGenDsp" SG_ 914 ESP_RTA_VR 1;
BA_ "GenSigSwitchedByIgnition" SG_ 914 OBD_Fehler_Radsensor_HL 0;
BA_ "GenSigSendType" SG_ 914 OBD_Fehler_Radsensor_HL 0;
BA_ "GenSigAutoGenSnd" SG_ 914 OBD_Fehler_Radsensor_HL 1;
BA_ "GenSigAutoGenDsp" SG_ 914 OBD_Fehler_Radsensor_HL 1;
BA_ "GenSigSwitchedByIgnition" SG_ 914 OBD_Fehler_Radsensor_HR 0;
BA_ "GenSigSendType" SG_ 914 OBD_Fehler_Radsensor_HR 0;
BA_ "GenSigAutoGenSnd" SG_ 914 OBD_Fehler_Radsensor_HR 1;
BA_ "GenSigAutoGenDsp" SG_ 914 OBD_Fehler_Radsensor_HR 1;
BA_ "GenSigSwitchedByIgnition" SG_ 914 OBD_Fehler_Radsensor_VL 0;
BA_ "GenSigSendType" SG_ 914 OBD_Fehler_Radsensor_VL 0;
BA_ "GenSigAutoGenSnd" SG_ 914 OBD_Fehler_Radsensor_VL 1;
BA_ "GenSigAutoGenDsp" SG_ 914 OBD_Fehler_Radsensor_VL 1;
BA_ "GenSigSwitchedByIgnition" SG_ 914 OBD_Fehler_Radsensor_VR 0;
BA_ "GenSigSendType" SG_ 914 OBD_Fehler_Radsensor_VR 0;
BA_ "GenSigAutoGenSnd" SG_ 914 OBD_Fehler_Radsensor_VR 1;
BA_ "GenSigAutoGenDsp" SG_ 914 OBD_Fehler_Radsensor_VR 1;
BA_ "GenSigSwitchedByIgnition" SG_ 914 ESP_Qualifizierung_Antriebsart 0;
BA_ "GenSigSendType" SG_ 914 ESP_Qualifizierung_Antriebsart 0;
BA_ "GenSigAutoGenSnd" SG_ 914 ESP_Qualifizierung_Antriebsart 1;
BA_ "GenSigAutoGenDsp" SG_ 914 ESP_Qualifizierung_Antriebsart 1;
BA_ "GenSigSwitchedByIgnition" SG_ 914 ESP_Offroad_Modus 0;
BA_ "GenSigSendType" SG_ 914 ESP_Offroad_Modus 0;
BA_ "GenSigSwitchedByIgnition" SG_ 914 ESP_MKB_ausloesbar 0;
BA_ "GenSigSendType" SG_ 914 ESP_MKB_ausloesbar 0;
BA_ "GenSigSwitchedByIgnition" SG_ 914 ESP_MKB_Status 0;
BA_ "GenSigSendType" SG_ 914 ESP_MKB_Status 0;
BA_ "GenSigSwitchedByIgnition" SG_ 914 ESP_CM_Variante 0;
BA_ "GenSigSendType" SG_ 914 ESP_CM_Variante 0;
BA_ "GenSigSwitchedByIgnition" SG_ 914 ESP_OBD_Status 0;
BA_ "GenSigSendType" SG_ 914 ESP_OBD_Status 0;
BA_ "GenSigEnvVarType" SG_ 914 ESP_OBD_Status 0;
BA_ "GenSigAutoGenSnd" SG_ 914 ESP_OBD_Status 1;
BA_ "GenSigAutoGenDsp" SG_ 914 ESP_OBD_Status 1;
BA_ "GenSigSwitchedByIgnition" SG_ 278 ESP_10_CRC 0;
BA_ "GenSigFuncType" SG_ 278 ESP_10_CRC 2;
BA_ "GenSigSendType" SG_ 278 ESP_10_CRC 0;
BA_ "GenSigEnvVarType" SG_ 278 ESP_10_CRC 0;
BA_ "GenSigAutoGenSnd" SG_ 278 ESP_10_CRC 1;
BA_ "GenSigAutoGenDsp" SG_ 278 ESP_10_CRC 1;
BA_ "GenSigSwitchedByIgnition" SG_ 278 ESP_10_BZ 0;
BA_ "GenSigFuncType" SG_ 278 ESP_10_BZ 1;
BA_ "GenSigSendType" SG_ 278 ESP_10_BZ 0;
BA_ "GenSigEnvVarType" SG_ 278 ESP_10_BZ 0;
BA_ "GenSigAutoGenSnd" SG_ 278 ESP_10_BZ 1;
BA_ "GenSigAutoGenDsp" SG_ 278 ESP_10_BZ 1;
BA_ "GenSigSwitchedByIgnition" SG_ 278 ESP_QBit_Wegimpuls_VL 0;
BA_ "GenSigStartValue" SG_ 278 ESP_QBit_Wegimpuls_VL 1;
BA_ "GenSigSendType" SG_ 278 ESP_QBit_Wegimpuls_VL 0;
BA_ "GenSigEnvVarType" SG_ 278 ESP_QBit_Wegimpuls_VL 0;
BA_ "GenSigAutoGenSnd" SG_ 278 ESP_QBit_Wegimpuls_VL 1;
BA_ "GenSigAutoGenDsp" SG_ 278 ESP_QBit_Wegimpuls_VL 1;
BA_ "GenSigSwitchedByIgnition" SG_ 278 ESP_QBit_Wegimpuls_VR 0;
BA_ "GenSigStartValue" SG_ 278 ESP_QBit_Wegimpuls_VR 1;
BA_ "GenSigSendType" SG_ 278 ESP_QBit_Wegimpuls_VR 0;
BA_ "GenSigEnvVarType" SG_ 278 ESP_QBit_Wegimpuls_VR 0;
BA_ "GenSigAutoGenSnd" SG_ 278 ESP_QBit_Wegimpuls_VR 1;
BA_ "GenSigAutoGenDsp" SG_ 278 ESP_QBit_Wegimpuls_VR 1;
BA_ "GenSigSwitchedByIgnition" SG_ 278 ESP_QBit_Wegimpuls_HL 0;
BA_ "GenSigStartValue" SG_ 278 ESP_QBit_Wegimpuls_HL 1;
BA_ "GenSigSendType" SG_ 278 ESP_QBit_Wegimpuls_HL 0;
BA_ "GenSigEnvVarType" SG_ 278 ESP_QBit_Wegimpuls_HL 0;
BA_ "GenSigAutoGenSnd" SG_ 278 ESP_QBit_Wegimpuls_HL 1;
BA_ "GenSigAutoGenDsp" SG_ 278 ESP_QBit_Wegimpuls_HL 1;
BA_ "GenSigSwitchedByIgnition" SG_ 278 ESP_QBit_Wegimpuls_HR 0;
BA_ "GenSigStartValue" SG_ 278 ESP_QBit_Wegimpuls_HR 1;
BA_ "GenSigSendType" SG_ 278 ESP_QBit_Wegimpuls_HR 0;
BA_ "GenSigEnvVarType" SG_ 278 ESP_QBit_Wegimpuls_HR 0;
BA_ "GenSigAutoGenSnd" SG_ 278 ESP_QBit_Wegimpuls_HR 1;
BA_ "GenSigAutoGenDsp" SG_ 278 ESP_QBit_Wegimpuls_HR 1;
BA_ "Fehlerwert" SG_ 278 ESP_Wegimpuls_VL 1023;
BA_ "GenSigSwitchedByIgnition" SG_ 278 ESP_Wegimpuls_VL 0;
BA_ "GenSigStartValue" SG_ 278 ESP_Wegimpuls_VL 1021;
BA_ "GenSigSendType" SG_ 278 ESP_Wegimpuls_VL 0;
BA_ "GenSigEnvVarType" SG_ 278 ESP_Wegimpuls_VL 0;
BA_ "GenSigAutoGenSnd" SG_ 278 ESP_Wegimpuls_VL 1;
BA_ "GenSigAutoGenDsp" SG_ 278 ESP_Wegimpuls_VL 1;
BA_ "Fehlerwert" SG_ 278 ESP_Wegimpuls_VR 1023;
BA_ "GenSigSwitchedByIgnition" SG_ 278 ESP_Wegimpuls_VR 0;
BA_ "GenSigStartValue" SG_ 278 ESP_Wegimpuls_VR 1021;
BA_ "GenSigSendType" SG_ 278 ESP_Wegimpuls_VR 0;
BA_ "GenSigEnvVarType" SG_ 278 ESP_Wegimpuls_VR 0;
BA_ "GenSigAutoGenSnd" SG_ 278 ESP_Wegimpuls_VR 1;
BA_ "GenSigAutoGenDsp" SG_ 278 ESP_Wegimpuls_VR 1;
BA_ "Fehlerwert" SG_ 278 ESP_Wegimpuls_HL 1023;
BA_ "GenSigSwitchedByIgnition" SG_ 278 ESP_Wegimpuls_HL 0;
BA_ "GenSigStartValue" SG_ 278 ESP_Wegimpuls_HL 1021;
BA_ "GenSigSendType" SG_ 278 ESP_Wegimpuls_HL 0;
BA_ "GenSigEnvVarType" SG_ 278 ESP_Wegimpuls_HL 0;
BA_ "GenSigAutoGenSnd" SG_ 278 ESP_Wegimpuls_HL 1;
BA_ "GenSigAutoGenDsp" SG_ 278 ESP_Wegimpuls_HL 1;
BA_ "Fehlerwert" SG_ 278 ESP_Wegimpuls_HR 1023;
BA_ "GenSigSwitchedByIgnition" SG_ 278 ESP_Wegimpuls_HR 0;
BA_ "GenSigStartValue" SG_ 278 ESP_Wegimpuls_HR 1021;
BA_ "GenSigSendType" SG_ 278 ESP_Wegimpuls_HR 0;
BA_ "GenSigEnvVarType" SG_ 278 ESP_Wegimpuls_HR 0;
BA_ "GenSigAutoGenSnd" SG_ 278 ESP_Wegimpuls_HR 1;
BA_ "GenSigAutoGenDsp" SG_ 278 ESP_Wegimpuls_HR 1;
BA_ "GenSigSwitchedByIgnition" SG_ 278 ESP_VL_Fahrtrichtung 0;
BA_ "GenSigStartValue" SG_ 278 ESP_VL_Fahrtrichtung 2;
BA_ "GenSigSendType" SG_ 278 ESP_VL_Fahrtrichtung 0;
BA_ "GenSigEnvVarType" SG_ 278 ESP_VL_Fahrtrichtung 0;
BA_ "GenSigAutoGenSnd" SG_ 278 ESP_VL_Fahrtrichtung 1;
BA_ "GenSigAutoGenDsp" SG_ 278 ESP_VL_Fahrtrichtung 1;
BA_ "GenSigSwitchedByIgnition" SG_ 278 ESP_VR_Fahrtrichtung 0;
BA_ "GenSigStartValue" SG_ 278 ESP_VR_Fahrtrichtung 2;
BA_ "GenSigSendType" SG_ 278 ESP_VR_Fahrtrichtung 0;
BA_ "GenSigEnvVarType" SG_ 278 ESP_VR_Fahrtrichtung 0;
BA_ "GenSigAutoGenSnd" SG_ 278 ESP_VR_Fahrtrichtung 1;
BA_ "GenSigAutoGenDsp" SG_ 278 ESP_VR_Fahrtrichtung 1;
BA_ "GenSigSwitchedByIgnition" SG_ 278 ESP_HL_Fahrtrichtung 0;
BA_ "GenSigStartValue" SG_ 278 ESP_HL_Fahrtrichtung 2;
BA_ "GenSigSendType" SG_ 278 ESP_HL_Fahrtrichtung 0;
BA_ "GenSigEnvVarType" SG_ 278 ESP_HL_Fahrtrichtung 0;
BA_ "GenSigAutoGenSnd" SG_ 278 ESP_HL_Fahrtrichtung 1;
BA_ "GenSigAutoGenDsp" SG_ 278 ESP_HL_Fahrtrichtung 1;
BA_ "GenSigSwitchedByIgnition" SG_ 278 ESP_HR_Fahrtrichtung 0;
BA_ "GenSigStartValue" SG_ 278 ESP_HR_Fahrtrichtung 2;
BA_ "GenSigSendType" SG_ 278 ESP_HR_Fahrtrichtung 0;
BA_ "GenSigEnvVarType" SG_ 278 ESP_HR_Fahrtrichtung 0;
BA_ "GenSigAutoGenSnd" SG_ 278 ESP_HR_Fahrtrichtung 1;
BA_ "GenSigAutoGenDsp" SG_ 278 ESP_HR_Fahrtrichtung 1;
BA_ "Fehlerwert" SG_ 178 ESP_HL_Radgeschw_02 65535;
BA_ "GenSigSwitchedByIgnition" SG_ 178 ESP_HL_Radgeschw_02 0;
BA_ "GenSigStartValue" SG_ 178 ESP_HL_Radgeschw_02 65534;
BA_ "GenSigSendType" SG_ 178 ESP_HL_Radgeschw_02 0;
BA_ "GenSigEnvVarType" SG_ 178 ESP_HL_Radgeschw_02 1;
BA_ "GenSigAutoGenSnd" SG_ 178 ESP_HL_Radgeschw_02 1;
BA_ "GenSigAutoGenDsp" SG_ 178 ESP_HL_Radgeschw_02 1;
BA_ "Fehlerwert" SG_ 178 ESP_HR_Radgeschw_02 65535;
BA_ "GenSigSwitchedByIgnition" SG_ 178 ESP_HR_Radgeschw_02 0;
BA_ "GenSigStartValue" SG_ 178 ESP_HR_Radgeschw_02 65534;
BA_ "GenSigSendType" SG_ 178 ESP_HR_Radgeschw_02 0;
BA_ "GenSigEnvVarType" SG_ 178 ESP_HR_Radgeschw_02 1;
BA_ "GenSigAutoGenSnd" SG_ 178 ESP_HR_Radgeschw_02 1;
BA_ "GenSigAutoGenDsp" SG_ 178 ESP_HR_Radgeschw_02 1;
BA_ "Fehlerwert" SG_ 178 ESP_VL_Radgeschw_02 65535;
BA_ "GenSigSwitchedByIgnition" SG_ 178 ESP_VL_Radgeschw_02 0;
BA_ "GenSigStartValue" SG_ 178 ESP_VL_Radgeschw_02 65534;
BA_ "GenSigSendType" SG_ 178 ESP_VL_Radgeschw_02 0;
BA_ "GenSigEnvVarType" SG_ 178 ESP_VL_Radgeschw_02 1;
BA_ "GenSigAutoGenSnd" SG_ 178 ESP_VL_Radgeschw_02 1;
BA_ "GenSigAutoGenDsp" SG_ 178 ESP_VL_Radgeschw_02 1;
BA_ "Fehlerwert" SG_ 178 ESP_VR_Radgeschw_02 65535;
BA_ "GenSigSwitchedByIgnition" SG_ 178 ESP_VR_Radgeschw_02 0;
BA_ "GenSigStartValue" SG_ 178 ESP_VR_Radgeschw_02 65534;
BA_ "GenSigSendType" SG_ 178 ESP_VR_Radgeschw_02 0;
BA_ "GenSigEnvVarType" SG_ 178 ESP_VR_Radgeschw_02 1;
BA_ "GenSigAutoGenSnd" SG_ 178 ESP_VR_Radgeschw_02 1;
BA_ "GenSigAutoGenDsp" SG_ 178 ESP_VR_Radgeschw_02 1;
BA_ "GenSigSwitchedByIgnition" SG_ 1629 ESP_20_CRC 0;
BA_ "GenSigFuncType" SG_ 1629 ESP_20_CRC 2;
BA_ "GenSigSendType" SG_ 1629 ESP_20_CRC 0;
BA_ "GenSigEnvVarType" SG_ 1629 ESP_20_CRC 0;
BA_ "GenSigAutoGenSnd" SG_ 1629 ESP_20_CRC 1;
BA_ "GenSigAutoGenDsp" SG_ 1629 ESP_20_CRC 1;
BA_ "GenSigSwitchedByIgnition" SG_ 1629 ESP_20_BZ 0;
BA_ "GenSigFuncType" SG_ 1629 ESP_20_BZ 1;
BA_ "GenSigSendType" SG_ 1629 ESP_20_BZ 0;
BA_ "GenSigEnvVarType" SG_ 1629 ESP_20_BZ 0;
BA_ "GenSigAutoGenSnd" SG_ 1629 ESP_20_BZ 1;
BA_ "GenSigAutoGenDsp" SG_ 1629 ESP_20_BZ 1;
BA_ "GenSigSwitchedByIgnition" SG_ 1629 BR_Systemart 0;
BA_ "GenSigFuncType" SG_ 1629 BR_Systemart 8;
BA_ "GenSigSendType" SG_ 1629 BR_Systemart 0;
BA_ "GenSigAutoGenSnd" SG_ 1629 BR_Systemart 1;
BA_ "GenSigAutoGenDsp" SG_ 1629 BR_Systemart 1;
BA_ "GenSigSwitchedByIgnition" SG_ 1629 ESP_Zaehnezahl 0;
BA_ "GenSigFuncType" SG_ 1629 ESP_Zaehnezahl 8;
BA_ "GenSigSendType" SG_ 1629 ESP_Zaehnezahl 0;
BA_ "GenSigEnvVarType" SG_ 1629 ESP_Zaehnezahl 0;
BA_ "GenSigAutoGenSnd" SG_ 1629 ESP_Zaehnezahl 1;
BA_ "GenSigAutoGenDsp" SG_ 1629 ESP_Zaehnezahl 1;
BA_ "GenSigSwitchedByIgnition" SG_ 1629 ESP_Charisma_FahrPr 0;
BA_ "GenSigSendType" SG_ 1629 ESP_Charisma_FahrPr 0;
BA_ "GenSigAutoGenSnd" SG_ 1629 ESP_Charisma_FahrPr 1;
BA_ "GenSigAutoGenDsp" SG_ 1629 ESP_Charisma_FahrPr 1;
BA_ "GenSigSwitchedByIgnition" SG_ 1629 ESP_Charisma_Status 0;
BA_ "GenSigSendType" SG_ 1629 ESP_Charisma_Status 0;
BA_ "GenSigAutoGenSnd" SG_ 1629 ESP_Charisma_Status 1;
BA_ "GenSigAutoGenDsp" SG_ 1629 ESP_Charisma_Status 1;
BA_ "GenSigSwitchedByIgnition" SG_ 1629 BR_QBit_Reifenumfang 0;
BA_ "GenSigStartValue" SG_ 1629 BR_QBit_Reifenumfang 1;
BA_ "GenSigSendType" SG_ 1629 BR_QBit_Reifenumfang 0;
BA_ "GenSigEnvVarType" SG_ 1629 BR_QBit_Reifenumfang 0;
BA_ "GenSigAutoGenSnd" SG_ 1629 BR_QBit_Reifenumfang 1;
BA_ "GenSigAutoGenDsp" SG_ 1629 BR_QBit_Reifenumfang 1;
BA_ "GenSigSwitchedByIgnition" SG_ 1629 BR_Reifenumfang 0;
BA_ "GenSigSendType" SG_ 1629 BR_Reifenumfang 0;
BA_ "GenSigEnvVarType" SG_ 1629 BR_Reifenumfang 0;
BA_ "GenSigAutoGenSnd" SG_ 1629 BR_Reifenumfang 1;
BA_ "GenSigAutoGenDsp" SG_ 1629 BR_Reifenumfang 1;
BA_ "GenSigSwitchedByIgnition" SG_ 253 ESP_21_CRC 0;
BA_ "GenSigFuncType" SG_ 253 ESP_21_CRC 2;
BA_ "GenSigSendType" SG_ 253 ESP_21_CRC 0;
BA_ "GenSigEnvVarType" SG_ 253 ESP_21_CRC 0;
BA_ "GenSigAutoGenSnd" SG_ 253 ESP_21_CRC 1;
BA_ "GenSigAutoGenDsp" SG_ 253 ESP_21_CRC 1;
BA_ "GenSigSwitchedByIgnition" SG_ 253 ESP_21_BZ 0;
BA_ "GenSigFuncType" SG_ 253 ESP_21_BZ 1;
BA_ "GenSigSendType" SG_ 253 ESP_21_BZ 0;
BA_ "GenSigEnvVarType" SG_ 253 ESP_21_BZ 0;
BA_ "GenSigAutoGenSnd" SG_ 253 ESP_21_BZ 1;
BA_ "GenSigAutoGenDsp" SG_ 253 ESP_21_BZ 1;
BA_ "Fehlerwert" SG_ 253 BR_Eingriffsmoment 1023;
BA_ "GenSigSwitchedByIgnition" SG_ 253 BR_Eingriffsmoment 0;
BA_ "GenSigStartValue" SG_ 253 BR_Eingriffsmoment 1022;
BA_ "GenSigSendType" SG_ 253 BR_Eingriffsmoment 0;
BA_ "GenSigEnvVarType" SG_ 253 BR_Eingriffsmoment 0;
BA_ "GenSigAutoGenSnd" SG_ 253 BR_Eingriffsmoment 1;
BA_ "GenSigAutoGenDsp" SG_ 253 BR_Eingriffsmoment 1;
BA_ "GenSigMissingSourceValue" SG_ 253 ESP_v_Signal 65534;
BA_ "Fehlerwert" SG_ 253 ESP_v_Signal 65535;
BA_ "GenSigSwitchedByIgnition" SG_ 253 ESP_v_Signal 0;
BA_ "GenSigStartValue" SG_ 253 ESP_v_Signal 65534;
BA_ "GenSigSendType" SG_ 253 ESP_v_Signal 0;
BA_ "GenSigEnvVarType" SG_ 253 ESP_v_Signal 1;
BA_ "GenSigAutoGenSnd" SG_ 253 ESP_v_Signal 1;
BA_ "GenSigAutoGenDsp" SG_ 253 ESP_v_Signal 1;
BA_ "GenSigSwitchedByIgnition" SG_ 253 ASR_Tastung_passiv 0;
BA_ "GenSigSendType" SG_ 253 ASR_Tastung_passiv 0;
BA_ "GenSigEnvVarType" SG_ 253 ASR_Tastung_passiv 0;
BA_ "GenSigAutoGenSnd" SG_ 253 ASR_Tastung_passiv 1;
BA_ "GenSigAutoGenDsp" SG_ 253 ASR_Tastung_passiv 1;
BA_ "GenSigSwitchedByIgnition" SG_ 253 ESP_Tastung_passiv 0;
BA_ "GenSigSendType" SG_ 253 ESP_Tastung_passiv 0;
BA_ "GenSigEnvVarType" SG_ 253 ESP_Tastung_passiv 0;
BA_ "GenSigAutoGenSnd" SG_ 253 ESP_Tastung_passiv 1;
BA_ "GenSigAutoGenDsp" SG_ 253 ESP_Tastung_passiv 1;
BA_ "GenSigSwitchedByIgnition" SG_ 253 ESP_Systemstatus 0;
BA_ "GenSigSendType" SG_ 253 ESP_Systemstatus 0;
BA_ "GenSigEnvVarType" SG_ 253 ESP_Systemstatus 0;
BA_ "GenSigAutoGenSnd" SG_ 253 ESP_Systemstatus 1;
BA_ "GenSigAutoGenDsp" SG_ 253 ESP_Systemstatus 1;
BA_ "GenSigSwitchedByIgnition" SG_ 253 ASR_Schalteingriff 0;
BA_ "GenSigSendType" SG_ 253 ASR_Schalteingriff 0;
BA_ "GenSigEnvVarType" SG_ 253 ASR_Schalteingriff 0;
BA_ "GenSigAutoGenSnd" SG_ 253 ASR_Schalteingriff 1;
BA_ "GenSigAutoGenDsp" SG_ 253 ASR_Schalteingriff 1;
BA_ "GenSigSwitchedByIgnition" SG_ 253 ESP_Haltebestaetigung 0;
BA_ "GenSigSendType" SG_ 253 ESP_Haltebestaetigung 0;
BA_ "GenSigAutoGenSnd" SG_ 253 ESP_Haltebestaetigung 1;
BA_ "GenSigAutoGenDsp" SG_ 253 ESP_Haltebestaetigung 1;
BA_ "GenSigSwitchedByIgnition" SG_ 253 ESP_QBit_v_Signal 0;
BA_ "GenSigStartValue" SG_ 253 ESP_QBit_v_Signal 1;
BA_ "GenSigSendType" SG_ 253 ESP_QBit_v_Signal 0;
BA_ "GenSigEnvVarType" SG_ 253 ESP_QBit_v_Signal 0;
BA_ "GenSigAutoGenSnd" SG_ 253 ESP_QBit_v_Signal 1;
BA_ "GenSigAutoGenDsp" SG_ 253 ESP_QBit_v_Signal 1;
BA_ "GenSigSwitchedByIgnition" SG_ 253 ABS_Bremsung 0;
BA_ "GenSigSendType" SG_ 253 ABS_Bremsung 0;
BA_ "GenSigEnvVarType" SG_ 253 ABS_Bremsung 0;
BA_ "GenSigAutoGenSnd" SG_ 253 ABS_Bremsung 1;
BA_ "GenSigAutoGenDsp" SG_ 253 ABS_Bremsung 1;
BA_ "GenSigSwitchedByIgnition" SG_ 253 ASR_Anf 0;
BA_ "GenSigSendType" SG_ 253 ASR_Anf 0;
BA_ "GenSigEnvVarType" SG_ 253 ASR_Anf 0;
BA_ "GenSigAutoGenSnd" SG_ 253 ASR_Anf 1;
BA_ "GenSigAutoGenDsp" SG_ 253 ASR_Anf 1;
BA_ "GenSigSwitchedByIgnition" SG_ 253 MSR_Anf 0;
BA_ "GenSigSendType" SG_ 253 MSR_Anf 0;
BA_ "GenSigEnvVarType" SG_ 253 MSR_Anf 0;
BA_ "GenSigAutoGenSnd" SG_ 253 MSR_Anf 1;
BA_ "GenSigAutoGenDsp" SG_ 253 MSR_Anf 1;
BA_ "GenSigSwitchedByIgnition" SG_ 253 EBV_Eingriff 0;
BA_ "GenSigSendType" SG_ 253 EBV_Eingriff 0;
BA_ "GenSigEnvVarType" SG_ 253 EBV_Eingriff 0;
BA_ "GenSigAutoGenSnd" SG_ 253 EBV_Eingriff 1;
BA_ "GenSigAutoGenDsp" SG_ 253 EBV_Eingriff 1;
BA_ "GenSigSwitchedByIgnition" SG_ 253 EDS_Eingriff 0;
BA_ "GenSigSendType" SG_ 253 EDS_Eingriff 0;
BA_ "GenSigEnvVarType" SG_ 253 EDS_Eingriff 0;
BA_ "GenSigAutoGenSnd" SG_ 253 EDS_Eingriff 1;
BA_ "GenSigAutoGenDsp" SG_ 253 EDS_Eingriff 1;
BA_ "GenSigSwitchedByIgnition" SG_ 253 ESP_Eingriff 0;
BA_ "GenSigSendType" SG_ 253 ESP_Eingriff 0;
BA_ "GenSigEnvVarType" SG_ 253 ESP_Eingriff 0;
BA_ "GenSigAutoGenSnd" SG_ 253 ESP_Eingriff 1;
BA_ "GenSigAutoGenDsp" SG_ 253 ESP_Eingriff 1;
BA_ "GenSigSwitchedByIgnition" SG_ 253 ESP_ASP 0;
BA_ "GenSigSendType" SG_ 253 ESP_ASP 0;
BA_ "GenSigEnvVarType" SG_ 253 ESP_ASP 0;
BA_ "GenSigAutoGenSnd" SG_ 253 ESP_ASP 1;
BA_ "GenSigAutoGenDsp" SG_ 253 ESP_ASP 1;
BA_ "GenSigSwitchedByIgnition" SG_ 253 ESP_Anhaltevorgang_ACC_aktiv 0;
BA_ "GenSigSendType" SG_ 253 ESP_Anhaltevorgang_ACC_aktiv 0;
BA_ "GenSigEnvVarType" SG_ 253 ESP_Anhaltevorgang_ACC_aktiv 0;
BA_ "GenSigSwitchedByIgnition" SG_ 987 BCM_01_alt 0;
BA_ "GenSigFuncType" SG_ 987 BCM_01_alt 5;
BA_ "GenSigStartValue" SG_ 987 BCM_01_alt 1;
BA_ "GenSigSendType" SG_ 987 BCM_01_alt 0;
BA_ "GenSigEnvVarType" SG_ 987 BCM_01_alt 0;
BA_ "GenSigAutoGenSnd" SG_ 987 BCM_01_alt 1;
BA_ "GenSigAutoGenDsp" SG_ 987 BCM_01_alt 1;
BA_ "GenSigSwitchedByIgnition" SG_ 987 SMLS_01_alt 0;
BA_ "GenSigFuncType" SG_ 987 SMLS_01_alt 5;
BA_ "GenSigStartValue" SG_ 987 SMLS_01_alt 1;
BA_ "GenSigSendType" SG_ 987 SMLS_01_alt 0;
BA_ "GenSigEnvVarType" SG_ 987 SMLS_01_alt 0;
BA_ "GenSigAutoGenSnd" SG_ 987 SMLS_01_alt 1;
BA_ "GenSigAutoGenDsp" SG_ 987 SMLS_01_alt 1;
BA_ "GenSigSwitchedByIgnition" SG_ 987 ZV_02_alt 0;
BA_ "GenSigFuncType" SG_ 987 ZV_02_alt 5;
BA_ "GenSigStartValue" SG_ 987 ZV_02_alt 1;
BA_ "GenSigSendType" SG_ 987 ZV_02_alt 0;
BA_ "GenSigEnvVarType" SG_ 987 ZV_02_alt 0;
BA_ "GenSigAutoGenSnd" SG_ 987 ZV_02_alt 1;
BA_ "GenSigAutoGenDsp" SG_ 987 ZV_02_alt 1;
BA_ "GenSigSwitchedByIgnition" SG_ 987 Wischer_01_alt 0;
BA_ "GenSigFuncType" SG_ 987 Wischer_01_alt 5;
BA_ "GenSigStartValue" SG_ 987 Wischer_01_alt 1;
BA_ "GenSigSendType" SG_ 987 Wischer_01_alt 0;
BA_ "GenSigEnvVarType" SG_ 987 Wischer_01_alt 0;
BA_ "GenSigAutoGenSnd" SG_ 987 Wischer_01_alt 1;
BA_ "GenSigAutoGenDsp" SG_ 987 Wischer_01_alt 1;
BA_ "GenSigSwitchedByIgnition" SG_ 987 Anhaenger_01_alt 0;
BA_ "GenSigFuncType" SG_ 987 Anhaenger_01_alt 5;
BA_ "GenSigStartValue" SG_ 987 Anhaenger_01_alt 1;
BA_ "GenSigSendType" SG_ 987 Anhaenger_01_alt 0;
BA_ "GenSigEnvVarType" SG_ 987 Anhaenger_01_alt 0;
BA_ "GenSigAutoGenSnd" SG_ 987 Anhaenger_01_alt 1;
BA_ "GenSigAutoGenDsp" SG_ 987 Anhaenger_01_alt 1;
BA_ "GenSigSwitchedByIgnition" SG_ 987 Klima_Sensor_02_alt 0;
BA_ "GenSigFuncType" SG_ 987 Klima_Sensor_02_alt 5;
BA_ "GenSigStartValue" SG_ 987 Klima_Sensor_02_alt 1;
BA_ "GenSigSendType" SG_ 987 Klima_Sensor_02_alt 0;
BA_ "GenSigEnvVarType" SG_ 987 Klima_Sensor_02_alt 0;
BA_ "GenSigAutoGenSnd" SG_ 987 Klima_Sensor_02_alt 1;
BA_ "GenSigAutoGenDsp" SG_ 987 Klima_Sensor_02_alt 1;
BA_ "GenSigSwitchedByIgnition" SG_ 987 VSG_01_alt 0;
BA_ "GenSigFuncType" SG_ 987 VSG_01_alt 5;
BA_ "GenSigStartValue" SG_ 987 VSG_01_alt 1;
BA_ "GenSigSendType" SG_ 987 VSG_01_alt 0;
BA_ "GenSigEnvVarType" SG_ 987 VSG_01_alt 0;
BA_ "GenSigAutoGenSnd" SG_ 987 VSG_01_alt 1;
BA_ "GenSigAutoGenDsp" SG_ 987 VSG_01_alt 1;
BA_ "GenSigSwitchedByIgnition" SG_ 987 Klima_01_alt 0;
BA_ "GenSigFuncType" SG_ 987 Klima_01_alt 5;
BA_ "GenSigStartValue" SG_ 987 Klima_01_alt 1;
BA_ "GenSigSendType" SG_ 987 Klima_01_alt 0;
BA_ "GenSigEnvVarType" SG_ 987 Klima_01_alt 0;
BA_ "GenSigAutoGenSnd" SG_ 987 Klima_01_alt 1;
BA_ "GenSigAutoGenDsp" SG_ 987 Klima_01_alt 1;
BA_ "GenSigSwitchedByIgnition" SG_ 987 WFS_01_alt 0;
BA_ "GenSigFuncType" SG_ 987 WFS_01_alt 5;
BA_ "GenSigStartValue" SG_ 987 WFS_01_alt 1;
BA_ "GenSigSendType" SG_ 987 WFS_01_alt 0;
BA_ "GenSigEnvVarType" SG_ 987 WFS_01_alt 0;
BA_ "GenSigAutoGenSnd" SG_ 987 WFS_01_alt 1;
BA_ "GenSigAutoGenDsp" SG_ 987 WFS_01_alt 1;
BA_ "GenSigSwitchedByIgnition" SG_ 987 Licht_Anf_01_alt 0;
BA_ "GenSigFuncType" SG_ 987 Licht_Anf_01_alt 5;
BA_ "GenSigStartValue" SG_ 987 Licht_Anf_01_alt 1;
BA_ "GenSigSendType" SG_ 987 Licht_Anf_01_alt 0;
BA_ "GenSigEnvVarType" SG_ 987 Licht_Anf_01_alt 0;
BA_ "GenSigAutoGenSnd" SG_ 987 Licht_Anf_01_alt 1;
BA_ "GenSigAutoGenDsp" SG_ 987 Licht_Anf_01_alt 1;
BA_ "GenSigSwitchedByIgnition" SG_ 987 ZV_HFS_offen 0;
BA_ "GenSigSendType" SG_ 987 ZV_HFS_offen 3;
BA_ "GenSigEnvVarType" SG_ 987 ZV_HFS_offen 0;
BA_ "GenSigAutoGenSnd" SG_ 987 ZV_HFS_offen 1;
BA_ "GenSigAutoGenDsp" SG_ 987 ZV_HFS_offen 1;
BA_ "GenSigSwitchedByIgnition" SG_ 987 ZV_HBFS_offen 0;
BA_ "GenSigSendType" SG_ 987 ZV_HBFS_offen 3;
BA_ "GenSigEnvVarType" SG_ 987 ZV_HBFS_offen 0;
BA_ "GenSigAutoGenSnd" SG_ 987 ZV_HBFS_offen 1;
BA_ "GenSigAutoGenDsp" SG_ 987 ZV_HBFS_offen 1;
BA_ "GenSigSwitchedByIgnition" SG_ 987 VS_VD_offen_ver 0;
BA_ "GenSigSendType" SG_ 987 VS_VD_offen_ver 3;
BA_ "GenSigEnvVarType" SG_ 987 VS_VD_offen_ver 0;
BA_ "GenSigAutoGenSnd" SG_ 987 VS_VD_offen_ver 1;
BA_ "GenSigAutoGenDsp" SG_ 987 VS_VD_offen_ver 1;
BA_ "GenSigSwitchedByIgnition" SG_ 987 VS_VD_zu_ver 0;
BA_ "GenSigSendType" SG_ 987 VS_VD_zu_ver 3;
BA_ "GenSigEnvVarType" SG_ 987 VS_VD_zu_ver 0;
BA_ "GenSigAutoGenSnd" SG_ 987 VS_VD_zu_ver 1;
BA_ "GenSigAutoGenDsp" SG_ 987 VS_VD_zu_ver 1;
BA_ "GenSigSwitchedByIgnition" SG_ 987 ZV_BT_offen 0;
BA_ "GenSigSendType" SG_ 987 ZV_BT_offen 3;
BA_ "GenSigEnvVarType" SG_ 987 ZV_BT_offen 0;
BA_ "GenSigAutoGenSnd" SG_ 987 ZV_BT_offen 1;
BA_ "GenSigAutoGenDsp" SG_ 987 ZV_BT_offen 1;
BA_ "GenSigSwitchedByIgnition" SG_ 987 BCM1_Rueckfahrlicht_Schalter 0;
BA_ "GenSigSendType" SG_ 987 BCM1_Rueckfahrlicht_Schalter 3;
BA_ "GenSigEnvVarType" SG_ 987 BCM1_Rueckfahrlicht_Schalter 0;
BA_ "GenSigAutoGenSnd" SG_ 987 BCM1_Rueckfahrlicht_Schalter 1;
BA_ "GenSigAutoGenDsp" SG_ 987 BCM1_Rueckfahrlicht_Schalter 1;
BA_ "GenSigSwitchedByIgnition" SG_ 987 ZV_FT_offen 0;
BA_ "GenSigSendType" SG_ 987 ZV_FT_offen 3;
BA_ "GenSigEnvVarType" SG_ 987 ZV_FT_offen 0;
BA_ "GenSigAutoGenSnd" SG_ 987 ZV_FT_offen 1;
BA_ "GenSigAutoGenDsp" SG_ 987 ZV_FT_offen 1;
BA_ "GenSigSwitchedByIgnition" SG_ 987 Wischer_vorne_aktiv 0;
BA_ "GenSigSendType" SG_ 987 Wischer_vorne_aktiv 3;
BA_ "GenSigEnvVarType" SG_ 987 Wischer_vorne_aktiv 0;
BA_ "GenSigAutoGenSnd" SG_ 987 Wischer_vorne_aktiv 1;
BA_ "GenSigAutoGenDsp" SG_ 987 Wischer_vorne_aktiv 1;
BA_ "GenSigSwitchedByIgnition" SG_ 987 AAG_Anhaenger_erkannt 0;
BA_ "GenSigSendType" SG_ 987 AAG_Anhaenger_erkannt 0;
BA_ "GenSigEnvVarType" SG_ 987 AAG_Anhaenger_erkannt 0;
BA_ "GenSigAutoGenSnd" SG_ 987 AAG_Anhaenger_erkannt 1;
BA_ "GenSigAutoGenDsp" SG_ 987 AAG_Anhaenger_erkannt 1;
BA_ "GenSigSwitchedByIgnition" SG_ 987 BCM1_MH_Schalter 0;
BA_ "GenSigSendType" SG_ 987 BCM1_MH_Schalter 3;
BA_ "GenSigEnvVarType" SG_ 987 BCM1_MH_Schalter 0;
BA_ "GenSigAutoGenSnd" SG_ 987 BCM1_MH_Schalter 1;
BA_ "GenSigAutoGenDsp" SG_ 987 BCM1_MH_Schalter 1;
BA_ "GenSigSwitchedByIgnition" SG_ 987 ZV_HD_offen 0;
BA_ "GenSigSendType" SG_ 987 ZV_HD_offen 3;
BA_ "GenSigEnvVarType" SG_ 987 ZV_HD_offen 0;
BA_ "GenSigAutoGenSnd" SG_ 987 ZV_HD_offen 1;
BA_ "GenSigAutoGenDsp" SG_ 987 ZV_HD_offen 1;
BA_ "GenSigSwitchedByIgnition" SG_ 987 Waschen_vorne_aktiv 0;
BA_ "GenSigSendType" SG_ 987 Waschen_vorne_aktiv 3;
BA_ "GenSigEnvVarType" SG_ 987 Waschen_vorne_aktiv 0;
BA_ "GenSigAutoGenSnd" SG_ 987 Waschen_vorne_aktiv 1;
BA_ "GenSigAutoGenDsp" SG_ 987 Waschen_vorne_aktiv 1;
BA_ "GenSigSwitchedByIgnition" SG_ 987 KL_Thermomanagement 0;
BA_ "GenSigSendType" SG_ 987 KL_Thermomanagement 0;
BA_ "GenSigEnvVarType" SG_ 987 KL_Thermomanagement 0;
BA_ "GenSigAutoGenSnd" SG_ 987 KL_Thermomanagement 1;
BA_ "GenSigAutoGenDsp" SG_ 987 KL_Thermomanagement 1;
BA_ "GenSigSwitchedByIgnition" SG_ 987 WFS_Schluessel_Fahrberecht 0;
BA_ "GenSigSendType" SG_ 987 WFS_Schluessel_Fahrberecht 0;
BA_ "GenSigAutoGenSnd" SG_ 987 WFS_Schluessel_Fahrberecht 1;
BA_ "GenSigAutoGenDsp" SG_ 987 WFS_Schluessel_Fahrberecht 1;
BA_ "GenSigSwitchedByIgnition" SG_ 987 BCM1_RFahrlicht_Fzg_Anf 0;
BA_ "GenSigSendType" SG_ 987 BCM1_RFahrlicht_Fzg_Anf 0;
BA_ "GenSigEnvVarType" SG_ 987 BCM1_RFahrlicht_Fzg_Anf 0;
BA_ "GenSigAutoGenSnd" SG_ 987 BCM1_RFahrlicht_Fzg_Anf 1;
BA_ "GenSigAutoGenDsp" SG_ 987 BCM1_RFahrlicht_Fzg_Anf 1;
BA_ "GenSigSwitchedByIgnition" SG_ 987 BCM1_RFahrlicht_Ahg_Anf 0;
BA_ "GenSigSendType" SG_ 987 BCM1_RFahrlicht_Ahg_Anf 0;
BA_ "GenSigEnvVarType" SG_ 987 BCM1_RFahrlicht_Ahg_Anf 0;
BA_ "GenSigAutoGenSnd" SG_ 987 BCM1_RFahrlicht_Ahg_Anf 1;
BA_ "GenSigAutoGenDsp" SG_ 987 BCM1_RFahrlicht_Ahg_Anf 1;
BA_ "GenSigSwitchedByIgnition" SG_ 987 BH_Fernlicht 0;
BA_ "GenSigSendType" SG_ 987 BH_Fernlicht 3;
BA_ "GenSigEnvVarType" SG_ 987 BH_Fernlicht 0;
BA_ "GenSigAutoGenSnd" SG_ 987 BH_Fernlicht 1;
BA_ "GenSigAutoGenDsp" SG_ 987 BH_Fernlicht 1;
BA_ "GenSigSwitchedByIgnition" SG_ 987 BH_Blinker_li 0;
BA_ "GenSigSendType" SG_ 987 BH_Blinker_li 3;
BA_ "GenSigEnvVarType" SG_ 987 BH_Blinker_li 0;
BA_ "GenSigAutoGenSnd" SG_ 987 BH_Blinker_li 1;
BA_ "GenSigAutoGenDsp" SG_ 987 BH_Blinker_li 1;
BA_ "GenSigSwitchedByIgnition" SG_ 987 BH_Blinker_re 0;
BA_ "GenSigSendType" SG_ 987 BH_Blinker_re 3;
BA_ "GenSigEnvVarType" SG_ 987 BH_Blinker_re 0;
BA_ "GenSigAutoGenSnd" SG_ 987 BH_Blinker_re 1;
BA_ "GenSigAutoGenDsp" SG_ 987 BH_Blinker_re 1;
BA_ "GenSigSwitchedByIgnition" SG_ 987 BCM1_OBD_FStatus_ATemp 0;
BA_ "GenSigSendType" SG_ 987 BCM1_OBD_FStatus_ATemp 0;
BA_ "GenSigEnvVarType" SG_ 987 BCM1_OBD_FStatus_ATemp 0;
BA_ "GenSigAutoGenSnd" SG_ 987 BCM1_OBD_FStatus_ATemp 1;
BA_ "GenSigAutoGenDsp" SG_ 987 BCM1_OBD_FStatus_ATemp 1;
BA_ "Fehlerwert" SG_ 987 BCM1_Aussen_Temp_ungef 255;
BA_ "GenSigSwitchedByIgnition" SG_ 987 BCM1_Aussen_Temp_ungef 0;
BA_ "GenSigStartValue" SG_ 987 BCM1_Aussen_Temp_ungef 254;
BA_ "GenSigSendType" SG_ 987 BCM1_Aussen_Temp_ungef 0;
BA_ "GenSigEnvVarType" SG_ 987 BCM1_Aussen_Temp_ungef 1;
BA_ "GenSigAutoGenSnd" SG_ 987 BCM1_Aussen_Temp_ungef 1;
BA_ "GenSigAutoGenDsp" SG_ 987 BCM1_Aussen_Temp_ungef 1;
BA_ "GenSigSwitchedByIgnition" SG_ 989 LH_EPS_01_alt 0;
BA_ "GenSigFuncType" SG_ 989 LH_EPS_01_alt 5;
BA_ "GenSigStartValue" SG_ 989 LH_EPS_01_alt 1;
BA_ "GenSigSendType" SG_ 989 LH_EPS_01_alt 0;
BA_ "GenSigEnvVarType" SG_ 989 LH_EPS_01_alt 0;
BA_ "GenSigAutoGenSnd" SG_ 989 LH_EPS_01_alt 1;
BA_ "GenSigAutoGenDsp" SG_ 989 LH_EPS_01_alt 1;
BA_ "GenSigSwitchedByIgnition" SG_ 989 Kessy_04_alt 0;
BA_ "GenSigFuncType" SG_ 989 Kessy_04_alt 5;
BA_ "GenSigStartValue" SG_ 989 Kessy_04_alt 1;
BA_ "GenSigSendType" SG_ 989 Kessy_04_alt 0;
BA_ "GenSigEnvVarType" SG_ 989 Kessy_04_alt 0;
BA_ "GenSigAutoGenSnd" SG_ 989 Kessy_04_alt 1;
BA_ "GenSigAutoGenDsp" SG_ 989 Kessy_04_alt 1;
BA_ "GenSigSwitchedByIgnition" SG_ 989 LIN_2_alt 0;
BA_ "GenSigFuncType" SG_ 989 LIN_2_alt 5;
BA_ "GenSigStartValue" SG_ 989 LIN_2_alt 1;
BA_ "GenSigSendType" SG_ 989 LIN_2_alt 0;
BA_ "GenSigEnvVarType" SG_ 989 LIN_2_alt 0;
BA_ "GenSigAutoGenSnd" SG_ 989 LIN_2_alt 1;
BA_ "GenSigAutoGenDsp" SG_ 989 LIN_2_alt 1;
BA_ "GenSigSwitchedByIgnition" SG_ 989 MFG_01_alt 0;
BA_ "GenSigFuncType" SG_ 989 MFG_01_alt 5;
BA_ "GenSigStartValue" SG_ 989 MFG_01_alt 1;
BA_ "GenSigSendType" SG_ 989 MFG_01_alt 0;
BA_ "GenSigEnvVarType" SG_ 989 MFG_01_alt 0;
BA_ "GenSigAutoGenSnd" SG_ 989 MFG_01_alt 1;
BA_ "GenSigAutoGenDsp" SG_ 989 MFG_01_alt 1;
BA_ "GenSigSwitchedByIgnition" SG_ 989 GW_74_va_14 0;
BA_ "GenSigFuncType" SG_ 989 GW_74_va_14 5;
BA_ "GenSigStartValue" SG_ 989 GW_74_va_14 1;
BA_ "GenSigSendType" SG_ 989 GW_74_va_14 0;
BA_ "GenSigEnvVarType" SG_ 989 GW_74_va_14 0;
BA_ "GenSigAutoGenSnd" SG_ 989 GW_74_va_14 1;
BA_ "GenSigAutoGenDsp" SG_ 989 GW_74_va_14 1;
BA_ "GenSigSwitchedByIgnition" SG_ 989 Klima_02_alt 0;
BA_ "GenSigFuncType" SG_ 989 Klima_02_alt 5;
BA_ "GenSigStartValue" SG_ 989 Klima_02_alt 1;
BA_ "GenSigSendType" SG_ 989 Klima_02_alt 0;
BA_ "GenSigEnvVarType" SG_ 989 Klima_02_alt 0;
BA_ "GenSigAutoGenSnd" SG_ 989 Klima_02_alt 1;
BA_ "GenSigAutoGenDsp" SG_ 989 Klima_02_alt 1;
BA_ "GenSigSwitchedByIgnition" SG_ 989 Parkhilfe_01_alt 0;
BA_ "GenSigFuncType" SG_ 989 Parkhilfe_01_alt 5;
BA_ "GenSigStartValue" SG_ 989 Parkhilfe_01_alt 1;
BA_ "GenSigSendType" SG_ 989 Parkhilfe_01_alt 0;
BA_ "GenSigEnvVarType" SG_ 989 Parkhilfe_01_alt 0;
BA_ "GenSigAutoGenSnd" SG_ 989 Parkhilfe_01_alt 1;
BA_ "GenSigAutoGenDsp" SG_ 989 Parkhilfe_01_alt 1;
BA_ "GenSigSwitchedByIgnition" SG_ 989 ELV_01_alt 0;
BA_ "GenSigFuncType" SG_ 989 ELV_01_alt 5;
BA_ "GenSigStartValue" SG_ 989 ELV_01_alt 1;
BA_ "GenSigSendType" SG_ 989 ELV_01_alt 0;
BA_ "GenSigEnvVarType" SG_ 989 ELV_01_alt 0;
BA_ "GenSigAutoGenSnd" SG_ 989 ELV_01_alt 1;
BA_ "GenSigAutoGenDsp" SG_ 989 ELV_01_alt 1;
BA_ "GenSigSwitchedByIgnition" SG_ 989 KY_StartStopp_Info 0;
BA_ "GenSigSendType" SG_ 989 KY_StartStopp_Info 3;
BA_ "GenSigAutoGenSnd" SG_ 989 KY_StartStopp_Info 1;
BA_ "GenSigAutoGenDsp" SG_ 989 KY_StartStopp_Info 1;
BA_ "GenSigSendType" SG_ 989 PH_StartStopp_Info 3;
BA_ "GenSigEnvVarType" SG_ 989 PH_StartStopp_Info 0;
BA_ "GenSigAutoGenSnd" SG_ 989 PH_StartStopp_Info 1;
BA_ "GenSigAutoGenDsp" SG_ 989 PH_StartStopp_Info 1;
BA_ "GenSigSwitchedByIgnition" SG_ 989 EPS_Lenkerposition 0;
BA_ "GenSigFuncType" SG_ 989 EPS_Lenkerposition 8;
BA_ "GenSigSendType" SG_ 989 EPS_Lenkerposition 0;
BA_ "GenSigSwitchedByIgnition" SG_ 989 ELV_Anf_Klemme_50 0;
BA_ "GenSigSendType" SG_ 989 ELV_Anf_Klemme_50 3;
BA_ "GenSigAutoGenSnd" SG_ 989 ELV_Anf_Klemme_50 1;
BA_ "GenSigAutoGenDsp" SG_ 989 ELV_Anf_Klemme_50 1;
BA_ "GenSigSwitchedByIgnition" SG_ 989 MF_StartStopp_Info 0;
BA_ "GenSigSendType" SG_ 989 MF_StartStopp_Info 0;
BA_ "GenSigAutoGenSnd" SG_ 989 MF_StartStopp_Info 1;
BA_ "GenSigAutoGenDsp" SG_ 989 MF_StartStopp_Info 1;
BA_ "GenSigSwitchedByIgnition" SG_ 989 KL_Geblaesespannung_Soll 0;
BA_ "GenSigSendType" SG_ 989 KL_Geblaesespannung_Soll 0;
BA_ "GenSigEnvVarType" SG_ 989 KL_Geblaesespannung_Soll 0;
BA_ "GenSigAutoGenSnd" SG_ 989 KL_Geblaesespannung_Soll 1;
BA_ "GenSigAutoGenDsp" SG_ 989 KL_Geblaesespannung_Soll 1;
BA_ "Fehlerwert" SG_ 989 KL_Umluftklappe_Status 15;
BA_ "GenSigSwitchedByIgnition" SG_ 989 KL_Umluftklappe_Status 0;
BA_ "GenSigStartValue" SG_ 989 KL_Umluftklappe_Status 14;
BA_ "GenSigSendType" SG_ 989 KL_Umluftklappe_Status 0;
BA_ "GenSigEnvVarType" SG_ 989 KL_Umluftklappe_Status 0;
BA_ "GenSigAutoGenSnd" SG_ 989 KL_Umluftklappe_Status 1;
BA_ "GenSigAutoGenDsp" SG_ 989 KL_Umluftklappe_Status 1;
BA_ "GenSigSendType" SG_ 989 MFL_Tip_Down 6;
BA_ "GenSigEnvVarType" SG_ 989 MFL_Tip_Down 0;
BA_ "GenSigAutoGenSnd" SG_ 989 MFL_Tip_Down 1;
BA_ "GenSigAutoGenDsp" SG_ 989 MFL_Tip_Down 1;
BA_ "GenSigSendType" SG_ 989 MFL_Tip_Up 6;
BA_ "GenSigEnvVarType" SG_ 989 MFL_Tip_Up 0;
BA_ "GenSigAutoGenSnd" SG_ 989 MFL_Tip_Up 1;
BA_ "GenSigAutoGenDsp" SG_ 989 MFL_Tip_Up 1;
BA_ "GenSigSendType" SG_ 989 LS_Tiptronic_Fehler 3;
BA_ "GenSigEnvVarType" SG_ 989 LS_Tiptronic_Fehler 0;
BA_ "GenSigAutoGenSnd" SG_ 989 LS_Tiptronic_Fehler 1;
BA_ "GenSigAutoGenDsp" SG_ 989 LS_Tiptronic_Fehler 1;
BA_ "GenSigSwitchedByIgnition" SG_ 296 GE_WH_Sperre 0;
BA_ "GenSigStartValue" SG_ 296 GE_WH_Sperre 1;
BA_ "GenSigSendType" SG_ 296 GE_WH_Sperre 0;
BA_ "GenSigEnvVarType" SG_ 296 GE_WH_Sperre 0;
BA_ "GenSigAutoGenSnd" SG_ 296 GE_WH_Sperre 1;
BA_ "GenSigAutoGenDsp" SG_ 296 GE_WH_Sperre 1;
BA_ "GenSigSwitchedByIgnition" SG_ 296 GE_Ausleuchtungsmode 0;
BA_ "GenSigSendType" SG_ 296 GE_Ausleuchtungsmode 0;
BA_ "GenSigEnvVarType" SG_ 296 GE_Ausleuchtungsmode 0;
BA_ "GenSigAutoGenSnd" SG_ 296 GE_Ausleuchtungsmode 1;
BA_ "GenSigAutoGenDsp" SG_ 296 GE_Ausleuchtungsmode 1;
BA_ "GenSigSwitchedByIgnition" SG_ 296 GE_Test_Freigabe 0;
BA_ "GenSigSendType" SG_ 296 GE_Test_Freigabe 0;
BA_ "GenSigEnvVarType" SG_ 296 GE_Test_Freigabe 0;
BA_ "GenSigAutoGenSnd" SG_ 296 GE_Test_Freigabe 1;
BA_ "GenSigAutoGenDsp" SG_ 296 GE_Test_Freigabe 1;
BA_ "Fehlerwert" SG_ 296 GE_Ist_Fahrstufe 15;
BA_ "GenSigSwitchedByIgnition" SG_ 296 GE_Ist_Fahrstufe 0;
BA_ "GenSigSendType" SG_ 296 GE_Ist_Fahrstufe 0;
BA_ "GenSigEnvVarType" SG_ 296 GE_Ist_Fahrstufe 0;
BA_ "GenSigAutoGenSnd" SG_ 296 GE_Ist_Fahrstufe 1;
BA_ "GenSigAutoGenDsp" SG_ 296 GE_Ist_Fahrstufe 1;
BA_ "GenSigSwitchedByIgnition" SG_ 296 GE_Testparameter_1 0;
BA_ "GenSigSendType" SG_ 296 GE_Testparameter_1 0;
BA_ "GenSigEnvVarType" SG_ 296 GE_Testparameter_1 0;
BA_ "GenSigAutoGenSnd" SG_ 296 GE_Testparameter_1 1;
BA_ "GenSigAutoGenDsp" SG_ 296 GE_Testparameter_1 1;
BA_ "GenSigSwitchedByIgnition" SG_ 296 GE_Testparameter_2 0;
BA_ "GenSigSendType" SG_ 296 GE_Testparameter_2 0;
BA_ "GenSigEnvVarType" SG_ 296 GE_Testparameter_2 0;
BA_ "GenSigAutoGenSnd" SG_ 296 GE_Testparameter_2 1;
BA_ "GenSigAutoGenDsp" SG_ 296 GE_Testparameter_2 1;
BA_ "GenSigSwitchedByIgnition" SG_ 173 Getriebe_11_CRC 0;
BA_ "GenSigFuncType" SG_ 173 Getriebe_11_CRC 2;
BA_ "GenSigSendType" SG_ 173 Getriebe_11_CRC 0;
BA_ "GenSigEnvVarType" SG_ 173 Getriebe_11_CRC 0;
BA_ "GenSigAutoGenSnd" SG_ 173 Getriebe_11_CRC 1;
BA_ "GenSigAutoGenDsp" SG_ 173 Getriebe_11_CRC 1;
BA_ "GenSigSwitchedByIgnition" SG_ 173 Getriebe_11_BZ 0;
BA_ "GenSigFuncType" SG_ 173 Getriebe_11_BZ 1;
BA_ "GenSigSendType" SG_ 173 Getriebe_11_BZ 0;
BA_ "GenSigEnvVarType" SG_ 173 Getriebe_11_BZ 0;
BA_ "GenSigAutoGenSnd" SG_ 173 Getriebe_11_BZ 1;
BA_ "GenSigAutoGenDsp" SG_ 173 Getriebe_11_BZ 1;
BA_ "Fehlerwert" SG_ 173 GE_MMom_Soll_02 1023;
BA_ "GenSigSwitchedByIgnition" SG_ 173 GE_MMom_Soll_02 0;
BA_ "GenSigStartValue" SG_ 173 GE_MMom_Soll_02 1022;
BA_ "GenSigSendType" SG_ 173 GE_MMom_Soll_02 0;
BA_ "GenSigEnvVarType" SG_ 173 GE_MMom_Soll_02 0;
BA_ "GenSigAutoGenSnd" SG_ 173 GE_MMom_Soll_02 1;
BA_ "GenSigAutoGenDsp" SG_ 173 GE_MMom_Soll_02 1;
BA_ "Fehlerwert" SG_ 173 GE_MMom_Vorhalt_02 1023;
BA_ "GenSigSwitchedByIgnition" SG_ 173 GE_MMom_Vorhalt_02 0;
BA_ "GenSigStartValue" SG_ 173 GE_MMom_Vorhalt_02 1022;
BA_ "GenSigSendType" SG_ 173 GE_MMom_Vorhalt_02 0;
BA_ "GenSigAutoGenSnd" SG_ 173 GE_MMom_Vorhalt_02 1;
BA_ "GenSigAutoGenDsp" SG_ 173 GE_MMom_Vorhalt_02 1;
BA_ "Fehlerwert" SG_ 173 GE_Uefkt 1023;
BA_ "GenSigSwitchedByIgnition" SG_ 173 GE_Uefkt 0;
BA_ "GenSigSendType" SG_ 173 GE_Uefkt 0;
BA_ "GenSigEnvVarType" SG_ 173 GE_Uefkt 1;
BA_ "GenSigAutoGenSnd" SG_ 173 GE_Uefkt 1;
BA_ "GenSigAutoGenDsp" SG_ 173 GE_Uefkt 1;
BA_ "Fehlerwert" SG_ 173 GE_Fahrstufe 15;
BA_ "GenSigSwitchedByIgnition" SG_ 173 GE_Fahrstufe 0;
BA_ "GenSigStartValue" SG_ 173 GE_Fahrstufe 1;
BA_ "GenSigSendType" SG_ 173 GE_Fahrstufe 0;
BA_ "GenSigEnvVarType" SG_ 173 GE_Fahrstufe 0;
BA_ "GenSigAutoGenSnd" SG_ 173 GE_Fahrstufe 1;
BA_ "GenSigAutoGenDsp" SG_ 173 GE_Fahrstufe 1;
BA_ "GenSigSwitchedByIgnition" SG_ 173 GE_Schaltvorgang 0;
BA_ "GenSigSendType" SG_ 173 GE_Schaltvorgang 0;
BA_ "GenSigEnvVarType" SG_ 173 GE_Schaltvorgang 0;
BA_ "GenSigAutoGenSnd" SG_ 173 GE_Schaltvorgang 1;
BA_ "GenSigAutoGenDsp" SG_ 173 GE_Schaltvorgang 1;
BA_ "Fehlerwert" SG_ 173 GE_Status_Kupplung 3;
BA_ "GenSigSwitchedByIgnition" SG_ 173 GE_Status_Kupplung 0;
BA_ "GenSigSendType" SG_ 173 GE_Status_Kupplung 0;
BA_ "GenSigEnvVarType" SG_ 173 GE_Status_Kupplung 0;
BA_ "GenSigAutoGenSnd" SG_ 173 GE_Status_Kupplung 1;
BA_ "GenSigAutoGenDsp" SG_ 173 GE_Status_Kupplung 1;
BA_ "GenSigSwitchedByIgnition" SG_ 173 GE_MMom_Status 0;
BA_ "GenSigSendType" SG_ 173 GE_MMom_Status 0;
BA_ "GenSigEnvVarType" SG_ 173 GE_MMom_Status 0;
BA_ "GenSigAutoGenSnd" SG_ 173 GE_MMom_Status 1;
BA_ "GenSigAutoGenDsp" SG_ 173 GE_MMom_Status 1;
BA_ "GenSigSwitchedByIgnition" SG_ 173 GE_Freig_MMom_Vorhalt 0;
BA_ "GenSigSendType" SG_ 173 GE_Freig_MMom_Vorhalt 0;
BA_ "GenSigAutoGenSnd" SG_ 173 GE_Freig_MMom_Vorhalt 1;
BA_ "GenSigAutoGenDsp" SG_ 173 GE_Freig_MMom_Vorhalt 1;
BA_ "GenSigSwitchedByIgnition" SG_ 173 GE_Verbot_Ausblendung 0;
BA_ "GenSigSendType" SG_ 173 GE_Verbot_Ausblendung 0;
BA_ "GenSigAutoGenSnd" SG_ 173 GE_Verbot_Ausblendung 1;
BA_ "GenSigAutoGenDsp" SG_ 173 GE_Verbot_Ausblendung 1;
BA_ "Fehlerwert" SG_ 173 GE_Zielgang 15;
BA_ "GenSigSwitchedByIgnition" SG_ 173 GE_Zielgang 0;
BA_ "GenSigSendType" SG_ 173 GE_Zielgang 0;
BA_ "GenSigEnvVarType" SG_ 173 GE_Zielgang 0;
BA_ "GenSigAutoGenSnd" SG_ 173 GE_Zielgang 1;
BA_ "GenSigAutoGenDsp" SG_ 173 GE_Zielgang 1;
BA_ "GenSigSwitchedByIgnition" SG_ 174 Getriebe_12_CRC 0;
BA_ "GenSigFuncType" SG_ 174 Getriebe_12_CRC 2;
BA_ "GenSigSendType" SG_ 174 Getriebe_12_CRC 0;
BA_ "GenSigEnvVarType" SG_ 174 Getriebe_12_CRC 0;
BA_ "GenSigAutoGenSnd" SG_ 174 Getriebe_12_CRC 1;
BA_ "GenSigAutoGenDsp" SG_ 174 Getriebe_12_CRC 1;
BA_ "GenSigSwitchedByIgnition" SG_ 174 Getriebe_12_BZ 0;
BA_ "GenSigFuncType" SG_ 174 Getriebe_12_BZ 1;
BA_ "GenSigSendType" SG_ 174 Getriebe_12_BZ 0;
BA_ "GenSigEnvVarType" SG_ 174 Getriebe_12_BZ 0;
BA_ "GenSigAutoGenSnd" SG_ 174 Getriebe_12_BZ 1;
BA_ "GenSigAutoGenDsp" SG_ 174 Getriebe_12_BZ 1;
BA_ "GenSigSwitchedByIgnition" SG_ 174 GE_Drehzahlmesser_Daempfung 0;
BA_ "GenSigSendType" SG_ 174 GE_Drehzahlmesser_Daempfung 0;
BA_ "GenSigEnvVarType" SG_ 174 GE_Drehzahlmesser_Daempfung 0;
BA_ "GenSigAutoGenSnd" SG_ 174 GE_Drehzahlmesser_Daempfung 1;
BA_ "GenSigAutoGenDsp" SG_ 174 GE_Drehzahlmesser_Daempfung 1;
BA_ "GenSigSwitchedByIgnition" SG_ 174 GE_Schubabschalt_Unt 0;
BA_ "GenSigSendType" SG_ 174 GE_Schubabschalt_Unt 0;
BA_ "GenSigEnvVarType" SG_ 174 GE_Schubabschalt_Unt 0;
BA_ "GenSigAutoGenSnd" SG_ 174 GE_Schubabschalt_Unt 1;
BA_ "GenSigAutoGenDsp" SG_ 174 GE_Schubabschalt_Unt 1;
BA_ "GenSigSwitchedByIgnition" SG_ 174 GE_Freigabe_Synchro 0;
BA_ "GenSigSendType" SG_ 174 GE_Freigabe_Synchro 0;
BA_ "GenSigEnvVarType" SG_ 174 GE_Freigabe_Synchro 0;
BA_ "GenSigAutoGenSnd" SG_ 174 GE_Freigabe_Synchro 1;
BA_ "GenSigAutoGenDsp" SG_ 174 GE_Freigabe_Synchro 1;
BA_ "Fehlerwert" SG_ 174 GE_Synchro_Wunschdrehz 511;
BA_ "GenSigSwitchedByIgnition" SG_ 174 GE_Synchro_Wunschdrehz 0;
BA_ "GenSigSendType" SG_ 174 GE_Synchro_Wunschdrehz 0;
BA_ "GenSigEnvVarType" SG_ 174 GE_Synchro_Wunschdrehz 0;
BA_ "GenSigAutoGenSnd" SG_ 174 GE_Synchro_Wunschdrehz 1;
BA_ "GenSigAutoGenDsp" SG_ 174 GE_Synchro_Wunschdrehz 1;
BA_ "Fehlerwert" SG_ 174 GE_Synchro_Zeit 255;
BA_ "GenSigSwitchedByIgnition" SG_ 174 GE_Synchro_Zeit 0;
BA_ "GenSigSendType" SG_ 174 GE_Synchro_Zeit 0;
BA_ "GenSigEnvVarType" SG_ 174 GE_Synchro_Zeit 0;
BA_ "GenSigAutoGenSnd" SG_ 174 GE_Synchro_Zeit 1;
BA_ "GenSigAutoGenDsp" SG_ 174 GE_Synchro_Zeit 1;
BA_ "GenSigSwitchedByIgnition" SG_ 174 GE_Mom_Begr_Gradient 0;
BA_ "GenSigStartValue" SG_ 174 GE_Mom_Begr_Gradient 255;
BA_ "GenSigSendType" SG_ 174 GE_Mom_Begr_Gradient 0;
BA_ "GenSigEnvVarType" SG_ 174 GE_Mom_Begr_Gradient 0;
BA_ "GenSigAutoGenSnd" SG_ 174 GE_Mom_Begr_Gradient 1;
BA_ "GenSigAutoGenDsp" SG_ 174 GE_Mom_Begr_Gradient 1;
BA_ "Fehlerwert" SG_ 174 GE_Anheb_Solldrehz_Leerlauf 255;
BA_ "GenSigSwitchedByIgnition" SG_ 174 GE_Anheb_Solldrehz_Leerlauf 0;
BA_ "GenSigSendType" SG_ 174 GE_Anheb_Solldrehz_Leerlauf 0;
BA_ "GenSigEnvVarType" SG_ 174 GE_Anheb_Solldrehz_Leerlauf 0;
BA_ "GenSigAutoGenSnd" SG_ 174 GE_Anheb_Solldrehz_Leerlauf 1;
BA_ "GenSigAutoGenDsp" SG_ 174 GE_Anheb_Solldrehz_Leerlauf 1;
BA_ "Fehlerwert" SG_ 174 GE_Aufnahmemoment 511;
BA_ "GenSigSwitchedByIgnition" SG_ 174 GE_Aufnahmemoment 0;
BA_ "GenSigStartValue" SG_ 174 GE_Aufnahmemoment 510;
BA_ "GenSigSendType" SG_ 174 GE_Aufnahmemoment 0;
BA_ "GenSigEnvVarType" SG_ 174 GE_Aufnahmemoment 0;
BA_ "GenSigAutoGenSnd" SG_ 174 GE_Aufnahmemoment 1;
BA_ "GenSigAutoGenDsp" SG_ 174 GE_Aufnahmemoment 1;
BA_ "GenSigSwitchedByIgnition" SG_ 174 GE_Anf_Zylabsch 0;
BA_ "GenSigSendType" SG_ 174 GE_Anf_Zylabsch 0;
BA_ "GenSigEnvVarType" SG_ 174 GE_Anf_Zylabsch 0;
BA_ "GenSigAutoGenSnd" SG_ 174 GE_Anf_Zylabsch 1;
BA_ "GenSigAutoGenDsp" SG_ 174 GE_Anf_Zylabsch 1;
BA_ "GenSigSwitchedByIgnition" SG_ 174 GE_HYB_DZ_Eingriff 0;
BA_ "GenSigSendType" SG_ 174 GE_HYB_DZ_Eingriff 0;
BA_ "GenSigAutoGenSnd" SG_ 174 GE_HYB_DZ_Eingriff 1;
BA_ "GenSigAutoGenDsp" SG_ 174 GE_HYB_DZ_Eingriff 1;
BA_ "GenSigSwitchedByIgnition" SG_ 301 Getriebe_13_CRC 0;
BA_ "GenSigFuncType" SG_ 301 Getriebe_13_CRC 2;
BA_ "GenSigSendType" SG_ 301 Getriebe_13_CRC 0;
BA_ "GenSigEnvVarType" SG_ 301 Getriebe_13_CRC 0;
BA_ "GenSigAutoGenSnd" SG_ 301 Getriebe_13_CRC 1;
BA_ "GenSigAutoGenDsp" SG_ 301 Getriebe_13_CRC 1;
BA_ "GenSigSwitchedByIgnition" SG_ 301 Getriebe_13_BZ 0;
BA_ "GenSigFuncType" SG_ 301 Getriebe_13_BZ 1;
BA_ "GenSigSendType" SG_ 301 Getriebe_13_BZ 0;
BA_ "GenSigEnvVarType" SG_ 301 Getriebe_13_BZ 0;
BA_ "GenSigAutoGenSnd" SG_ 301 Getriebe_13_BZ 1;
BA_ "GenSigAutoGenDsp" SG_ 301 Getriebe_13_BZ 1;
BA_ "GenSigSwitchedByIgnition" SG_ 301 GE_StartStopp_Info 0;
BA_ "GenSigSendType" SG_ 301 GE_StartStopp_Info 0;
BA_ "GenSigAutoGenSnd" SG_ 301 GE_StartStopp_Info 1;
BA_ "GenSigAutoGenDsp" SG_ 301 GE_StartStopp_Info 1;
BA_ "Fehlerwert" SG_ 301 GE_Langfr_Schutzmom_02 1023;
BA_ "GenSigSwitchedByIgnition" SG_ 301 GE_Langfr_Schutzmom_02 0;
BA_ "GenSigStartValue" SG_ 301 GE_Langfr_Schutzmom_02 510;
BA_ "GenSigSendType" SG_ 301 GE_Langfr_Schutzmom_02 0;
BA_ "GenSigEnvVarType" SG_ 301 GE_Langfr_Schutzmom_02 0;
BA_ "GenSigAutoGenSnd" SG_ 301 GE_Langfr_Schutzmom_02 1;
BA_ "GenSigAutoGenDsp" SG_ 301 GE_Langfr_Schutzmom_02 1;
BA_ "Fehlerwert" SG_ 301 GE_Eingangsdrehz 16383;
BA_ "GenSigSwitchedByIgnition" SG_ 301 GE_Eingangsdrehz 0;
BA_ "GenSigStartValue" SG_ 301 GE_Eingangsdrehz 16382;
BA_ "GenSigSendType" SG_ 301 GE_Eingangsdrehz 0;
BA_ "GenSigEnvVarType" SG_ 301 GE_Eingangsdrehz 1;
BA_ "GenSigAutoGenSnd" SG_ 301 GE_Eingangsdrehz 1;
BA_ "GenSigAutoGenDsp" SG_ 301 GE_Eingangsdrehz 1;
BA_ "GenSigSwitchedByIgnition" SG_ 301 GE_Notlauf 0;
BA_ "GenSigSendType" SG_ 301 GE_Notlauf 0;
BA_ "GenSigEnvVarType" SG_ 301 GE_Notlauf 0;
BA_ "GenSigAutoGenSnd" SG_ 301 GE_Notlauf 1;
BA_ "GenSigAutoGenDsp" SG_ 301 GE_Notlauf 1;
BA_ "GenSigSwitchedByIgnition" SG_ 301 GE_Freig_Langfr_Schutzmom 0;
BA_ "GenSigSendType" SG_ 301 GE_Freig_Langfr_Schutzmom 0;
BA_ "GenSigEnvVarType" SG_ 301 GE_Freig_Langfr_Schutzmom 0;
BA_ "GenSigAutoGenSnd" SG_ 301 GE_Freig_Langfr_Schutzmom 1;
BA_ "GenSigAutoGenDsp" SG_ 301 GE_Freig_Langfr_Schutzmom 1;
BA_ "GenSigSwitchedByIgnition" SG_ 968 GE_OBD_AbsperrVent 0;
BA_ "GenSigSendType" SG_ 968 GE_OBD_AbsperrVent 0;
BA_ "GenSigSwitchedByIgnition" SG_ 968 GE_amax_moeglich 0;
BA_ "GenSigStartValue" SG_ 968 GE_amax_moeglich 84;
BA_ "GenSigSendType" SG_ 968 GE_amax_moeglich 0;
BA_ "GenSigEnvVarType" SG_ 968 GE_amax_moeglich 1;
BA_ "GenSigAutoGenSnd" SG_ 968 GE_amax_moeglich 1;
BA_ "GenSigAutoGenDsp" SG_ 968 GE_amax_moeglich 1;
BA_ "GenSigSwitchedByIgnition" SG_ 968 GE_Charisma_FahrPr 0;
BA_ "GenSigSendType" SG_ 968 GE_Charisma_FahrPr 0;
BA_ "GenSigEnvVarType" SG_ 968 GE_Charisma_FahrPr 0;
BA_ "GenSigAutoGenSnd" SG_ 968 GE_Charisma_FahrPr 1;
BA_ "GenSigAutoGenDsp" SG_ 968 GE_Charisma_FahrPr 1;
BA_ "GenSigSwitchedByIgnition" SG_ 968 GE_Charisma_Status 0;
BA_ "GenSigSendType" SG_ 968 GE_Charisma_Status 0;
BA_ "GenSigEnvVarType" SG_ 968 GE_Charisma_Status 0;
BA_ "GenSigAutoGenSnd" SG_ 968 GE_Charisma_Status 1;
BA_ "GenSigAutoGenDsp" SG_ 968 GE_Charisma_Status 1;
BA_ "Fehlerwert" SG_ 968 GE_Verlustmoment 255;
BA_ "GenSigSwitchedByIgnition" SG_ 968 GE_Verlustmoment 0;
BA_ "GenSigSendType" SG_ 968 GE_Verlustmoment 0;
BA_ "GenSigEnvVarType" SG_ 968 GE_Verlustmoment 0;
BA_ "GenSigAutoGenSnd" SG_ 968 GE_Verlustmoment 1;
BA_ "GenSigAutoGenDsp" SG_ 968 GE_Verlustmoment 1;
BA_ "GenSigSwitchedByIgnition" SG_ 968 GE_Freigabe_Verfallsinfo_WFS 0;
BA_ "GenSigSendType" SG_ 968 GE_Freigabe_Verfallsinfo_WFS 0;
BA_ "GenSigSwitchedByIgnition" SG_ 968 GE_Codierung_MSG 0;
BA_ "GenSigSendType" SG_ 968 GE_Codierung_MSG 0;
BA_ "GenSigEnvVarType" SG_ 968 GE_Codierung_MSG 0;
BA_ "GenSigAutoGenSnd" SG_ 968 GE_Codierung_MSG 1;
BA_ "GenSigAutoGenDsp" SG_ 968 GE_Codierung_MSG 1;
BA_ "GenSigSwitchedByIgnition" SG_ 968 GE_LaunchControl 0;
BA_ "GenSigSendType" SG_ 968 GE_LaunchControl 0;
BA_ "GenSigAutoGenSnd" SG_ 968 GE_LaunchControl 1;
BA_ "GenSigAutoGenDsp" SG_ 968 GE_LaunchControl 1;
BA_ "GenSigSwitchedByIgnition" SG_ 968 GE_Heizwunsch 0;
BA_ "GenSigStartValue" SG_ 968 GE_Heizwunsch 1;
BA_ "GenSigSendType" SG_ 968 GE_Heizwunsch 0;
BA_ "GenSigAutoGenSnd" SG_ 968 GE_Heizwunsch 1;
BA_ "GenSigAutoGenDsp" SG_ 968 GE_Heizwunsch 1;
BA_ "GenSigSwitchedByIgnition" SG_ 968 GE_OBD_Status 0;
BA_ "GenSigSendType" SG_ 968 GE_OBD_Status 0;
BA_ "GenSigEnvVarType" SG_ 968 GE_OBD_Status 0;
BA_ "GenSigAutoGenSnd" SG_ 968 GE_OBD_Status 1;
BA_ "GenSigAutoGenDsp" SG_ 968 GE_OBD_Status 1;
BA_ "GenSigSwitchedByIgnition" SG_ 968 GE_LFR_Adaption 0;
BA_ "GenSigSendType" SG_ 968 GE_LFR_Adaption 0;
BA_ "GenSigEnvVarType" SG_ 968 GE_LFR_Adaption 0;
BA_ "GenSigAutoGenSnd" SG_ 968 GE_LFR_Adaption 1;
BA_ "GenSigAutoGenDsp" SG_ 968 GE_LFR_Adaption 1;
BA_ "Fehlerwert" SG_ 968 GE_Sumpftemperatur 255;
BA_ "GenSigSwitchedByIgnition" SG_ 968 GE_Sumpftemperatur 0;
BA_ "GenSigSendType" SG_ 968 GE_Sumpftemperatur 0;
BA_ "GenSigEnvVarType" SG_ 968 GE_Sumpftemperatur 0;
BA_ "GenSigAutoGenSnd" SG_ 968 GE_Sumpftemperatur 1;
BA_ "GenSigAutoGenDsp" SG_ 968 GE_Sumpftemperatur 1;
BA_ "GenSigSwitchedByIgnition" SG_ 158 Getriebe_Hybrid_01_CRC 0;
BA_ "GenSigFuncType" SG_ 158 Getriebe_Hybrid_01_CRC 2;
BA_ "GenSigSendType" SG_ 158 Getriebe_Hybrid_01_CRC 0;
BA_ "GenSigEnvVarType" SG_ 158 Getriebe_Hybrid_01_CRC 0;
BA_ "GenSigAutoGenSnd" SG_ 158 Getriebe_Hybrid_01_CRC 1;
BA_ "GenSigAutoGenDsp" SG_ 158 Getriebe_Hybrid_01_CRC 1;
BA_ "GenSigSwitchedByIgnition" SG_ 158 Getriebe_Hybrid_01_BZ 0;
BA_ "GenSigFuncType" SG_ 158 Getriebe_Hybrid_01_BZ 1;
BA_ "GenSigSendType" SG_ 158 Getriebe_Hybrid_01_BZ 0;
BA_ "GenSigEnvVarType" SG_ 158 Getriebe_Hybrid_01_BZ 0;
BA_ "GenSigAutoGenSnd" SG_ 158 Getriebe_Hybrid_01_BZ 1;
BA_ "GenSigAutoGenDsp" SG_ 158 Getriebe_Hybrid_01_BZ 1;
BA_ "GenSigSwitchedByIgnition" SG_ 158 GE_HYB_Fehlerstatus 0;
BA_ "GenSigSendType" SG_ 158 GE_HYB_Fehlerstatus 0;
BA_ "GenSigAutoGenSnd" SG_ 158 GE_HYB_Fehlerstatus 1;
BA_ "GenSigAutoGenDsp" SG_ 158 GE_HYB_Fehlerstatus 1;
BA_ "GenSigSwitchedByIgnition" SG_ 158 GE_HYB_Freigabe_K0 0;
BA_ "GenSigSendType" SG_ 158 GE_HYB_Freigabe_K0 0;
BA_ "GenSigAutoGenSnd" SG_ 158 GE_HYB_Freigabe_K0 1;
BA_ "GenSigAutoGenDsp" SG_ 158 GE_HYB_Freigabe_K0 1;
BA_ "GenSigSwitchedByIgnition" SG_ 158 GE_HYB_Freigabe_LL_Reg 0;
BA_ "GenSigStartValue" SG_ 158 GE_HYB_Freigabe_LL_Reg 1;
BA_ "GenSigSendType" SG_ 158 GE_HYB_Freigabe_LL_Reg 0;
BA_ "GenSigAutoGenSnd" SG_ 158 GE_HYB_Freigabe_LL_Reg 1;
BA_ "GenSigAutoGenDsp" SG_ 158 GE_HYB_Freigabe_LL_Reg 1;
BA_ "GenSigSwitchedByIgnition" SG_ 158 GE_HYB_Freig_sSchl_K0 0;
BA_ "GenSigSendType" SG_ 158 GE_HYB_Freig_sSchl_K0 0;
BA_ "GenSigAutoGenSnd" SG_ 158 GE_HYB_Freig_sSchl_K0 1;
BA_ "GenSigAutoGenDsp" SG_ 158 GE_HYB_Freig_sSchl_K0 1;
BA_ "GenSigSwitchedByIgnition" SG_ 158 GE_HYB_Freig_VM_EM_Stop 0;
BA_ "GenSigSendType" SG_ 158 GE_HYB_Freig_VM_EM_Stop 0;
BA_ "GenSigAutoGenSnd" SG_ 158 GE_HYB_Freig_VM_EM_Stop 1;
BA_ "GenSigAutoGenDsp" SG_ 158 GE_HYB_Freig_VM_EM_Stop 1;
BA_ "GenSigSwitchedByIgnition" SG_ 158 GE_HYB_Wiederstart 0;
BA_ "GenSigSendType" SG_ 158 GE_HYB_Wiederstart 0;
BA_ "GenSigAutoGenSnd" SG_ 158 GE_HYB_Wiederstart 1;
BA_ "GenSigAutoGenDsp" SG_ 158 GE_HYB_Wiederstart 1;
BA_ "GenSigSwitchedByIgnition" SG_ 158 GE_HYB_Filt_MomAufbau 0;
BA_ "GenSigSendType" SG_ 158 GE_HYB_Filt_MomAufbau 0;
BA_ "GenSigAutoGenSnd" SG_ 158 GE_HYB_Filt_MomAufbau 1;
BA_ "GenSigAutoGenDsp" SG_ 158 GE_HYB_Filt_MomAufbau 1;
BA_ "Fehlerwert" SG_ 158 GE_HYB_nK0 255;
BA_ "GenSigSwitchedByIgnition" SG_ 158 GE_HYB_nK0 0;
BA_ "GenSigSendType" SG_ 158 GE_HYB_nK0 0;
BA_ "GenSigAutoGenSnd" SG_ 158 GE_HYB_nK0 1;
BA_ "GenSigAutoGenDsp" SG_ 158 GE_HYB_nK0 1;
BA_ "GenSigSwitchedByIgnition" SG_ 158 GE_HYB_MomEingriff_EM 0;
BA_ "GenSigSendType" SG_ 158 GE_HYB_MomEingriff_EM 0;
BA_ "GenSigAutoGenSnd" SG_ 158 GE_HYB_MomEingriff_EM 1;
BA_ "GenSigAutoGenDsp" SG_ 158 GE_HYB_MomEingriff_EM 1;
BA_ "GenSigSwitchedByIgnition" SG_ 158 GE_HYB_VZ_MomEingriff_EM 0;
BA_ "GenSigSendType" SG_ 158 GE_HYB_VZ_MomEingriff_EM 0;
BA_ "GenSigAutoGenSnd" SG_ 158 GE_HYB_VZ_MomEingriff_EM 1;
BA_ "GenSigAutoGenDsp" SG_ 158 GE_HYB_VZ_MomEingriff_EM 1;
BA_ "GenSigSwitchedByIgnition" SG_ 158 GE_HYB_Sportfaktor 0;
BA_ "GenSigSendType" SG_ 158 GE_HYB_Sportfaktor 0;
BA_ "GenSigAutoGenSnd" SG_ 158 GE_HYB_Sportfaktor 1;
BA_ "GenSigAutoGenDsp" SG_ 158 GE_HYB_Sportfaktor 1;
BA_ "GenSigSwitchedByIgnition" SG_ 158 GE_HYB_VM_akt_halten 0;
BA_ "GenSigSendType" SG_ 158 GE_HYB_VM_akt_halten 0;
BA_ "GenSigAutoGenSnd" SG_ 158 GE_HYB_VM_akt_halten 1;
BA_ "GenSigAutoGenDsp" SG_ 158 GE_HYB_VM_akt_halten 1;
BA_ "GenSigSwitchedByIgnition" SG_ 158 GE_HYB_StartAnf 0;
BA_ "GenSigSendType" SG_ 158 GE_HYB_StartAnf 0;
BA_ "GenSigAutoGenSnd" SG_ 158 GE_HYB_StartAnf 1;
BA_ "GenSigAutoGenDsp" SG_ 158 GE_HYB_StartAnf 1;
BA_ "GenSigSwitchedByIgnition" SG_ 158 GE_HYB_VM_Startkontr 0;
BA_ "GenSigSendType" SG_ 158 GE_HYB_VM_Startkontr 0;
BA_ "GenSigAutoGenSnd" SG_ 158 GE_HYB_VM_Startkontr 1;
BA_ "GenSigAutoGenDsp" SG_ 158 GE_HYB_VM_Startkontr 1;
BA_REL_ "GenSigTimeoutTime" BU_SG_REL_ Airbag_MQB SG_ 262 ESP_05_CRC 500;
BA_REL_ "GenSigTimeoutTime" BU_SG_REL_ Getriebe_DQ_Hybrid_MQB SG_ 262 ESP_05_CRC 500;
BA_REL_ "GenSigTimeoutTime" BU_SG_REL_ Getriebe_DQ_MQB SG_ 262 ESP_05_CRC 500;
BA_REL_ "GenSigTimeoutTime" BU_SG_REL_ Motor_Diesel_MQB SG_ 262 ESP_05_CRC 500;
BA_REL_ "GenSigTimeoutTime" BU_SG_REL_ Motor_Diesel_MQB SG_ 262 ESP_05_CRC 500;
BA_REL_ "GenSigTimeoutTime" BU_SG_REL_ Motor_Hybrid_MQB SG_ 262 ESP_05_CRC 500;
BA_REL_ "GenSigTimeoutTime" BU_SG_REL_ Motor_Hybrid_MQB SG_ 262 ESP_05_CRC 500;
BA_REL_ "GenSigTimeoutTime" BU_SG_REL_ Motor_Otto_MQB SG_ 262 ESP_05_CRC 500;
BA_REL_ "GenSigTimeoutTime" BU_SG_REL_ Motor_Otto_MQB SG_ 262 ESP_05_CRC 500;
BA_REL_ "GenSigTimeoutTime" BU_SG_REL_ Airbag_MQB SG_ 262 ESP_05_BZ 500;
BA_REL_ "GenSigTimeoutTime" BU_SG_REL_ Getriebe_DQ_Hybrid_MQB SG_ 262 ESP_05_BZ 500;
BA_REL_ "GenSigTimeoutTime" BU_SG_REL_ Getriebe_DQ_MQB SG_ 262 ESP_05_BZ 500;
BA_REL_ "GenSigTimeoutTime" BU_SG_REL_ Motor_Diesel_MQB SG_ 262 ESP_05_BZ 500;
BA_REL_ "GenSigTimeoutTime" BU_SG_REL_ Motor_Diesel_MQB SG_ 262 ESP_05_BZ 500;
BA_REL_ "GenSigTimeoutTime" BU_SG_REL_ Motor_Hybrid_MQB SG_ 262 ESP_05_BZ 500;
BA_REL_ "GenSigTimeoutTime" BU_SG_REL_ Motor_Hybrid_MQB SG_ 262 ESP_05_BZ 500;
BA_REL_ "GenSigTimeoutTime" BU_SG_REL_ Motor_Otto_MQB SG_ 262 ESP_05_BZ 500;
BA_REL_ "GenSigTimeoutTime" BU_SG_REL_ Motor_Otto_MQB SG_ 262 ESP_05_BZ 500;
BA_REL_ "GenSigTimeoutTime" BU_SG_REL_ Airbag_MQB SG_ 262 ESP_QBit_Bremsdruck 500;
BA_REL_ "GenSigTimeoutTime" BU_SG_REL_ Getriebe_DQ_Hybrid_MQB SG_ 262 ESP_QBit_Bremsdruck 500;
BA_REL_ "GenSigTimeoutTime" BU_SG_REL_ Getriebe_DQ_MQB SG_ 262 ESP_QBit_Bremsdruck 500;
BA_REL_ "GenSigTimeoutTime" BU_SG_REL_ Motor_Diesel_MQB SG_ 262 ESP_QBit_Bremsdruck 500;
BA_REL_ "GenSigTimeoutTime" BU_SG_REL_ Motor_Diesel_MQB SG_ 262 ESP_QBit_Bremsdruck 500;
BA_REL_ "GenSigTimeoutTime" BU_SG_REL_ Motor_Hybrid_MQB SG_ 262 ESP_QBit_Bremsdruck 500;
BA_REL_ "GenSigTimeoutTime" BU_SG_REL_ Motor_Hybrid_MQB SG_ 262 ESP_QBit_Bremsdruck 500;
BA_REL_ "GenSigTimeoutTime" BU_SG_REL_ Motor_Otto_MQB SG_ 262 ESP_QBit_Bremsdruck 500;
BA_REL_ "GenSigTimeoutTime" BU_SG_REL_ Motor_Otto_MQB SG_ 262 ESP_QBit_Bremsdruck 500;
BA_REL_ "GenSigTimeoutTime" BU_SG_REL_ Motor_Diesel_MQB SG_ 262 ESP_QBit_Fahrer_bremst 500;
BA_REL_ "GenSigTimeoutTime" BU_SG_REL_ Motor_Diesel_MQB SG_ 262 ESP_QBit_Fahrer_bremst 500;
BA_REL_ "GenSigTimeoutTime" BU_SG_REL_ Motor_Hybrid_MQB SG_ 262 ESP_QBit_Fahrer_bremst 500;
BA_REL_ "GenSigTimeoutTime" BU_SG_REL_ Motor_Hybrid_MQB SG_ 262 ESP_QBit_Fahrer_bremst 500;
BA_REL_ "GenSigTimeoutTime" BU_SG_REL_ Motor_Otto_MQB SG_ 262 ESP_QBit_Fahrer_bremst 500;
BA_REL_ "GenSigTimeoutTime" BU_SG_REL_ Motor_Otto_MQB SG_ 262 ESP_QBit_Fahrer_bremst 500;
BA_REL_ "GenSigTimeoutTime" BU_SG_REL_ Motor_Diesel_MQB SG_ 262 ESP_Schwelle_Unterdruck 500;
BA_REL_ "GenSigTimeoutTime" BU_SG_REL_ Motor_Hybrid_MQB SG_ 262 ESP_Schwelle_Unterdruck 500;
BA_REL_ "GenSigTimeoutTime" BU_SG_REL_ Motor_Otto_MQB SG_ 262 ESP_Schwelle_Unterdruck 500;
BA_REL_ "GenSigTimeoutTime" BU_SG_REL_ Airbag_MQB SG_ 262 ESP_Bremsdruck 500;
BA_REL_ "GenSigTimeoutTime" BU_SG_REL_ Getriebe_DQ_Hybrid_MQB SG_ 262 ESP_Bremsdruck 500;
BA_REL_ "GenSigTimeoutTime" BU_SG_REL_ Getriebe_DQ_MQB SG_ 262 ESP_Bremsdruck 500;
BA_REL_ "GenSigTimeoutTime" BU_SG_REL_ Motor_Diesel_MQB SG_ 262 ESP_Bremsdruck 500;
BA_REL_ "GenSigTimeoutTime" BU_SG_REL_ Motor_Hybrid_MQB SG_ 262 ESP_Bremsdruck 500;
BA_REL_ "GenSigTimeoutTime" BU_SG_REL_ Motor_Otto_MQB SG_ 262 ESP_Bremsdruck 500;
BA_REL_ "GenSigTimeoutTime" BU_SG_REL_ Motor_Diesel_MQB SG_ 262 ESP_Fahrer_bremst 500;
BA_REL_ "GenSigTimeoutTime" BU_SG_REL_ Motor_Diesel_MQB SG_ 262 ESP_Fahrer_bremst 500;
BA_REL_ "GenSigTimeoutTime" BU_SG_REL_ Motor_Hybrid_MQB SG_ 262 ESP_Fahrer_bremst 500;
BA_REL_ "GenSigTimeoutTime" BU_SG_REL_ Motor_Hybrid_MQB SG_ 262 ESP_Fahrer_bremst 500;
BA_REL_ "GenSigTimeoutTime" BU_SG_REL_ Motor_Otto_MQB SG_ 262 ESP_Fahrer_bremst 500;
BA_REL_ "GenSigTimeoutTime" BU_SG_REL_ Motor_Otto_MQB SG_ 262 ESP_Fahrer_bremst 500;
BA_REL_ "GenSigTimeoutTime" BU_SG_REL_ Getriebe_DQ_Hybrid_MQB SG_ 262 ESP_Verz_TSK_aktiv 500;
BA_REL_ "GenSigTimeoutTime" BU_SG_REL_ Getriebe_DQ_MQB SG_ 262 ESP_Verz_TSK_aktiv 500;
BA_REL_ "GenSigTimeoutTime" BU_SG_REL_ Motor_Diesel_MQB SG_ 262 ESP_Verz_TSK_aktiv 500;
BA_REL_ "GenSigTimeoutTime" BU_SG_REL_ Motor_Hybrid_MQB SG_ 262 ESP_Verz_TSK_aktiv 500;
BA_REL_ "GenSigTimeoutTime" BU_SG_REL_ Motor_Otto_MQB SG_ 262 ESP_Verz_TSK_aktiv 500;
BA_REL_ "GenSigTimeoutTime" BU_SG_REL_ Motor_Diesel_MQB SG_ 262 ESP_Lenkeingriff_ADS 500;
BA_REL_ "GenSigTimeoutTime" BU_SG_REL_ Motor_Hybrid_MQB SG_ 262 ESP_Lenkeingriff_ADS 500;
BA_REL_ "GenSigTimeoutTime" BU_SG_REL_ Motor_Otto_MQB SG_ 262 ESP_Lenkeingriff_ADS 500;
BA_REL_ "GenSigTimeoutTime" BU_SG_REL_ Motor_Diesel_MQB SG_ 262 ESP_Konsistenz_TSK 500;
BA_REL_ "GenSigTimeoutTime" BU_SG_REL_ Motor_Hybrid_MQB SG_ 262 ESP_Konsistenz_TSK 500;
BA_REL_ "GenSigTimeoutTime" BU_SG_REL_ Motor_Otto_MQB SG_ 262 ESP_Konsistenz_TSK 500;
BA_REL_ "GenSigTimeoutTime" BU_SG_REL_ Getriebe_DQ_Hybrid_MQB SG_ 262 ESP_Bremsruck_AWV2 500;
BA_REL_ "GenSigTimeoutTime" BU_SG_REL_ Getriebe_DQ_MQB SG_ 262 ESP_Bremsruck_AWV2 500;
BA_REL_ "GenSigTimeoutTime" BU_SG_REL_ Motor_Diesel_MQB SG_ 262 ESP_Bremsruck_AWV2 500;
BA_REL_ "GenSigTimeoutTime" BU_SG_REL_ Motor_Hybrid_MQB SG_ 262 ESP_Bremsruck_AWV2 500;
BA_REL_ "GenSigTimeoutTime" BU_SG_REL_ Motor_Otto_MQB SG_ 262 ESP_Bremsruck_AWV2 500;
BA_REL_ "GenSigTimeoutTime" BU_SG_REL_ Motor_Diesel_MQB SG_ 262 ECD_Fehler 500;
BA_REL_ "GenSigTimeoutTime" BU_SG_REL_ Motor_Hybrid_MQB SG_ 262 ECD_Fehler 500;
BA_REL_ "GenSigTimeoutTime" BU_SG_REL_ Motor_Otto_MQB SG_ 262 ECD_Fehler 500;
BA_REL_ "GenSigTimeoutTime" BU_SG_REL_ Motor_Diesel_MQB SG_ 262 ECD_nicht_verfuegbar 500;
BA_REL_ "GenSigTimeoutTime" BU_SG_REL_ Motor_Hybrid_MQB SG_ 262 ECD_nicht_verfuegbar 500;
BA_REL_ "GenSigTimeoutTime" BU_SG_REL_ Motor_Otto_MQB SG_ 262 ECD_nicht_verfuegbar 500;
BA_REL_ "GenSigTimeoutTime" BU_SG_REL_ Motor_Diesel_MQB SG_ 262 ESP_Status_Bremsentemp 500;
BA_REL_ "GenSigTimeoutTime" BU_SG_REL_ Motor_Diesel_MQB SG_ 262 ESP_Status_Bremsentemp 500;
BA_REL_ "GenSigTimeoutTime" BU_SG_REL_ Motor_Hybrid_MQB SG_ 262 ESP_Status_Bremsentemp 500;
BA_REL_ "GenSigTimeoutTime" BU_SG_REL_ Motor_Hybrid_MQB SG_ 262 ESP_Status_Bremsentemp 500;
BA_REL_ "GenSigTimeoutTime" BU_SG_REL_ Motor_Otto_MQB SG_ 262 ESP_Status_Bremsentemp 500;
BA_REL_ "GenSigTimeoutTime" BU_SG_REL_ Motor_Otto_MQB SG_ 262 ESP_Status_Bremsentemp 500;
BA_REL_ "GenSigTimeoutTime" BU_SG_REL_ Getriebe_DQ_Hybrid_MQB SG_ 262 ESP_HDC_Standby 500;
BA_REL_ "GenSigTimeoutTime" BU_SG_REL_ Getriebe_DQ_MQB SG_ 262 ESP_HDC_Standby 500;
BA_REL_ "GenSigTimeoutTime" BU_SG_REL_ Motor_Diesel_MQB SG_ 262 ESP_Prefill_ausgeloest 500;
BA_REL_ "GenSigTimeoutTime" BU_SG_REL_ Motor_Hybrid_MQB SG_ 262 ESP_Prefill_ausgeloest 500;
BA_REL_ "GenSigTimeoutTime" BU_SG_REL_ Motor_Otto_MQB SG_ 262 ESP_Prefill_ausgeloest 500;
BA_REL_ "GenSigTimeoutTime" BU_SG_REL_ Getriebe_DQ_Hybrid_MQB SG_ 262 ESP_Status_Anfahrhilfe 500;
BA_REL_ "GenSigTimeoutTime" BU_SG_REL_ Getriebe_DQ_MQB SG_ 262 ESP_Status_Anfahrhilfe 500;
BA_REL_ "GenSigTimeoutTime" BU_SG_REL_ Motor_Diesel_MQB SG_ 262 ESP_Status_Anfahrhilfe 500;
BA_REL_ "GenSigTimeoutTime" BU_SG_REL_ Motor_Hybrid_MQB SG_ 262 ESP_Status_Anfahrhilfe 500;
BA_REL_ "GenSigTimeoutTime" BU_SG_REL_ Motor_Otto_MQB SG_ 262 ESP_Status_Anfahrhilfe 500;
BA_REL_ "GenSigTimeoutTime" BU_SG_REL_ Getriebe_DQ_Hybrid_MQB SG_ 262 ESP_HDC_aktiv 500;
BA_REL_ "GenSigTimeoutTime" BU_SG_REL_ Getriebe_DQ_MQB SG_ 262 ESP_HDC_aktiv 500;
BA_REL_ "GenSigTimeoutTime" BU_SG_REL_ Motor_Diesel_MQB SG_ 262 ESP_StartStopp_Info 500;
BA_REL_ "GenSigTimeoutTime" BU_SG_REL_ Motor_Otto_MQB SG_ 262 ESP_StartStopp_Info 500;
BA_REL_ "GenSigTimeoutTime" BU_SG_REL_ Motor_Diesel_MQB SG_ 262 ESP_BKV_Unterdruck 500;
BA_REL_ "GenSigTimeoutTime" BU_SG_REL_ Motor_Hybrid_MQB SG_ 262 ESP_BKV_Unterdruck 500;
BA_REL_ "GenSigTimeoutTime" BU_SG_REL_ Motor_Otto_MQB SG_ 262 ESP_BKV_Unterdruck 500;
BA_REL_ "GenSigTimeoutTime" BU_SG_REL_ Getriebe_DQ_Hybrid_MQB SG_ 262 ESP_Autohold_aktiv 500;
BA_REL_ "GenSigTimeoutTime" BU_SG_REL_ Getriebe_DQ_MQB SG_ 262 ESP_Autohold_aktiv 500;
BA_REL_ "GenSigTimeoutTime" BU_SG_REL_ Motor_Diesel_MQB SG_ 262 ESP_Autohold_aktiv 500;
BA_REL_ "GenSigTimeoutTime" BU_SG_REL_ Motor_Diesel_MQB SG_ 262 ESP_Autohold_aktiv 500;
BA_REL_ "GenSigTimeoutTime" BU_SG_REL_ Motor_Hybrid_MQB SG_ 262 ESP_Autohold_aktiv 500;
BA_REL_ "GenSigTimeoutTime" BU_SG_REL_ Motor_Hybrid_MQB SG_ 262 ESP_Autohold_aktiv 500;
BA_REL_ "GenSigTimeoutTime" BU_SG_REL_ Motor_Otto_MQB SG_ 262 ESP_Autohold_aktiv 500;
BA_REL_ "GenSigTimeoutTime" BU_SG_REL_ Motor_Otto_MQB SG_ 262 ESP_Autohold_aktiv 500;
BA_REL_ "GenSigTimeoutTime" BU_SG_REL_ Getriebe_DQ_Hybrid_MQB SG_ 262 ESP_FStatus_Anfahrhilfe 500;
BA_REL_ "GenSigTimeoutTime" BU_SG_REL_ Getriebe_DQ_MQB SG_ 262 ESP_FStatus_Anfahrhilfe 500;
BA_REL_ "GenSigTimeoutTime" BU_SG_REL_ Motor_Diesel_MQB SG_ 262 ECD_Bremslicht 500;
BA_REL_ "GenSigTimeoutTime" BU_SG_REL_ Motor_Hybrid_MQB SG_ 262 ECD_Bremslicht 500;
BA_REL_ "GenSigTimeoutTime" BU_SG_REL_ Motor_Otto_MQB SG_ 262 ECD_Bremslicht 500;
BA_REL_ "GenSigTimeoutTime" BU_SG_REL_ Motor_Diesel_MQB SG_ 262 ESP_Status_Bremsdruck 500;
BA_REL_ "GenSigTimeoutTime" BU_SG_REL_ Motor_Hybrid_MQB SG_ 262 ESP_Status_Bremsdruck 500;
BA_REL_ "GenSigTimeoutTime" BU_SG_REL_ Motor_Otto_MQB SG_ 262 ESP_Status_Bremsdruck 500;
BA_REL_ "GenSigTimeoutTime" BU_SG_REL_ Airbag_MQB SG_ 914 ESP_07_CRC 1000;
BA_REL_ "GenSigTimeoutTime" BU_SG_REL_ Motor_Diesel_MQB SG_ 914 ESP_07_CRC 1000;
BA_REL_ "GenSigTimeoutTime" BU_SG_REL_ Motor_Hybrid_MQB SG_ 914 ESP_07_CRC 1000;
BA_REL_ "GenSigTimeoutTime" BU_SG_REL_ Motor_Otto_MQB SG_ 914 ESP_07_CRC 1000;
BA_REL_ "GenSigTimeoutTime" BU_SG_REL_ Airbag_MQB SG_ 914 ESP_07_BZ 1000;
BA_REL_ "GenSigTimeoutTime" BU_SG_REL_ Motor_Diesel_MQB SG_ 914 ESP_07_BZ 1000;
BA_REL_ "GenSigTimeoutTime" BU_SG_REL_ Motor_Hybrid_MQB SG_ 914 ESP_07_BZ 1000;
BA_REL_ "GenSigTimeoutTime" BU_SG_REL_ Motor_Otto_MQB SG_ 914 ESP_07_BZ 1000;
BA_REL_ "GenSigTimeoutTime" BU_SG_REL_ Motor_Diesel_MQB SG_ 914 OBD_Fehler_Radsensor_HL 1000;
BA_REL_ "GenSigTimeoutTime" BU_SG_REL_ Motor_Hybrid_MQB SG_ 914 OBD_Fehler_Radsensor_HL 1000;
BA_REL_ "GenSigTimeoutTime" BU_SG_REL_ Motor_Otto_MQB SG_ 914 OBD_Fehler_Radsensor_HL 1000;
BA_REL_ "GenSigTimeoutTime" BU_SG_REL_ Motor_Diesel_MQB SG_ 914 OBD_Fehler_Radsensor_HR 1000;
BA_REL_ "GenSigTimeoutTime" BU_SG_REL_ Motor_Hybrid_MQB SG_ 914 OBD_Fehler_Radsensor_HR 1000;
BA_REL_ "GenSigTimeoutTime" BU_SG_REL_ Motor_Otto_MQB SG_ 914 OBD_Fehler_Radsensor_HR 1000;
BA_REL_ "GenSigTimeoutTime" BU_SG_REL_ Motor_Diesel_MQB SG_ 914 OBD_Fehler_Radsensor_VL 1000;
BA_REL_ "GenSigTimeoutTime" BU_SG_REL_ Motor_Hybrid_MQB SG_ 914 OBD_Fehler_Radsensor_VL 1000;
BA_REL_ "GenSigTimeoutTime" BU_SG_REL_ Motor_Otto_MQB SG_ 914 OBD_Fehler_Radsensor_VL 1000;
BA_REL_ "GenSigTimeoutTime" BU_SG_REL_ Motor_Diesel_MQB SG_ 914 OBD_Fehler_Radsensor_VR 1000;
BA_REL_ "GenSigTimeoutTime" BU_SG_REL_ Motor_Hybrid_MQB SG_ 914 OBD_Fehler_Radsensor_VR 1000;
BA_REL_ "GenSigTimeoutTime" BU_SG_REL_ Motor_Otto_MQB SG_ 914 OBD_Fehler_Radsensor_VR 1000;
BA_REL_ "GenSigTimeoutTime" BU_SG_REL_ Airbag_MQB SG_ 914 ESP_MKB_ausloesbar 1000;
BA_REL_ "GenSigTimeoutTime" BU_SG_REL_ Airbag_MQB SG_ 914 ESP_MKB_Status 1000;
BA_REL_ "GenSigTimeoutTime" BU_SG_REL_ Airbag_MQB SG_ 278 ESP_10_CRC 500;
BA_REL_ "GenSigTimeoutTime" BU_SG_REL_ Motor_Diesel_MQB SG_ 278 ESP_10_CRC 500;
BA_REL_ "GenSigTimeoutTime" BU_SG_REL_ Motor_Diesel_MQB SG_ 278 ESP_10_CRC 500;
BA_REL_ "GenSigTimeoutTime" BU_SG_REL_ Motor_Diesel_MQB SG_ 278 ESP_10_CRC 500;
BA_REL_ "GenSigTimeoutTime" BU_SG_REL_ Motor_Hybrid_MQB SG_ 278 ESP_10_CRC 500;
BA_REL_ "GenSigTimeoutTime" BU_SG_REL_ Motor_Hybrid_MQB SG_ 278 ESP_10_CRC 500;
BA_REL_ "GenSigTimeoutTime" BU_SG_REL_ Motor_Otto_MQB SG_ 278 ESP_10_CRC 500;
BA_REL_ "GenSigTimeoutTime" BU_SG_REL_ Motor_Otto_MQB SG_ 278 ESP_10_CRC 500;
BA_REL_ "GenSigTimeoutTime" BU_SG_REL_ Motor_Otto_MQB SG_ 278 ESP_10_CRC 500;
BA_REL_ "GenSigTimeoutTime" BU_SG_REL_ Airbag_MQB SG_ 278 ESP_10_BZ 500;
BA_REL_ "GenSigTimeoutTime" BU_SG_REL_ Motor_Diesel_MQB SG_ 278 ESP_10_BZ 500;
BA_REL_ "GenSigTimeoutTime" BU_SG_REL_ Motor_Diesel_MQB SG_ 278 ESP_10_BZ 500;
BA_REL_ "GenSigTimeoutTime" BU_SG_REL_ Motor_Diesel_MQB SG_ 278 ESP_10_BZ 500;
BA_REL_ "GenSigTimeoutTime" BU_SG_REL_ Motor_Hybrid_MQB SG_ 278 ESP_10_BZ 500;
BA_REL_ "GenSigTimeoutTime" BU_SG_REL_ Motor_Hybrid_MQB SG_ 278 ESP_10_BZ 500;
BA_REL_ "GenSigTimeoutTime" BU_SG_REL_ Motor_Otto_MQB SG_ 278 ESP_10_BZ 500;
BA_REL_ "GenSigTimeoutTime" BU_SG_REL_ Motor_Otto_MQB SG_ 278 ESP_10_BZ 500;
BA_REL_ "GenSigTimeoutTime" BU_SG_REL_ Motor_Otto_MQB SG_ 278 ESP_10_BZ 500;
BA_REL_ "GenSigTimeoutTime" BU_SG_REL_ Getriebe_DQ_Hybrid_MQB SG_ 278 ESP_QBit_Wegimpuls_VL 500;
BA_REL_ "GenSigTimeoutTime" BU_SG_REL_ Getriebe_DQ_MQB SG_ 278 ESP_QBit_Wegimpuls_VL 500;
BA_REL_ "GenSigTimeoutTime" BU_SG_REL_ Motor_Diesel_MQB SG_ 278 ESP_QBit_Wegimpuls_VL 500;
BA_REL_ "GenSigTimeoutTime" BU_SG_REL_ Motor_Diesel_MQB SG_ 278 ESP_QBit_Wegimpuls_VL 500;
BA_REL_ "GenSigTimeoutTime" BU_SG_REL_ Motor_Hybrid_MQB SG_ 278 ESP_QBit_Wegimpuls_VL 500;
BA_REL_ "GenSigTimeoutTime" BU_SG_REL_ Motor_Otto_MQB SG_ 278 ESP_QBit_Wegimpuls_VL 500;
BA_REL_ "GenSigTimeoutTime" BU_SG_REL_ Motor_Otto_MQB SG_ 278 ESP_QBit_Wegimpuls_VL 500;
BA_REL_ "GenSigTimeoutTime" BU_SG_REL_ Getriebe_DQ_Hybrid_MQB SG_ 278 ESP_QBit_Wegimpuls_VR 500;
BA_REL_ "GenSigTimeoutTime" BU_SG_REL_ Getriebe_DQ_MQB SG_ 278 ESP_QBit_Wegimpuls_VR 500;
BA_REL_ "GenSigTimeoutTime" BU_SG_REL_ Motor_Diesel_MQB SG_ 278 ESP_QBit_Wegimpuls_VR 500;
BA_REL_ "GenSigTimeoutTime" BU_SG_REL_ Motor_Diesel_MQB SG_ 278 ESP_QBit_Wegimpuls_VR 500;
BA_REL_ "GenSigTimeoutTime" BU_SG_REL_ Motor_Hybrid_MQB SG_ 278 ESP_QBit_Wegimpuls_VR 500;
BA_REL_ "GenSigTimeoutTime" BU_SG_REL_ Motor_Otto_MQB SG_ 278 ESP_QBit_Wegimpuls_VR 500;
BA_REL_ "GenSigTimeoutTime" BU_SG_REL_ Motor_Otto_MQB SG_ 278 ESP_QBit_Wegimpuls_VR 500;
BA_REL_ "GenSigTimeoutTime" BU_SG_REL_ Getriebe_DQ_Hybrid_MQB SG_ 278 ESP_QBit_Wegimpuls_HL 500;
BA_REL_ "GenSigTimeoutTime" BU_SG_REL_ Getriebe_DQ_MQB SG_ 278 ESP_QBit_Wegimpuls_HL 500;
BA_REL_ "GenSigTimeoutTime" BU_SG_REL_ Motor_Diesel_MQB SG_ 278 ESP_QBit_Wegimpuls_HL 500;
BA_REL_ "GenSigTimeoutTime" BU_SG_REL_ Motor_Diesel_MQB SG_ 278 ESP_QBit_Wegimpuls_HL 500;
BA_REL_ "GenSigTimeoutTime" BU_SG_REL_ Motor_Hybrid_MQB SG_ 278 ESP_QBit_Wegimpuls_HL 500;
BA_REL_ "GenSigTimeoutTime" BU_SG_REL_ Motor_Otto_MQB SG_ 278 ESP_QBit_Wegimpuls_HL 500;
BA_REL_ "GenSigTimeoutTime" BU_SG_REL_ Motor_Otto_MQB SG_ 278 ESP_QBit_Wegimpuls_HL 500;
BA_REL_ "GenSigTimeoutTime" BU_SG_REL_ Getriebe_DQ_Hybrid_MQB SG_ 278 ESP_QBit_Wegimpuls_HR 500;
BA_REL_ "GenSigTimeoutTime" BU_SG_REL_ Getriebe_DQ_MQB SG_ 278 ESP_QBit_Wegimpuls_HR 500;
BA_REL_ "GenSigTimeoutTime" BU_SG_REL_ Motor_Diesel_MQB SG_ 278 ESP_QBit_Wegimpuls_HR 500;
BA_REL_ "GenSigTimeoutTime" BU_SG_REL_ Motor_Diesel_MQB SG_ 278 ESP_QBit_Wegimpuls_HR 500;
BA_REL_ "GenSigTimeoutTime" BU_SG_REL_ Motor_Hybrid_MQB SG_ 278 ESP_QBit_Wegimpuls_HR 500;
BA_REL_ "GenSigTimeoutTime" BU_SG_REL_ Motor_Otto_MQB SG_ 278 ESP_QBit_Wegimpuls_HR 500;
BA_REL_ "GenSigTimeoutTime" BU_SG_REL_ Motor_Otto_MQB SG_ 278 ESP_QBit_Wegimpuls_HR 500;
BA_REL_ "GenSigTimeoutTime" BU_SG_REL_ Getriebe_DQ_Hybrid_MQB SG_ 278 ESP_Wegimpuls_VL 500;
BA_REL_ "GenSigTimeoutTime" BU_SG_REL_ Getriebe_DQ_MQB SG_ 278 ESP_Wegimpuls_VL 500;
BA_REL_ "GenSigTimeoutTime" BU_SG_REL_ Motor_Diesel_MQB SG_ 278 ESP_Wegimpuls_VL 500;
BA_REL_ "GenSigTimeoutTime" BU_SG_REL_ Motor_Diesel_MQB SG_ 278 ESP_Wegimpuls_VL 500;
BA_REL_ "GenSigTimeoutTime" BU_SG_REL_ Motor_Hybrid_MQB SG_ 278 ESP_Wegimpuls_VL 500;
BA_REL_ "GenSigTimeoutTime" BU_SG_REL_ Motor_Otto_MQB SG_ 278 ESP_Wegimpuls_VL 500;
BA_REL_ "GenSigTimeoutTime" BU_SG_REL_ Motor_Otto_MQB SG_ 278 ESP_Wegimpuls_VL 500;
BA_REL_ "GenSigTimeoutTime" BU_SG_REL_ Getriebe_DQ_Hybrid_MQB SG_ 278 ESP_Wegimpuls_VR 500;
BA_REL_ "GenSigTimeoutTime" BU_SG_REL_ Getriebe_DQ_MQB SG_ 278 ESP_Wegimpuls_VR 500;
BA_REL_ "GenSigTimeoutTime" BU_SG_REL_ Motor_Diesel_MQB SG_ 278 ESP_Wegimpuls_VR 500;
BA_REL_ "GenSigTimeoutTime" BU_SG_REL_ Motor_Diesel_MQB SG_ 278 ESP_Wegimpuls_VR 500;
BA_REL_ "GenSigTimeoutTime" BU_SG_REL_ Motor_Hybrid_MQB SG_ 278 ESP_Wegimpuls_VR 500;
BA_REL_ "GenSigTimeoutTime" BU_SG_REL_ Motor_Otto_MQB SG_ 278 ESP_Wegimpuls_VR 500;
BA_REL_ "GenSigTimeoutTime" BU_SG_REL_ Motor_Otto_MQB SG_ 278 ESP_Wegimpuls_VR 500;
BA_REL_ "GenSigTimeoutTime" BU_SG_REL_ Getriebe_DQ_Hybrid_MQB SG_ 278 ESP_Wegimpuls_HL 500;
BA_REL_ "GenSigTimeoutTime" BU_SG_REL_ Getriebe_DQ_MQB SG_ 278 ESP_Wegimpuls_HL 500;
BA_REL_ "GenSigTimeoutTime" BU_SG_REL_ Motor_Diesel_MQB SG_ 278 ESP_Wegimpuls_HL 500;
BA_REL_ "GenSigTimeoutTime" BU_SG_REL_ Motor_Diesel_MQB SG_ 278 ESP_Wegimpuls_HL 500;
BA_REL_ "GenSigTimeoutTime" BU_SG_REL_ Motor_Hybrid_MQB SG_ 278 ESP_Wegimpuls_HL 500;
BA_REL_ "GenSigTimeoutTime" BU_SG_REL_ Motor_Otto_MQB SG_ 278 ESP_Wegimpuls_HL 500;
BA_REL_ "GenSigTimeoutTime" BU_SG_REL_ Motor_Otto_MQB SG_ 278 ESP_Wegimpuls_HL 500;
BA_REL_ "GenSigTimeoutTime" BU_SG_REL_ Getriebe_DQ_Hybrid_MQB SG_ 278 ESP_Wegimpuls_HR 500;
BA_REL_ "GenSigTimeoutTime" BU_SG_REL_ Getriebe_DQ_MQB SG_ 278 ESP_Wegimpuls_HR 500;
BA_REL_ "GenSigTimeoutTime" BU_SG_REL_ Motor_Diesel_MQB SG_ 278 ESP_Wegimpuls_HR 500;
BA_REL_ "GenSigTimeoutTime" BU_SG_REL_ Motor_Diesel_MQB SG_ 278 ESP_Wegimpuls_HR 500;
BA_REL_ "GenSigTimeoutTime" BU_SG_REL_ Motor_Hybrid_MQB SG_ 278 ESP_Wegimpuls_HR 500;
BA_REL_ "GenSigTimeoutTime" BU_SG_REL_ Motor_Otto_MQB SG_ 278 ESP_Wegimpuls_HR 500;
BA_REL_ "GenSigTimeoutTime" BU_SG_REL_ Motor_Otto_MQB SG_ 278 ESP_Wegimpuls_HR 500;
BA_REL_ "GenSigTimeoutTime" BU_SG_REL_ Airbag_MQB SG_ 278 ESP_VL_Fahrtrichtung 500;
BA_REL_ "GenSigTimeoutTime" BU_SG_REL_ Getriebe_DQ_Hybrid_MQB SG_ 278 ESP_VL_Fahrtrichtung 500;
BA_REL_ "GenSigTimeoutTime" BU_SG_REL_ Getriebe_DQ_MQB SG_ 278 ESP_VL_Fahrtrichtung 500;
BA_REL_ "GenSigTimeoutTime" BU_SG_REL_ Motor_Diesel_MQB SG_ 278 ESP_VL_Fahrtrichtung 500;
BA_REL_ "GenSigTimeoutTime" BU_SG_REL_ Motor_Diesel_MQB SG_ 278 ESP_VL_Fahrtrichtung 500;
BA_REL_ "GenSigTimeoutTime" BU_SG_REL_ Motor_Hybrid_MQB SG_ 278 ESP_VL_Fahrtrichtung 500;
BA_REL_ "GenSigTimeoutTime" BU_SG_REL_ Motor_Otto_MQB SG_ 278 ESP_VL_Fahrtrichtung 500;
BA_REL_ "GenSigTimeoutTime" BU_SG_REL_ Motor_Otto_MQB SG_ 278 ESP_VL_Fahrtrichtung 500;
BA_REL_ "GenSigTimeoutTime" BU_SG_REL_ Airbag_MQB SG_ 278 ESP_VR_Fahrtrichtung 500;
BA_REL_ "GenSigTimeoutTime" BU_SG_REL_ Getriebe_DQ_Hybrid_MQB SG_ 278 ESP_VR_Fahrtrichtung 500;
BA_REL_ "GenSigTimeoutTime" BU_SG_REL_ Getriebe_DQ_MQB SG_ 278 ESP_VR_Fahrtrichtung 500;
BA_REL_ "GenSigTimeoutTime" BU_SG_REL_ Motor_Diesel_MQB SG_ 278 ESP_VR_Fahrtrichtung 500;
BA_REL_ "GenSigTimeoutTime" BU_SG_REL_ Motor_Diesel_MQB SG_ 278 ESP_VR_Fahrtrichtung 500;
BA_REL_ "GenSigTimeoutTime" BU_SG_REL_ Motor_Hybrid_MQB SG_ 278 ESP_VR_Fahrtrichtung 500;
BA_REL_ "GenSigTimeoutTime" BU_SG_REL_ Motor_Otto_MQB SG_ 278 ESP_VR_Fahrtrichtung 500;
BA_REL_ "GenSigTimeoutTime" BU_SG_REL_ Motor_Otto_MQB SG_ 278 ESP_VR_Fahrtrichtung 500;
BA_REL_ "GenSigTimeoutTime" BU_SG_REL_ Airbag_MQB SG_ 278 ESP_HL_Fahrtrichtung 500;
BA_REL_ "GenSigTimeoutTime" BU_SG_REL_ Getriebe_DQ_Hybrid_MQB SG_ 278 ESP_HL_Fahrtrichtung 500;
BA_REL_ "GenSigTimeoutTime" BU_SG_REL_ Getriebe_DQ_MQB SG_ 278 ESP_HL_Fahrtrichtung 500;
BA_REL_ "GenSigTimeoutTime" BU_SG_REL_ Motor_Diesel_MQB SG_ 278 ESP_HL_Fahrtrichtung 500;
BA_REL_ "GenSigTimeoutTime" BU_SG_REL_ Motor_Diesel_MQB SG_ 278 ESP_HL_Fahrtrichtung 500;
BA_REL_ "GenSigTimeoutTime" BU_SG_REL_ Motor_Hybrid_MQB SG_ 278 ESP_HL_Fahrtrichtung 500;
BA_REL_ "GenSigTimeoutTime" BU_SG_REL_ Motor_Otto_MQB SG_ 278 ESP_HL_Fahrtrichtung 500;
BA_REL_ "GenSigTimeoutTime" BU_SG_REL_ Motor_Otto_MQB SG_ 278 ESP_HL_Fahrtrichtung 500;
BA_REL_ "GenSigTimeoutTime" BU_SG_REL_ Airbag_MQB SG_ 278 ESP_HR_Fahrtrichtung 500;
BA_REL_ "GenSigTimeoutTime" BU_SG_REL_ Getriebe_DQ_Hybrid_MQB SG_ 278 ESP_HR_Fahrtrichtung 500;
BA_REL_ "GenSigTimeoutTime" BU_SG_REL_ Getriebe_DQ_MQB SG_ 278 ESP_HR_Fahrtrichtung 500;
BA_REL_ "GenSigTimeoutTime" BU_SG_REL_ Motor_Diesel_MQB SG_ 278 ESP_HR_Fahrtrichtung 500;
BA_REL_ "GenSigTimeoutTime" BU_SG_REL_ Motor_Diesel_MQB SG_ 278 ESP_HR_Fahrtrichtung 500;
BA_REL_ "GenSigTimeoutTime" BU_SG_REL_ Motor_Hybrid_MQB SG_ 278 ESP_HR_Fahrtrichtung 500;
BA_REL_ "GenSigTimeoutTime" BU_SG_REL_ Motor_Otto_MQB SG_ 278 ESP_HR_Fahrtrichtung 500;
BA_REL_ "GenSigTimeoutTime" BU_SG_REL_ Motor_Otto_MQB SG_ 278 ESP_HR_Fahrtrichtung 500;
BA_REL_ "GenSigTimeoutTime" BU_SG_REL_ Airbag_MQB SG_ 178 ESP_HL_Radgeschw_02 500;
BA_REL_ "GenSigTimeoutTime" BU_SG_REL_ Getriebe_DQ_Hybrid_MQB SG_ 178 ESP_HL_Radgeschw_02 500;
BA_REL_ "GenSigTimeoutTime" BU_SG_REL_ Getriebe_DQ_MQB SG_ 178 ESP_HL_Radgeschw_02 500;
BA_REL_ "GenSigTimeoutTime" BU_SG_REL_ Motor_Diesel_MQB SG_ 178 ESP_HL_Radgeschw_02 500;
BA_REL_ "GenSigTimeoutTime" BU_SG_REL_ Motor_Hybrid_MQB SG_ 178 ESP_HL_Radgeschw_02 500;
BA_REL_ "GenSigTimeoutTime" BU_SG_REL_ Motor_Otto_MQB SG_ 178 ESP_HL_Radgeschw_02 500;
BA_REL_ "GenSigTimeoutTime" BU_SG_REL_ Airbag_MQB SG_ 178 ESP_HR_Radgeschw_02 500;
BA_REL_ "GenSigTimeoutTime" BU_SG_REL_ Getriebe_DQ_Hybrid_MQB SG_ 178 ESP_HR_Radgeschw_02 500;
BA_REL_ "GenSigTimeoutTime" BU_SG_REL_ Getriebe_DQ_MQB SG_ 178 ESP_HR_Radgeschw_02 500;
BA_REL_ "GenSigTimeoutTime" BU_SG_REL_ Motor_Diesel_MQB SG_ 178 ESP_HR_Radgeschw_02 500;
BA_REL_ "GenSigTimeoutTime" BU_SG_REL_ Motor_Hybrid_MQB SG_ 178 ESP_HR_Radgeschw_02 500;
BA_REL_ "GenSigTimeoutTime" BU_SG_REL_ Motor_Otto_MQB SG_ 178 ESP_HR_Radgeschw_02 500;
BA_REL_ "GenSigTimeoutTime" BU_SG_REL_ Airbag_MQB SG_ 178 ESP_VL_Radgeschw_02 500;
BA_REL_ "GenSigTimeoutTime" BU_SG_REL_ Getriebe_DQ_Hybrid_MQB SG_ 178 ESP_VL_Radgeschw_02 500;
BA_REL_ "GenSigTimeoutTime" BU_SG_REL_ Getriebe_DQ_MQB SG_ 178 ESP_VL_Radgeschw_02 500;
BA_REL_ "GenSigTimeoutTime" BU_SG_REL_ Motor_Diesel_MQB SG_ 178 ESP_VL_Radgeschw_02 500;
BA_REL_ "GenSigTimeoutTime" BU_SG_REL_ Motor_Hybrid_MQB SG_ 178 ESP_VL_Radgeschw_02 500;
BA_REL_ "GenSigTimeoutTime" BU_SG_REL_ Motor_Otto_MQB SG_ 178 ESP_VL_Radgeschw_02 500;
BA_REL_ "GenSigTimeoutTime" BU_SG_REL_ Airbag_MQB SG_ 178 ESP_VR_Radgeschw_02 500;
BA_REL_ "GenSigTimeoutTime" BU_SG_REL_ Getriebe_DQ_Hybrid_MQB SG_ 178 ESP_VR_Radgeschw_02 500;
BA_REL_ "GenSigTimeoutTime" BU_SG_REL_ Getriebe_DQ_MQB SG_ 178 ESP_VR_Radgeschw_02 500;
BA_REL_ "GenSigTimeoutTime" BU_SG_REL_ Motor_Diesel_MQB SG_ 178 ESP_VR_Radgeschw_02 500;
BA_REL_ "GenSigTimeoutTime" BU_SG_REL_ Motor_Hybrid_MQB SG_ 178 ESP_VR_Radgeschw_02 500;
BA_REL_ "GenSigTimeoutTime" BU_SG_REL_ Motor_Otto_MQB SG_ 178 ESP_VR_Radgeschw_02 500;
BA_REL_ "GenSigTimeoutTime" BU_SG_REL_ Getriebe_DQ_Hybrid_MQB SG_ 1629 ESP_Zaehnezahl 5000;
BA_REL_ "GenSigTimeoutTime" BU_SG_REL_ Getriebe_DQ_MQB SG_ 1629 ESP_Zaehnezahl 5000;
BA_REL_ "GenSigTimeoutTime" BU_SG_REL_ Getriebe_DQ_Hybrid_MQB SG_ 1629 BR_QBit_Reifenumfang 5000;
BA_REL_ "GenSigTimeoutTime" BU_SG_REL_ Getriebe_DQ_MQB SG_ 1629 BR_QBit_Reifenumfang 5000;
BA_REL_ "GenSigTimeoutTime" BU_SG_REL_ Getriebe_DQ_Hybrid_MQB SG_ 1629 BR_Reifenumfang 5000;
BA_REL_ "GenSigTimeoutTime" BU_SG_REL_ Getriebe_DQ_MQB SG_ 1629 BR_Reifenumfang 5000;
BA_REL_ "GenSigTimeoutTime" BU_SG_REL_ Airbag_MQB SG_ 253 ESP_21_CRC 500;
BA_REL_ "GenSigTimeoutTime" BU_SG_REL_ Airbag_MQB SG_ 253 ESP_21_CRC 500;
BA_REL_ "GenSigTimeoutTime" BU_SG_REL_ Getriebe_DQ_Hybrid_MQB SG_ 253 ESP_21_CRC 500;
BA_REL_ "GenSigTimeoutTime" BU_SG_REL_ Getriebe_DQ_MQB SG_ 253 ESP_21_CRC 500;
BA_REL_ "GenSigTimeoutTime" BU_SG_REL_ LEH_MQB SG_ 253 ESP_21_CRC 500;
BA_REL_ "GenSigTimeoutTime" BU_SG_REL_ Motor_Diesel_MQB SG_ 253 ESP_21_CRC 500;
BA_REL_ "GenSigTimeoutTime" BU_SG_REL_ Motor_Diesel_MQB SG_ 253 ESP_21_CRC 500;
BA_REL_ "GenSigTimeoutTime" BU_SG_REL_ Motor_Hybrid_MQB SG_ 253 ESP_21_CRC 500;
BA_REL_ "GenSigTimeoutTime" BU_SG_REL_ Motor_Hybrid_MQB SG_ 253 ESP_21_CRC 500;
BA_REL_ "GenSigTimeoutTime" BU_SG_REL_ Motor_Otto_MQB SG_ 253 ESP_21_CRC 500;
BA_REL_ "GenSigTimeoutTime" BU_SG_REL_ Motor_Otto_MQB SG_ 253 ESP_21_CRC 500;
BA_REL_ "GenSigTimeoutTime" BU_SG_REL_ Airbag_MQB SG_ 253 ESP_21_BZ 500;
BA_REL_ "GenSigTimeoutTime" BU_SG_REL_ Airbag_MQB SG_ 253 ESP_21_BZ 500;
BA_REL_ "GenSigTimeoutTime" BU_SG_REL_ BMS_MQB SG_ 253 ESP_21_BZ 500;
BA_REL_ "GenSigTimeoutTime" BU_SG_REL_ Getriebe_DQ_Hybrid_MQB SG_ 253 ESP_21_BZ 500;
BA_REL_ "GenSigTimeoutTime" BU_SG_REL_ Getriebe_DQ_MQB SG_ 253 ESP_21_BZ 500;
BA_REL_ "GenSigTimeoutTime" BU_SG_REL_ LEH_MQB SG_ 253 ESP_21_BZ 500;
BA_REL_ "GenSigTimeoutTime" BU_SG_REL_ Motor_Diesel_MQB SG_ 253 ESP_21_BZ 500;
BA_REL_ "GenSigTimeoutTime" BU_SG_REL_ Motor_Diesel_MQB SG_ 253 ESP_21_BZ 500;
BA_REL_ "GenSigTimeoutTime" BU_SG_REL_ Motor_Hybrid_MQB SG_ 253 ESP_21_BZ 500;
BA_REL_ "GenSigTimeoutTime" BU_SG_REL_ Motor_Hybrid_MQB SG_ 253 ESP_21_BZ 500;
BA_REL_ "GenSigTimeoutTime" BU_SG_REL_ Motor_Otto_MQB SG_ 253 ESP_21_BZ 500;
BA_REL_ "GenSigTimeoutTime" BU_SG_REL_ Motor_Otto_MQB SG_ 253 ESP_21_BZ 500;
BA_REL_ "GenSigTimeoutTime" BU_SG_REL_ Motor_Diesel_MQB SG_ 253 BR_Eingriffsmoment 500;
BA_REL_ "GenSigTimeoutTime" BU_SG_REL_ Motor_Hybrid_MQB SG_ 253 BR_Eingriffsmoment 500;
BA_REL_ "GenSigTimeoutTime" BU_SG_REL_ Motor_Otto_MQB SG_ 253 BR_Eingriffsmoment 500;
BA_REL_ "GenSigTimeoutTime" BU_SG_REL_ Airbag_MQB SG_ 253 ESP_v_Signal 500;
BA_REL_ "GenSigTimeoutTime" BU_SG_REL_ Airbag_MQB SG_ 253 ESP_v_Signal 500;
BA_REL_ "GenSigTimeoutTime" BU_SG_REL_ BMS_MQB SG_ 253 ESP_v_Signal 500;
BA_REL_ "GenSigTimeoutTime" BU_SG_REL_ Getriebe_DQ_Hybrid_MQB SG_ 253 ESP_v_Signal 500;
BA_REL_ "GenSigTimeoutTime" BU_SG_REL_ Getriebe_DQ_MQB SG_ 253 ESP_v_Signal 500;
BA_REL_ "GenSigTimeoutTime" BU_SG_REL_ LEH_MQB SG_ 253 ESP_v_Signal 500;
BA_REL_ "GenSigTimeoutTime" BU_SG_REL_ Motor_Diesel_MQB SG_ 253 ESP_v_Signal 500;
BA_REL_ "GenSigTimeoutTime" BU_SG_REL_ Motor_Diesel_MQB SG_ 253 ESP_v_Signal 500;
BA_REL_ "GenSigTimeoutTime" BU_SG_REL_ Motor_Hybrid_MQB SG_ 253 ESP_v_Signal 500;
BA_REL_ "GenSigTimeoutTime" BU_SG_REL_ Motor_Hybrid_MQB SG_ 253 ESP_v_Signal 500;
BA_REL_ "GenSigTimeoutTime" BU_SG_REL_ Motor_Otto_MQB SG_ 253 ESP_v_Signal 500;
BA_REL_ "GenSigTimeoutTime" BU_SG_REL_ Motor_Otto_MQB SG_ 253 ESP_v_Signal 500;
BA_REL_ "GenSigTimeoutTime" BU_SG_REL_ SAK_MQB SG_ 253 ESP_v_Signal 500;
BA_REL_ "GenSigTimeoutTime" BU_SG_REL_ Airbag_MQB SG_ 253 ASR_Tastung_passiv 500;
BA_REL_ "GenSigTimeoutTime" BU_SG_REL_ Getriebe_DQ_Hybrid_MQB SG_ 253 ASR_Tastung_passiv 500;
BA_REL_ "GenSigTimeoutTime" BU_SG_REL_ Getriebe_DQ_MQB SG_ 253 ASR_Tastung_passiv 500;
BA_REL_ "GenSigTimeoutTime" BU_SG_REL_ Motor_Diesel_MQB SG_ 253 ASR_Tastung_passiv 500;
BA_REL_ "GenSigTimeoutTime" BU_SG_REL_ Motor_Diesel_MQB SG_ 253 ASR_Tastung_passiv 500;
BA_REL_ "GenSigTimeoutTime" BU_SG_REL_ Motor_Hybrid_MQB SG_ 253 ASR_Tastung_passiv 500;
BA_REL_ "GenSigTimeoutTime" BU_SG_REL_ Motor_Hybrid_MQB SG_ 253 ASR_Tastung_passiv 500;
BA_REL_ "GenSigTimeoutTime" BU_SG_REL_ Motor_Otto_MQB SG_ 253 ASR_Tastung_passiv 500;
BA_REL_ "GenSigTimeoutTime" BU_SG_REL_ Motor_Otto_MQB SG_ 253 ASR_Tastung_passiv 500;
BA_REL_ "GenSigTimeoutTime" BU_SG_REL_ Airbag_MQB SG_ 253 ESP_Tastung_passiv 500;
BA_REL_ "GenSigTimeoutTime" BU_SG_REL_ Getriebe_DQ_Hybrid_MQB SG_ 253 ESP_Tastung_passiv 500;
BA_REL_ "GenSigTimeoutTime" BU_SG_REL_ Getriebe_DQ_MQB SG_ 253 ESP_Tastung_passiv 500;
BA_REL_ "GenSigTimeoutTime" BU_SG_REL_ Motor_Diesel_MQB SG_ 253 ESP_Tastung_passiv 500;
BA_REL_ "GenSigTimeoutTime" BU_SG_REL_ Motor_Diesel_MQB SG_ 253 ESP_Tastung_passiv 500;
BA_REL_ "GenSigTimeoutTime" BU_SG_REL_ Motor_Hybrid_MQB SG_ 253 ESP_Tastung_passiv 500;
BA_REL_ "GenSigTimeoutTime" BU_SG_REL_ Motor_Hybrid_MQB SG_ 253 ESP_Tastung_passiv 500;
BA_REL_ "GenSigTimeoutTime" BU_SG_REL_ Motor_Otto_MQB SG_ 253 ESP_Tastung_passiv 500;
BA_REL_ "GenSigTimeoutTime" BU_SG_REL_ Motor_Otto_MQB SG_ 253 ESP_Tastung_passiv 500;
BA_REL_ "GenSigTimeoutTime" BU_SG_REL_ Airbag_MQB SG_ 253 ESP_Systemstatus 500;
BA_REL_ "GenSigTimeoutTime" BU_SG_REL_ Getriebe_DQ_Hybrid_MQB SG_ 253 ESP_Systemstatus 500;
BA_REL_ "GenSigTimeoutTime" BU_SG_REL_ Getriebe_DQ_MQB SG_ 253 ESP_Systemstatus 500;
BA_REL_ "GenSigTimeoutTime" BU_SG_REL_ Motor_Diesel_MQB SG_ 253 ESP_Systemstatus 500;
BA_REL_ "GenSigTimeoutTime" BU_SG_REL_ Motor_Diesel_MQB SG_ 253 ESP_Systemstatus 500;
BA_REL_ "GenSigTimeoutTime" BU_SG_REL_ Motor_Hybrid_MQB SG_ 253 ESP_Systemstatus 500;
BA_REL_ "GenSigTimeoutTime" BU_SG_REL_ Motor_Hybrid_MQB SG_ 253 ESP_Systemstatus 500;
BA_REL_ "GenSigTimeoutTime" BU_SG_REL_ Motor_Otto_MQB SG_ 253 ESP_Systemstatus 500;
BA_REL_ "GenSigTimeoutTime" BU_SG_REL_ Motor_Otto_MQB SG_ 253 ESP_Systemstatus 500;
BA_REL_ "GenSigTimeoutTime" BU_SG_REL_ Getriebe_DQ_Hybrid_MQB SG_ 253 ASR_Schalteingriff 500;
BA_REL_ "GenSigTimeoutTime" BU_SG_REL_ Getriebe_DQ_MQB SG_ 253 ASR_Schalteingriff 500;
BA_REL_ "GenSigTimeoutTime" BU_SG_REL_ Motor_Diesel_MQB SG_ 253 ESP_Haltebestaetigung 500;
BA_REL_ "GenSigTimeoutTime" BU_SG_REL_ Motor_Hybrid_MQB SG_ 253 ESP_Haltebestaetigung 500;
BA_REL_ "GenSigTimeoutTime" BU_SG_REL_ Motor_Otto_MQB SG_ 253 ESP_Haltebestaetigung 500;
BA_REL_ "GenSigTimeoutTime" BU_SG_REL_ Airbag_MQB SG_ 253 ESP_QBit_v_Signal 500;
BA_REL_ "GenSigTimeoutTime" BU_SG_REL_ Airbag_MQB SG_ 253 ESP_QBit_v_Signal 500;
BA_REL_ "GenSigTimeoutTime" BU_SG_REL_ Getriebe_DQ_Hybrid_MQB SG_ 253 ESP_QBit_v_Signal 500;
BA_REL_ "GenSigTimeoutTime" BU_SG_REL_ Getriebe_DQ_MQB SG_ 253 ESP_QBit_v_Signal 500;
BA_REL_ "GenSigTimeoutTime" BU_SG_REL_ LEH_MQB SG_ 253 ESP_QBit_v_Signal 500;
BA_REL_ "GenSigTimeoutTime" BU_SG_REL_ Motor_Diesel_MQB SG_ 253 ESP_QBit_v_Signal 500;
BA_REL_ "GenSigTimeoutTime" BU_SG_REL_ Motor_Diesel_MQB SG_ 253 ESP_QBit_v_Signal 500;
BA_REL_ "GenSigTimeoutTime" BU_SG_REL_ Motor_Hybrid_MQB SG_ 253 ESP_QBit_v_Signal 500;
BA_REL_ "GenSigTimeoutTime" BU_SG_REL_ Motor_Hybrid_MQB SG_ 253 ESP_QBit_v_Signal 500;
BA_REL_ "GenSigTimeoutTime" BU_SG_REL_ Motor_Otto_MQB SG_ 253 ESP_QBit_v_Signal 500;
BA_REL_ "GenSigTimeoutTime" BU_SG_REL_ Motor_Otto_MQB SG_ 253 ESP_QBit_v_Signal 500;
BA_REL_ "GenSigTimeoutTime" BU_SG_REL_ Airbag_MQB SG_ 253 ABS_Bremsung 500;
BA_REL_ "GenSigTimeoutTime" BU_SG_REL_ Getriebe_DQ_Hybrid_MQB SG_ 253 ABS_Bremsung 500;
BA_REL_ "GenSigTimeoutTime" BU_SG_REL_ Getriebe_DQ_MQB SG_ 253 ABS_Bremsung 500;
BA_REL_ "GenSigTimeoutTime" BU_SG_REL_ Motor_Diesel_MQB SG_ 253 ABS_Bremsung 500;
BA_REL_ "GenSigTimeoutTime" BU_SG_REL_ Motor_Diesel_MQB SG_ 253 ABS_Bremsung 500;
BA_REL_ "GenSigTimeoutTime" BU_SG_REL_ Motor_Hybrid_MQB SG_ 253 ABS_Bremsung 500;
BA_REL_ "GenSigTimeoutTime" BU_SG_REL_ Motor_Hybrid_MQB SG_ 253 ABS_Bremsung 500;
BA_REL_ "GenSigTimeoutTime" BU_SG_REL_ Motor_Otto_MQB SG_ 253 ABS_Bremsung 500;
BA_REL_ "GenSigTimeoutTime" BU_SG_REL_ Motor_Otto_MQB SG_ 253 ABS_Bremsung 500;
BA_REL_ "GenSigTimeoutTime" BU_SG_REL_ Getriebe_DQ_Hybrid_MQB SG_ 253 ASR_Anf 500;
BA_REL_ "GenSigTimeoutTime" BU_SG_REL_ Getriebe_DQ_MQB SG_ 253 ASR_Anf 500;
BA_REL_ "GenSigTimeoutTime" BU_SG_REL_ Motor_Diesel_MQB SG_ 253 ASR_Anf 500;
BA_REL_ "GenSigTimeoutTime" BU_SG_REL_ Motor_Diesel_MQB SG_ 253 ASR_Anf 500;
BA_REL_ "GenSigTimeoutTime" BU_SG_REL_ Motor_Hybrid_MQB SG_ 253 ASR_Anf 500;
BA_REL_ "GenSigTimeoutTime" BU_SG_REL_ Motor_Hybrid_MQB SG_ 253 ASR_Anf 500;
BA_REL_ "GenSigTimeoutTime" BU_SG_REL_ Motor_Otto_MQB SG_ 253 ASR_Anf 500;
BA_REL_ "GenSigTimeoutTime" BU_SG_REL_ Motor_Otto_MQB SG_ 253 ASR_Anf 500;
BA_REL_ "GenSigTimeoutTime" BU_SG_REL_ Getriebe_DQ_Hybrid_MQB SG_ 253 MSR_Anf 500;
BA_REL_ "GenSigTimeoutTime" BU_SG_REL_ Getriebe_DQ_MQB SG_ 253 MSR_Anf 500;
BA_REL_ "GenSigTimeoutTime" BU_SG_REL_ Motor_Diesel_MQB SG_ 253 MSR_Anf 500;
BA_REL_ "GenSigTimeoutTime" BU_SG_REL_ Motor_Diesel_MQB SG_ 253 MSR_Anf 500;
BA_REL_ "GenSigTimeoutTime" BU_SG_REL_ Motor_Hybrid_MQB SG_ 253 MSR_Anf 500;
BA_REL_ "GenSigTimeoutTime" BU_SG_REL_ Motor_Hybrid_MQB SG_ 253 MSR_Anf 500;
BA_REL_ "GenSigTimeoutTime" BU_SG_REL_ Motor_Otto_MQB SG_ 253 MSR_Anf 500;
BA_REL_ "GenSigTimeoutTime" BU_SG_REL_ Motor_Otto_MQB SG_ 253 MSR_Anf 500;
BA_REL_ "GenSigTimeoutTime" BU_SG_REL_ Motor_Diesel_MQB SG_ 253 EBV_Eingriff 500;
BA_REL_ "GenSigTimeoutTime" BU_SG_REL_ Motor_Diesel_MQB SG_ 253 EBV_Eingriff 500;
BA_REL_ "GenSigTimeoutTime" BU_SG_REL_ Motor_Hybrid_MQB SG_ 253 EBV_Eingriff 500;
BA_REL_ "GenSigTimeoutTime" BU_SG_REL_ Motor_Hybrid_MQB SG_ 253 EBV_Eingriff 500;
BA_REL_ "GenSigTimeoutTime" BU_SG_REL_ Motor_Otto_MQB SG_ 253 EBV_Eingriff 500;
BA_REL_ "GenSigTimeoutTime" BU_SG_REL_ Motor_Otto_MQB SG_ 253 EBV_Eingriff 500;
BA_REL_ "GenSigTimeoutTime" BU_SG_REL_ Getriebe_DQ_Hybrid_MQB SG_ 253 EDS_Eingriff 500;
BA_REL_ "GenSigTimeoutTime" BU_SG_REL_ Getriebe_DQ_MQB SG_ 253 EDS_Eingriff 500;
BA_REL_ "GenSigTimeoutTime" BU_SG_REL_ Motor_Diesel_MQB SG_ 253 EDS_Eingriff 500;
BA_REL_ "GenSigTimeoutTime" BU_SG_REL_ Motor_Diesel_MQB SG_ 253 EDS_Eingriff 500;
BA_REL_ "GenSigTimeoutTime" BU_SG_REL_ Motor_Hybrid_MQB SG_ 253 EDS_Eingriff 500;
BA_REL_ "GenSigTimeoutTime" BU_SG_REL_ Motor_Hybrid_MQB SG_ 253 EDS_Eingriff 500;
BA_REL_ "GenSigTimeoutTime" BU_SG_REL_ Motor_Otto_MQB SG_ 253 EDS_Eingriff 500;
BA_REL_ "GenSigTimeoutTime" BU_SG_REL_ Motor_Otto_MQB SG_ 253 EDS_Eingriff 500;
BA_REL_ "GenSigTimeoutTime" BU_SG_REL_ Airbag_MQB SG_ 253 ESP_Eingriff 500;
BA_REL_ "GenSigTimeoutTime" BU_SG_REL_ Getriebe_DQ_Hybrid_MQB SG_ 253 ESP_Eingriff 500;
BA_REL_ "GenSigTimeoutTime" BU_SG_REL_ Getriebe_DQ_MQB SG_ 253 ESP_Eingriff 500;
BA_REL_ "GenSigTimeoutTime" BU_SG_REL_ Motor_Diesel_MQB SG_ 253 ESP_Eingriff 500;
BA_REL_ "GenSigTimeoutTime" BU_SG_REL_ Motor_Diesel_MQB SG_ 253 ESP_Eingriff 500;
BA_REL_ "GenSigTimeoutTime" BU_SG_REL_ Motor_Hybrid_MQB SG_ 253 ESP_Eingriff 500;
BA_REL_ "GenSigTimeoutTime" BU_SG_REL_ Motor_Hybrid_MQB SG_ 253 ESP_Eingriff 500;
BA_REL_ "GenSigTimeoutTime" BU_SG_REL_ Motor_Otto_MQB SG_ 253 ESP_Eingriff 500;
BA_REL_ "GenSigTimeoutTime" BU_SG_REL_ Motor_Otto_MQB SG_ 253 ESP_Eingriff 500;
BA_REL_ "GenSigTimeoutTime" BU_SG_REL_ Getriebe_DQ_Hybrid_MQB SG_ 253 ESP_ASP 500;
BA_REL_ "GenSigTimeoutTime" BU_SG_REL_ Getriebe_DQ_MQB SG_ 253 ESP_ASP 500;
BA_REL_ "GenSigTimeoutTime" BU_SG_REL_ Motor_Diesel_MQB SG_ 253 ESP_ASP 500;
BA_REL_ "GenSigTimeoutTime" BU_SG_REL_ Motor_Diesel_MQB SG_ 253 ESP_ASP 500;
BA_REL_ "GenSigTimeoutTime" BU_SG_REL_ Motor_Hybrid_MQB SG_ 253 ESP_ASP 500;
BA_REL_ "GenSigTimeoutTime" BU_SG_REL_ Motor_Hybrid_MQB SG_ 253 ESP_ASP 500;
BA_REL_ "GenSigTimeoutTime" BU_SG_REL_ Motor_Otto_MQB SG_ 253 ESP_ASP 500;
BA_REL_ "GenSigTimeoutTime" BU_SG_REL_ Motor_Otto_MQB SG_ 253 ESP_ASP 500;
BA_REL_ "GenSigTimeoutTime" BU_SG_REL_ Motor_Diesel_MQB SG_ 253 ESP_Anhaltevorgang_ACC_aktiv 500;
BA_REL_ "GenSigTimeoutTime" BU_SG_REL_ Motor_Hybrid_MQB SG_ 253 ESP_Anhaltevorgang_ACC_aktiv 500;
BA_REL_ "GenSigTimeoutTime" BU_SG_REL_ Motor_Otto_MQB SG_ 253 ESP_Anhaltevorgang_ACC_aktiv 500;
BA_REL_ "GenSigTimeoutTime" BU_SG_REL_ Airbag_MQB SG_ 987 BCM_01_alt 1000;
BA_REL_ "GenSigTimeoutTime" BU_SG_REL_ Motor_Diesel_MQB SG_ 987 SMLS_01_alt 1000;
BA_REL_ "GenSigTimeoutTime" BU_SG_REL_ Motor_Otto_MQB SG_ 987 SMLS_01_alt 1000;
BA_REL_ "GenSigTimeoutTime" BU_SG_REL_ Getriebe_DQ_Hybrid_MQB SG_ 987 ZV_02_alt 1000;
BA_REL_ "GenSigTimeoutTime" BU_SG_REL_ Getriebe_DQ_MQB SG_ 987 ZV_02_alt 1000;
BA_REL_ "GenSigTimeoutTime" BU_SG_REL_ Motor_Diesel_MQB SG_ 987 ZV_02_alt 1000;
BA_REL_ "GenSigTimeoutTime" BU_SG_REL_ Motor_Diesel_MQB SG_ 987 ZV_02_alt 1000;
BA_REL_ "GenSigTimeoutTime" BU_SG_REL_ Motor_Hybrid_MQB SG_ 987 ZV_02_alt 1000;
BA_REL_ "GenSigTimeoutTime" BU_SG_REL_ Motor_Otto_MQB SG_ 987 ZV_02_alt 1000;
BA_REL_ "GenSigTimeoutTime" BU_SG_REL_ Motor_Otto_MQB SG_ 987 ZV_02_alt 1000;
BA_REL_ "GenSigTimeoutTime" BU_SG_REL_ Motor_Diesel_MQB SG_ 987 Wischer_01_alt 1000;
BA_REL_ "GenSigTimeoutTime" BU_SG_REL_ Motor_Hybrid_MQB SG_ 987 Wischer_01_alt 1000;
BA_REL_ "GenSigTimeoutTime" BU_SG_REL_ Motor_Otto_MQB SG_ 987 Wischer_01_alt 1000;
BA_REL_ "GenSigTimeoutTime" BU_SG_REL_ Getriebe_DQ_Hybrid_MQB SG_ 987 Anhaenger_01_alt 1000;
BA_REL_ "GenSigTimeoutTime" BU_SG_REL_ Getriebe_DQ_MQB SG_ 987 Anhaenger_01_alt 1000;
BA_REL_ "GenSigTimeoutTime" BU_SG_REL_ Getriebe_DQ_Hybrid_MQB SG_ 987 Klima_Sensor_02_alt 1000;
BA_REL_ "GenSigTimeoutTime" BU_SG_REL_ Getriebe_DQ_MQB SG_ 987 Klima_Sensor_02_alt 1000;
BA_REL_ "GenSigTimeoutTime" BU_SG_REL_ Motor_Diesel_MQB SG_ 987 Klima_Sensor_02_alt 1000;
BA_REL_ "GenSigTimeoutTime" BU_SG_REL_ Motor_Hybrid_MQB SG_ 987 Klima_Sensor_02_alt 1000;
BA_REL_ "GenSigTimeoutTime" BU_SG_REL_ Motor_Otto_MQB SG_ 987 Klima_Sensor_02_alt 1000;
BA_REL_ "GenSigTimeoutTime" BU_SG_REL_ Airbag_MQB SG_ 987 VSG_01_alt 1000;
BA_REL_ "GenSigTimeoutTime" BU_SG_REL_ Airbag_MQB SG_ 987 VS_VD_offen_ver 1000;
BA_REL_ "GenSigTimeoutTime" BU_SG_REL_ Airbag_MQB SG_ 987 BCM1_Rueckfahrlicht_Schalter 1000;
BA_REL_ "GenSigTimeoutTime" BU_SG_REL_ Getriebe_DQ_Hybrid_MQB SG_ 987 ZV_FT_offen 1000;
BA_REL_ "GenSigTimeoutTime" BU_SG_REL_ Getriebe_DQ_MQB SG_ 987 ZV_FT_offen 1000;
BA_REL_ "GenSigTimeoutTime" BU_SG_REL_ Motor_Diesel_MQB SG_ 987 ZV_FT_offen 1000;
BA_REL_ "GenSigTimeoutTime" BU_SG_REL_ Motor_Diesel_MQB SG_ 987 ZV_FT_offen 1000;
BA_REL_ "GenSigTimeoutTime" BU_SG_REL_ Motor_Hybrid_MQB SG_ 987 ZV_FT_offen 1000;
BA_REL_ "GenSigTimeoutTime" BU_SG_REL_ Motor_Otto_MQB SG_ 987 ZV_FT_offen 1000;
BA_REL_ "GenSigTimeoutTime" BU_SG_REL_ Motor_Otto_MQB SG_ 987 ZV_FT_offen 1000;
BA_REL_ "GenSigTimeoutTime" BU_SG_REL_ Motor_Diesel_MQB SG_ 987 Wischer_vorne_aktiv 1000;
BA_REL_ "GenSigTimeoutTime" BU_SG_REL_ Motor_Hybrid_MQB SG_ 987 Wischer_vorne_aktiv 1000;
BA_REL_ "GenSigTimeoutTime" BU_SG_REL_ Motor_Otto_MQB SG_ 987 Wischer_vorne_aktiv 1000;
BA_REL_ "GenSigTimeoutTime" BU_SG_REL_ Getriebe_DQ_Hybrid_MQB SG_ 987 AAG_Anhaenger_erkannt 1000;
BA_REL_ "GenSigTimeoutTime" BU_SG_REL_ Getriebe_DQ_MQB SG_ 987 AAG_Anhaenger_erkannt 1000;
BA_REL_ "GenSigTimeoutTime" BU_SG_REL_ Motor_Diesel_MQB SG_ 987 BH_Blinker_li 1000;
BA_REL_ "GenSigTimeoutTime" BU_SG_REL_ Motor_Otto_MQB SG_ 987 BH_Blinker_li 1000;
BA_REL_ "GenSigTimeoutTime" BU_SG_REL_ Motor_Diesel_MQB SG_ 987 BH_Blinker_re 1000;
BA_REL_ "GenSigTimeoutTime" BU_SG_REL_ Motor_Otto_MQB SG_ 987 BH_Blinker_re 1000;
BA_REL_ "GenSigTimeoutTime" BU_SG_REL_ Getriebe_DQ_Hybrid_MQB SG_ 987 BCM1_OBD_FStatus_ATemp 1000;
BA_REL_ "GenSigTimeoutTime" BU_SG_REL_ Getriebe_DQ_MQB SG_ 987 BCM1_OBD_FStatus_ATemp 1000;
BA_REL_ "GenSigTimeoutTime" BU_SG_REL_ Motor_Diesel_MQB SG_ 987 BCM1_OBD_FStatus_ATemp 1000;
BA_REL_ "GenSigTimeoutTime" BU_SG_REL_ Motor_Hybrid_MQB SG_ 987 BCM1_OBD_FStatus_ATemp 1000;
BA_REL_ "GenSigTimeoutTime" BU_SG_REL_ Motor_Otto_MQB SG_ 987 BCM1_OBD_FStatus_ATemp 1000;
BA_REL_ "GenSigTimeoutTime" BU_SG_REL_ Getriebe_DQ_Hybrid_MQB SG_ 987 BCM1_Aussen_Temp_ungef 1000;
BA_REL_ "GenSigTimeoutTime" BU_SG_REL_ Getriebe_DQ_MQB SG_ 987 BCM1_Aussen_Temp_ungef 1000;
BA_REL_ "GenSigTimeoutTime" BU_SG_REL_ Motor_Diesel_MQB SG_ 987 BCM1_Aussen_Temp_ungef 1000;
BA_REL_ "GenSigTimeoutTime" BU_SG_REL_ Motor_Hybrid_MQB SG_ 987 BCM1_Aussen_Temp_ungef 1000;
BA_REL_ "GenSigTimeoutTime" BU_SG_REL_ Motor_Otto_MQB SG_ 987 BCM1_Aussen_Temp_ungef 1000;
BA_REL_ "GenSigTimeoutTime" BU_SG_REL_ Motor_Diesel_MQB SG_ 989 LH_EPS_01_alt 1000;
BA_REL_ "GenSigTimeoutTime" BU_SG_REL_ Motor_Diesel_MQB SG_ 989 Kessy_04_alt 1000;
BA_REL_ "GenSigTimeoutTime" BU_SG_REL_ Motor_Otto_MQB SG_ 989 Kessy_04_alt 1000;
BA_REL_ "GenSigTimeoutTime" BU_SG_REL_ Getriebe_DQ_Hybrid_MQB SG_ 989 LIN_2_alt 1000;
BA_REL_ "GenSigTimeoutTime" BU_SG_REL_ Getriebe_DQ_MQB SG_ 989 LIN_2_alt 1000;
BA_REL_ "GenSigTimeoutTime" BU_SG_REL_ Motor_Diesel_MQB SG_ 989 MFG_01_alt 1000;
BA_REL_ "GenSigTimeoutTime" BU_SG_REL_ Motor_Otto_MQB SG_ 989 MFG_01_alt 1000;
BA_REL_ "GenSigTimeoutTime" BU_SG_REL_ BMS_MQB SG_ 989 Klima_02_alt 1000;
BA_REL_ "GenSigTimeoutTime" BU_SG_REL_ Motor_Diesel_MQB SG_ 989 Parkhilfe_01_alt 1000;
BA_REL_ "GenSigTimeoutTime" BU_SG_REL_ Motor_Otto_MQB SG_ 989 Parkhilfe_01_alt 1000;
BA_REL_ "GenSigTimeoutTime" BU_SG_REL_ Motor_Diesel_MQB SG_ 989 ELV_01_alt 1000;
BA_REL_ "GenSigTimeoutTime" BU_SG_REL_ Motor_Hybrid_MQB SG_ 989 ELV_01_alt 1000;
BA_REL_ "GenSigTimeoutTime" BU_SG_REL_ Motor_Otto_MQB SG_ 989 ELV_01_alt 1000;
BA_REL_ "GenSigTimeoutTime" BU_SG_REL_ Motor_Diesel_MQB SG_ 989 KY_StartStopp_Info 1000;
BA_REL_ "GenSigTimeoutTime" BU_SG_REL_ Motor_Otto_MQB SG_ 989 KY_StartStopp_Info 1000;
BA_REL_ "GenSigTimeoutTime" BU_SG_REL_ Motor_Diesel_MQB SG_ 989 PH_StartStopp_Info 1000;
BA_REL_ "GenSigTimeoutTime" BU_SG_REL_ Motor_Otto_MQB SG_ 989 PH_StartStopp_Info 1000;
BA_REL_ "GenSigTimeoutTime" BU_SG_REL_ Motor_Diesel_MQB SG_ 989 EPS_Lenkerposition 1000;
BA_REL_ "GenSigTimeoutTime" BU_SG_REL_ Motor_Diesel_MQB SG_ 989 ELV_Anf_Klemme_50 1000;
BA_REL_ "GenSigTimeoutTime" BU_SG_REL_ Motor_Hybrid_MQB SG_ 989 ELV_Anf_Klemme_50 1000;
BA_REL_ "GenSigTimeoutTime" BU_SG_REL_ Motor_Otto_MQB SG_ 989 ELV_Anf_Klemme_50 1000;
BA_REL_ "GenSigTimeoutTime" BU_SG_REL_ Motor_Diesel_MQB SG_ 989 MF_StartStopp_Info 1000;
BA_REL_ "GenSigTimeoutTime" BU_SG_REL_ Motor_Otto_MQB SG_ 989 MF_StartStopp_Info 1000;
BA_REL_ "GenSigTimeoutTime" BU_SG_REL_ BMS_MQB SG_ 989 KL_Geblaesespannung_Soll 1000;
BA_REL_ "GenSigTimeoutTime" BU_SG_REL_ Getriebe_DQ_Hybrid_MQB SG_ 989 MFL_Tip_Down 1000;
BA_REL_ "GenSigTimeoutTime" BU_SG_REL_ Getriebe_DQ_MQB SG_ 989 MFL_Tip_Down 1000;
BA_REL_ "GenSigTimeoutTime" BU_SG_REL_ Getriebe_DQ_Hybrid_MQB SG_ 989 MFL_Tip_Up 1000;
BA_REL_ "GenSigTimeoutTime" BU_SG_REL_ Getriebe_DQ_MQB SG_ 989 MFL_Tip_Up 1000;
BA_REL_ "GenSigTimeoutTime" BU_SG_REL_ Getriebe_DQ_Hybrid_MQB SG_ 989 LS_Tiptronic_Fehler 1000;
BA_REL_ "GenSigTimeoutTime" BU_SG_REL_ Getriebe_DQ_MQB SG_ 989 LS_Tiptronic_Fehler 1000;
BA_REL_ "GenSigTimeoutTime" BU_SG_REL_ Waehlhebel_MQB SG_ 296 GE_WH_Sperre 500;
BA_REL_ "GenSigTimeoutTime" BU_SG_REL_ Waehlhebel_MQB SG_ 296 GE_Ausleuchtungsmode 500;
BA_REL_ "GenSigTimeoutTime" BU_SG_REL_ Waehlhebel_MQB SG_ 296 GE_Test_Freigabe 500;
BA_REL_ "GenSigTimeoutTime" BU_SG_REL_ Waehlhebel_MQB SG_ 296 GE_Ist_Fahrstufe 500;
BA_REL_ "GenSigTimeoutTime" BU_SG_REL_ Waehlhebel_MQB SG_ 296 GE_Testparameter_1 500;
BA_REL_ "GenSigTimeoutTime" BU_SG_REL_ Waehlhebel_MQB SG_ 296 GE_Testparameter_2 500;
BA_REL_ "GenSigTimeoutTime" BU_SG_REL_ Motor_Diesel_MQB SG_ 173 Getriebe_11_CRC 500;
BA_REL_ "GenSigTimeoutTime" BU_SG_REL_ Motor_Diesel_MQB SG_ 173 Getriebe_11_CRC 500;
BA_REL_ "GenSigTimeoutTime" BU_SG_REL_ Motor_Hybrid_MQB SG_ 173 Getriebe_11_CRC 500;
BA_REL_ "GenSigTimeoutTime" BU_SG_REL_ Motor_Hybrid_MQB SG_ 173 Getriebe_11_CRC 500;
BA_REL_ "GenSigTimeoutTime" BU_SG_REL_ Motor_Otto_MQB SG_ 173 Getriebe_11_CRC 500;
BA_REL_ "GenSigTimeoutTime" BU_SG_REL_ Motor_Otto_MQB SG_ 173 Getriebe_11_CRC 500;
BA_REL_ "GenSigTimeoutTime" BU_SG_REL_ Motor_Diesel_MQB SG_ 173 Getriebe_11_BZ 500;
BA_REL_ "GenSigTimeoutTime" BU_SG_REL_ Motor_Diesel_MQB SG_ 173 Getriebe_11_BZ 500;
BA_REL_ "GenSigTimeoutTime" BU_SG_REL_ Motor_Hybrid_MQB SG_ 173 Getriebe_11_BZ 500;
BA_REL_ "GenSigTimeoutTime" BU_SG_REL_ Motor_Hybrid_MQB SG_ 173 Getriebe_11_BZ 500;
BA_REL_ "GenSigTimeoutTime" BU_SG_REL_ Motor_Otto_MQB SG_ 173 Getriebe_11_BZ 500;
BA_REL_ "GenSigTimeoutTime" BU_SG_REL_ Motor_Otto_MQB SG_ 173 Getriebe_11_BZ 500;
BA_REL_ "GenSigTimeoutTime" BU_SG_REL_ Motor_Diesel_MQB SG_ 173 GE_MMom_Soll_02 500;
BA_REL_ "GenSigTimeoutTime" BU_SG_REL_ Motor_Hybrid_MQB SG_ 173 GE_MMom_Soll_02 500;
BA_REL_ "GenSigTimeoutTime" BU_SG_REL_ Motor_Otto_MQB SG_ 173 GE_MMom_Soll_02 500;
BA_REL_ "GenSigTimeoutTime" BU_SG_REL_ Motor_Diesel_MQB SG_ 173 GE_MMom_Vorhalt_02 500;
BA_REL_ "GenSigTimeoutTime" BU_SG_REL_ Motor_Hybrid_MQB SG_ 173 GE_MMom_Vorhalt_02 500;
BA_REL_ "GenSigTimeoutTime" BU_SG_REL_ Motor_Otto_MQB SG_ 173 GE_MMom_Vorhalt_02 500;
BA_REL_ "GenSigTimeoutTime" BU_SG_REL_ Motor_Diesel_MQB SG_ 173 GE_Uefkt 500;
BA_REL_ "GenSigTimeoutTime" BU_SG_REL_ Motor_Diesel_MQB SG_ 173 GE_Uefkt 500;
BA_REL_ "GenSigTimeoutTime" BU_SG_REL_ Motor_Hybrid_MQB SG_ 173 GE_Uefkt 500;
BA_REL_ "GenSigTimeoutTime" BU_SG_REL_ Motor_Hybrid_MQB SG_ 173 GE_Uefkt 500;
BA_REL_ "GenSigTimeoutTime" BU_SG_REL_ Motor_Otto_MQB SG_ 173 GE_Uefkt 500;
BA_REL_ "GenSigTimeoutTime" BU_SG_REL_ Motor_Otto_MQB SG_ 173 GE_Uefkt 500;
BA_REL_ "GenSigTimeoutTime" BU_SG_REL_ Gateway_MQB SG_ 173 GE_Fahrstufe 500;
BA_REL_ "GenSigTimeoutTime" BU_SG_REL_ Gateway_MQB SG_ 173 GE_Fahrstufe 500;
BA_REL_ "GenSigTimeoutTime" BU_SG_REL_ Motor_Diesel_MQB SG_ 173 GE_Fahrstufe 500;
BA_REL_ "GenSigTimeoutTime" BU_SG_REL_ Motor_Diesel_MQB SG_ 173 GE_Fahrstufe 500;
BA_REL_ "GenSigTimeoutTime" BU_SG_REL_ Motor_Hybrid_MQB SG_ 173 GE_Fahrstufe 500;
BA_REL_ "GenSigTimeoutTime" BU_SG_REL_ Motor_Hybrid_MQB SG_ 173 GE_Fahrstufe 500;
BA_REL_ "GenSigTimeoutTime" BU_SG_REL_ Motor_Otto_MQB SG_ 173 GE_Fahrstufe 500;
BA_REL_ "GenSigTimeoutTime" BU_SG_REL_ Motor_Otto_MQB SG_ 173 GE_Fahrstufe 500;
BA_REL_ "GenSigTimeoutTime" BU_SG_REL_ Motor_Diesel_MQB SG_ 173 GE_Schaltvorgang 500;
BA_REL_ "GenSigTimeoutTime" BU_SG_REL_ Motor_Hybrid_MQB SG_ 173 GE_Schaltvorgang 500;
BA_REL_ "GenSigTimeoutTime" BU_SG_REL_ Motor_Otto_MQB SG_ 173 GE_Schaltvorgang 500;
BA_REL_ "GenSigTimeoutTime" BU_SG_REL_ Motor_Diesel_MQB SG_ 173 GE_Status_Kupplung 500;
BA_REL_ "GenSigTimeoutTime" BU_SG_REL_ Motor_Hybrid_MQB SG_ 173 GE_Status_Kupplung 500;
BA_REL_ "GenSigTimeoutTime" BU_SG_REL_ Motor_Otto_MQB SG_ 173 GE_Status_Kupplung 500;
BA_REL_ "GenSigTimeoutTime" BU_SG_REL_ Motor_Diesel_MQB SG_ 173 GE_MMom_Status 500;
BA_REL_ "GenSigTimeoutTime" BU_SG_REL_ Motor_Hybrid_MQB SG_ 173 GE_MMom_Status 500;
BA_REL_ "GenSigTimeoutTime" BU_SG_REL_ Motor_Otto_MQB SG_ 173 GE_MMom_Status 500;
BA_REL_ "GenSigTimeoutTime" BU_SG_REL_ Motor_Diesel_MQB SG_ 173 GE_Freig_MMom_Vorhalt 500;
BA_REL_ "GenSigTimeoutTime" BU_SG_REL_ Motor_Hybrid_MQB SG_ 173 GE_Freig_MMom_Vorhalt 500;
BA_REL_ "GenSigTimeoutTime" BU_SG_REL_ Motor_Otto_MQB SG_ 173 GE_Freig_MMom_Vorhalt 500;
BA_REL_ "GenSigTimeoutTime" BU_SG_REL_ Motor_Hybrid_MQB SG_ 173 GE_Verbot_Ausblendung 500;
BA_REL_ "GenSigTimeoutTime" BU_SG_REL_ Motor_Otto_MQB SG_ 173 GE_Verbot_Ausblendung 500;
BA_REL_ "GenSigTimeoutTime" BU_SG_REL_ Motor_Diesel_MQB SG_ 173 GE_Zielgang 500;
BA_REL_ "GenSigTimeoutTime" BU_SG_REL_ Motor_Hybrid_MQB SG_ 173 GE_Zielgang 500;
BA_REL_ "GenSigTimeoutTime" BU_SG_REL_ Motor_Otto_MQB SG_ 173 GE_Zielgang 500;
BA_REL_ "GenSigTimeoutTime" BU_SG_REL_ Motor_Diesel_MQB SG_ 174 Getriebe_12_CRC 500;
BA_REL_ "GenSigTimeoutTime" BU_SG_REL_ Motor_Hybrid_MQB SG_ 174 Getriebe_12_CRC 500;
BA_REL_ "GenSigTimeoutTime" BU_SG_REL_ Motor_Otto_MQB SG_ 174 Getriebe_12_CRC 500;
BA_REL_ "GenSigTimeoutTime" BU_SG_REL_ Motor_Diesel_MQB SG_ 174 Getriebe_12_BZ 500;
BA_REL_ "GenSigTimeoutTime" BU_SG_REL_ Motor_Hybrid_MQB SG_ 174 Getriebe_12_BZ 500;
BA_REL_ "GenSigTimeoutTime" BU_SG_REL_ Motor_Otto_MQB SG_ 174 Getriebe_12_BZ 500;
BA_REL_ "GenSigTimeoutTime" BU_SG_REL_ Motor_Diesel_MQB SG_ 174 GE_Drehzahlmesser_Daempfung 500;
BA_REL_ "GenSigTimeoutTime" BU_SG_REL_ Motor_Hybrid_MQB SG_ 174 GE_Drehzahlmesser_Daempfung 500;
BA_REL_ "GenSigTimeoutTime" BU_SG_REL_ Motor_Otto_MQB SG_ 174 GE_Drehzahlmesser_Daempfung 500;
BA_REL_ "GenSigTimeoutTime" BU_SG_REL_ Motor_Diesel_MQB SG_ 174 GE_Schubabschalt_Unt 500;
BA_REL_ "GenSigTimeoutTime" BU_SG_REL_ Motor_Hybrid_MQB SG_ 174 GE_Schubabschalt_Unt 500;
BA_REL_ "GenSigTimeoutTime" BU_SG_REL_ Motor_Otto_MQB SG_ 174 GE_Schubabschalt_Unt 500;
BA_REL_ "GenSigTimeoutTime" BU_SG_REL_ Motor_Diesel_MQB SG_ 174 GE_Freigabe_Synchro 500;
BA_REL_ "GenSigTimeoutTime" BU_SG_REL_ Motor_Hybrid_MQB SG_ 174 GE_Freigabe_Synchro 500;
BA_REL_ "GenSigTimeoutTime" BU_SG_REL_ Motor_Otto_MQB SG_ 174 GE_Freigabe_Synchro 500;
BA_REL_ "GenSigTimeoutTime" BU_SG_REL_ Motor_Diesel_MQB SG_ 174 GE_Synchro_Wunschdrehz 500;
BA_REL_ "GenSigTimeoutTime" BU_SG_REL_ Motor_Hybrid_MQB SG_ 174 GE_Synchro_Wunschdrehz 500;
BA_REL_ "GenSigTimeoutTime" BU_SG_REL_ Motor_Otto_MQB SG_ 174 GE_Synchro_Wunschdrehz 500;
BA_REL_ "GenSigTimeoutTime" BU_SG_REL_ Motor_Diesel_MQB SG_ 174 GE_Synchro_Zeit 500;
BA_REL_ "GenSigTimeoutTime" BU_SG_REL_ Motor_Hybrid_MQB SG_ 174 GE_Synchro_Zeit 500;
BA_REL_ "GenSigTimeoutTime" BU_SG_REL_ Motor_Otto_MQB SG_ 174 GE_Synchro_Zeit 500;
BA_REL_ "GenSigTimeoutTime" BU_SG_REL_ Motor_Diesel_MQB SG_ 174 GE_Mom_Begr_Gradient 500;
BA_REL_ "GenSigTimeoutTime" BU_SG_REL_ Motor_Hybrid_MQB SG_ 174 GE_Mom_Begr_Gradient 500;
BA_REL_ "GenSigTimeoutTime" BU_SG_REL_ Motor_Otto_MQB SG_ 174 GE_Mom_Begr_Gradient 500;
BA_REL_ "GenSigTimeoutTime" BU_SG_REL_ Motor_Diesel_MQB SG_ 174 GE_Anheb_Solldrehz_Leerlauf 500;
BA_REL_ "GenSigTimeoutTime" BU_SG_REL_ Motor_Hybrid_MQB SG_ 174 GE_Anheb_Solldrehz_Leerlauf 500;
BA_REL_ "GenSigTimeoutTime" BU_SG_REL_ Motor_Otto_MQB SG_ 174 GE_Anheb_Solldrehz_Leerlauf 500;
BA_REL_ "GenSigTimeoutTime" BU_SG_REL_ Motor_Diesel_MQB SG_ 174 GE_Aufnahmemoment 500;
BA_REL_ "GenSigTimeoutTime" BU_SG_REL_ Motor_Hybrid_MQB SG_ 174 GE_Aufnahmemoment 500;
BA_REL_ "GenSigTimeoutTime" BU_SG_REL_ Motor_Otto_MQB SG_ 174 GE_Aufnahmemoment 500;
BA_REL_ "GenSigTimeoutTime" BU_SG_REL_ Motor_Hybrid_MQB SG_ 174 GE_HYB_DZ_Eingriff 500;
BA_REL_ "GenSigTimeoutTime" BU_SG_REL_ Motor_Diesel_MQB SG_ 301 Getriebe_13_CRC 500;
BA_REL_ "GenSigTimeoutTime" BU_SG_REL_ Motor_Hybrid_MQB SG_ 301 Getriebe_13_CRC 500;
BA_REL_ "GenSigTimeoutTime" BU_SG_REL_ Motor_Otto_MQB SG_ 301 Getriebe_13_CRC 500;
BA_REL_ "GenSigTimeoutTime" BU_SG_REL_ Motor_Diesel_MQB SG_ 301 Getriebe_13_BZ 500;
BA_REL_ "GenSigTimeoutTime" BU_SG_REL_ Motor_Hybrid_MQB SG_ 301 Getriebe_13_BZ 500;
BA_REL_ "GenSigTimeoutTime" BU_SG_REL_ Motor_Otto_MQB SG_ 301 Getriebe_13_BZ 500;
BA_REL_ "GenSigTimeoutTime" BU_SG_REL_ Motor_Diesel_MQB SG_ 301 GE_StartStopp_Info 500;
BA_REL_ "GenSigTimeoutTime" BU_SG_REL_ Motor_Otto_MQB SG_ 301 GE_StartStopp_Info 500;
BA_REL_ "GenSigTimeoutTime" BU_SG_REL_ Motor_Diesel_MQB SG_ 301 GE_Langfr_Schutzmom_02 500;
BA_REL_ "GenSigTimeoutTime" BU_SG_REL_ Motor_Hybrid_MQB SG_ 301 GE_Langfr_Schutzmom_02 500;
BA_REL_ "GenSigTimeoutTime" BU_SG_REL_ Motor_Otto_MQB SG_ 301 GE_Langfr_Schutzmom_02 500;
BA_REL_ "GenSigTimeoutTime" BU_SG_REL_ Motor_Diesel_MQB SG_ 301 GE_Eingangsdrehz 500;
BA_REL_ "GenSigTimeoutTime" BU_SG_REL_ Motor_Hybrid_MQB SG_ 301 GE_Eingangsdrehz 500;
BA_REL_ "GenSigTimeoutTime" BU_SG_REL_ Motor_Otto_MQB SG_ 301 GE_Eingangsdrehz 500;
BA_REL_ "GenSigTimeoutTime" BU_SG_REL_ Motor_Diesel_MQB SG_ 301 GE_Notlauf 500;
BA_REL_ "GenSigTimeoutTime" BU_SG_REL_ Motor_Hybrid_MQB SG_ 301 GE_Notlauf 500;
BA_REL_ "GenSigTimeoutTime" BU_SG_REL_ Motor_Otto_MQB SG_ 301 GE_Notlauf 500;
BA_REL_ "GenSigTimeoutTime" BU_SG_REL_ Motor_Diesel_MQB SG_ 301 GE_Freig_Langfr_Schutzmom 500;
BA_REL_ "GenSigTimeoutTime" BU_SG_REL_ Motor_Hybrid_MQB SG_ 301 GE_Freig_Langfr_Schutzmom 500;
BA_REL_ "GenSigTimeoutTime" BU_SG_REL_ Motor_Otto_MQB SG_ 301 GE_Freig_Langfr_Schutzmom 500;
BA_REL_ "GenSigTimeoutTime" BU_SG_REL_ Motor_Diesel_MQB SG_ 968 GE_OBD_AbsperrVent 1000;
BA_REL_ "GenSigTimeoutTime" BU_SG_REL_ Motor_Hybrid_MQB SG_ 968 GE_OBD_AbsperrVent 1000;
BA_REL_ "GenSigTimeoutTime" BU_SG_REL_ Motor_Otto_MQB SG_ 968 GE_OBD_AbsperrVent 1000;
BA_REL_ "GenSigTimeoutTime" BU_SG_REL_ Motor_Diesel_MQB SG_ 968 GE_amax_moeglich 1000;
BA_REL_ "GenSigTimeoutTime" BU_SG_REL_ Motor_Hybrid_MQB SG_ 968 GE_amax_moeglich 1000;
BA_REL_ "GenSigTimeoutTime" BU_SG_REL_ Motor_Otto_MQB SG_ 968 GE_amax_moeglich 1000;
BA_REL_ "GenSigTimeoutTime" BU_SG_REL_ Gateway_MQB SG_ 968 GE_Charisma_FahrPr 1000;
BA_REL_ "GenSigTimeoutTime" BU_SG_REL_ Gateway_MQB SG_ 968 GE_Charisma_Status 1000;
BA_REL_ "GenSigTimeoutTime" BU_SG_REL_ Motor_Diesel_MQB SG_ 968 GE_Verlustmoment 1000;
BA_REL_ "GenSigTimeoutTime" BU_SG_REL_ Motor_Hybrid_MQB SG_ 968 GE_Verlustmoment 1000;
BA_REL_ "GenSigTimeoutTime" BU_SG_REL_ Motor_Otto_MQB SG_ 968 GE_Verlustmoment 1000;
BA_REL_ "GenSigTimeoutTime" BU_SG_REL_ Motor_Diesel_MQB SG_ 968 GE_Heizwunsch 1000;
BA_REL_ "GenSigTimeoutTime" BU_SG_REL_ Motor_Hybrid_MQB SG_ 968 GE_Heizwunsch 1000;
BA_REL_ "GenSigTimeoutTime" BU_SG_REL_ Motor_Otto_MQB SG_ 968 GE_Heizwunsch 1000;
BA_REL_ "GenSigTimeoutTime" BU_SG_REL_ Motor_Diesel_MQB SG_ 968 GE_OBD_Status 1000;
BA_REL_ "GenSigTimeoutTime" BU_SG_REL_ Motor_Hybrid_MQB SG_ 968 GE_OBD_Status 1000;
BA_REL_ "GenSigTimeoutTime" BU_SG_REL_ Motor_Otto_MQB SG_ 968 GE_OBD_Status 1000;
BA_REL_ "GenSigTimeoutTime" BU_SG_REL_ Motor_Diesel_MQB SG_ 968 GE_LFR_Adaption 1000;
BA_REL_ "GenSigTimeoutTime" BU_SG_REL_ Motor_Hybrid_MQB SG_ 968 GE_LFR_Adaption 1000;
BA_REL_ "GenSigTimeoutTime" BU_SG_REL_ Motor_Otto_MQB SG_ 968 GE_LFR_Adaption 1000;
BA_REL_ "GenSigTimeoutTime" BU_SG_REL_ Motor_Diesel_MQB SG_ 968 GE_Sumpftemperatur 1000;
BA_REL_ "GenSigTimeoutTime" BU_SG_REL_ Motor_Hybrid_MQB SG_ 968 GE_Sumpftemperatur 1000;
BA_REL_ "GenSigTimeoutTime" BU_SG_REL_ Motor_Otto_MQB SG_ 968 GE_Sumpftemperatur 1000;
BA_REL_ "GenSigTimeoutTime" BU_SG_REL_ Motor_Hybrid_MQB SG_ 158 Getriebe_Hybrid_01_CRC 500;
BA_REL_ "GenSigTimeoutTime" BU_SG_REL_ Motor_Hybrid_MQB SG_ 158 Getriebe_Hybrid_01_BZ 500;
BA_REL_ "GenSigTimeoutTime" BU_SG_REL_ Motor_Hybrid_MQB SG_ 158 GE_HYB_Fehlerstatus 500;
BA_REL_ "GenSigTimeoutTime" BU_SG_REL_ Motor_Hybrid_MQB SG_ 158 GE_HYB_Freigabe_K0 500;
BA_REL_ "GenSigTimeoutTime" BU_SG_REL_ Motor_Hybrid_MQB SG_ 158 GE_HYB_Freigabe_LL_Reg 500;
BA_REL_ "GenSigTimeoutTime" BU_SG_REL_ Motor_Hybrid_MQB SG_ 158 GE_HYB_Freig_sSchl_K0 500;
BA_REL_ "GenSigTimeoutTime" BU_SG_REL_ Motor_Hybrid_MQB SG_ 158 GE_HYB_Freig_VM_EM_Stop 500;
BA_REL_ "GenSigTimeoutTime" BU_SG_REL_ Motor_Hybrid_MQB SG_ 158 GE_HYB_Wiederstart 500;
BA_REL_ "GenSigTimeoutTime" BU_SG_REL_ Motor_Hybrid_MQB SG_ 158 GE_HYB_Filt_MomAufbau 500;
BA_REL_ "GenSigTimeoutTime" BU_SG_REL_ LEH_MQB SG_ 158 GE_HYB_MomEingriff_EM 500;
BA_REL_ "GenSigTimeoutTime" BU_SG_REL_ LEH_MQB SG_ 158 GE_HYB_VZ_MomEingriff_EM 500;
BA_REL_ "GenSigTimeoutTime" BU_SG_REL_ Motor_Hybrid_MQB SG_ 158 GE_HYB_Sportfaktor 500;
BA_REL_ "GenSigTimeoutTime" BU_SG_REL_ Motor_Hybrid_MQB SG_ 158 GE_HYB_VM_akt_halten 500;
BA_REL_ "GenSigTimeoutTime" BU_SG_REL_ Motor_Hybrid_MQB SG_ 158 GE_HYB_StartAnf 500;
BA_REL_ "GenSigTimeoutTime" BU_SG_REL_ Motor_Hybrid_MQB SG_ 158 GE_HYB_VM_Startkontr 500;
VAL_ 262 ESP_QBit_Bremsdruck 0 "gueltiger_Wert" 1 "Ersatz_Init_oder_Fehlerwert" ;
VAL_ 262 ESP_QBit_Fahrer_bremst 0 "gueltiger_Wert" 1 "Ersatz_Init_oder_Fehlerwert" ;
VAL_ 262 ESP_Schwelle_Unterdruck 0 "kein_Signal" 1 "Unterdruck_kleiner_gleich_450_mbar" 2 "Unterdruck_groesser_450_mbar" 3 "Fehler_Unterdrucksensor" ;
VAL_ 262 ESP_Bremsdruck 1023 "Fehler" ;
VAL_ 262 ESP_Fahrer_bremst 0 "Bremsdruckschwelle_nicht_ueberschritten" 1 "Bremsdruckschwelle_ueberschritten" ;
VAL_ 262 ESP_Verz_TSK_aktiv 0 "TSK_Verzoegerung_inaktiv" 1 "TSK_Verzoegerung_aktiv" ;
VAL_ 262 ESP_Lenkeingriff_ADS 0 "kein_Lenkeingriff" 1 "stabilisierender_Lenkeingriff" ;
VAL_ 262 ESP_Konsistenz_TSK 0 "Botschaft_fuer_Verzoegerungsanforderung_konsistent" 1 "Botschaft_fuer_Verzoegerungsanforderung_nicht_konsistent" ;
VAL_ 262 ESP_Bremsruck_AWV2 0 "kein_Bremsruck_ausgefuehrt" 1 "Bremsruck_ausgefuehrt" ;
VAL_ 262 ESP_Konsistenz_AWV2 0 "Botschaft_fuer_AWV2_konsistent" 1 "Botschaft_fuer_AWV2_nicht_konsistent" ;
VAL_ 262 ECD_Fehler 0 "ECD_iO" 1 "ECD_Fehler" ;
VAL_ 262 ECD_nicht_verfuegbar 0 "ECD_Funktion_verfuegbar" 1 "ECD_Funktion_nicht_verfuegbar" ;
VAL_ 262 ESP_Status_Bremsentemp 0 "Bremse nicht überhitzt" 1 "Bremse überhitzt" ;
VAL_ 262 ESP_Autohold_Standby 0 "Autohold_nicht_im_Standby" 1 "Autohold_im_Standby" ;
VAL_ 262 ESP_HDC_Standby 0 "HDC_Funktion_nicht_im_Standby" 1 "HDC_Funktion_im_Standby" ;
VAL_ 262 ESP_HBA_aktiv 0 "HBA_nicht_aktiv" 1 "HBA_aktiv" ;
VAL_ 262 ESP_Prefill_ausgeloest 0 "nicht_ausgeloest" 1 "Prefill_ausgeloest" ;
VAL_ 262 ESP_Rueckwaertsfahrt_erkannt 0 "keine_Rueckwaetsfahrt" 1 "Rueckwaertsfahrt_erkannt" ;
VAL_ 262 ESP_Status_Anfahrhilfe 0 "Aus" 1 "Ein" ;
VAL_ 262 ESP_HDC_aktiv 0 "inaktiv" 1 "aktiv" ;
VAL_ 262 ESP_StartStopp_Info 0 "Motorlauf_nicht_notwendig_(Stoppfreigabe)" 1 "Motoranlauf_nicht_zwingend_notwendig_(Stoppverbot,keine_Startanforderung)" 2 "Motoranlauf_zwingend_notwendig_(Startanforderung)" 3 "Systemfehler" ;
VAL_ 262 ESP_Eingr_HL 0 "kein_Eingriff" 1 "ESP_Eingriff_HL" ;
VAL_ 262 ESP_Eingr_HR 0 "kein_Eingriff" 1 "ESP_Eingriff_HR" ;
VAL_ 262 ESP_Eingr_VL 0 "kein_Eingriff" 1 "ESP_Eingriff_VL" ;
VAL_ 262 ESP_Eingr_VR 0 "kein_Eingriff" 1 "ESP_Eingriff_VR" ;
VAL_ 262 ESP_BKV_Unterdruck 255 "Fehler" ;
VAL_ 262 ESP_Autohold_aktiv 0 "Autohold inaktiv" 1 "Autohold aktiv" ;
VAL_ 262 ESP_FStatus_Anfahrhilfe 0 "kein_Fehler" 1 "Fehler" ;
VAL_ 262 ESP_Verz_EPB_aktiv 0 "nicht aktiviert" 1 "aktiviert" ;
VAL_ 262 ECD_Bremslicht 0 "Aus" 1 "Ein" ;
VAL_ 262 ESP_Verzoeg_EPB_verf 0 "nicht verfuegbar" 1 "System verfuegbar" ;
VAL_ 262 ESP_Status_Bremsdruck 0 "Bremse drucklos" 1 "mit Bremsdruck" ;
VAL_ 262 ESP_Anforderung_EPB 0 "keine_Anforderung" 1 "Anforderung_Oeffnen" 2 "Anforderung_Schliessen" 3 "reserviert" ;
VAL_ 914 ESP_ACC_LDE 0 "Lebensdauerende_nicht_erreicht" 1 "Lebensdauerende_erreicht" ;
VAL_ 914 ESP_Quattro_Antrieb 0 "Front" 1 "Allrad" ;
VAL_ 914 ESP_Codierung_ADS 0 "Init" 1 "ESP_nicht_ADS_codiert" 2 "ADS_codiert" 3 "tbd" ;
VAL_ 914 ESP_RTA_HL 254 "Abgleich_nocht_nicht_genuegend_konvergent" 255 "Fehler" ;
VAL_ 914 ESP_RTA_HR 254 "Abgleich_nocht_nicht_genuegend_konvergent" 255 "Fehler" ;
VAL_ 914 ESP_RTA_VR 254 "Abgleich_nocht_nicht_genuegend_konvergent" 255 "Fehler" ;
VAL_ 914 OBD_Fehler_Radsensor_HL 0 "kein_Fehler" 1 "KS-" 2 "KS+" 3 "OC" 4 "OOR+" 5 "OOR-" 6 "RC+" 7 "RC-" 8 "KS+/OC" 9 "KS-/OC" 10 "KS-/KS+" 11 "KS-/KS+/OC" 12 "frei" 13 "frei" 14 "frei" 15 "frei" ;
VAL_ 914 OBD_Fehler_Radsensor_HR 0 "kein_Fehler" 1 "KS-" 2 "KS+" 3 "OC" 4 "OOR+" 5 "OOR-" 6 "RC+" 7 "RC-" 8 "KS+/OC" 9 "KS-/OC" 10 "KS-/KS+" 11 "KS-/KS+/OC" 12 "frei" 13 "frei" 14 "frei" 15 "frei" ;
VAL_ 914 OBD_Fehler_Radsensor_VL 0 "kein_Fehler" 1 "KS-" 2 "KS+" 3 "OC" 4 "OOR+" 5 "OOR-" 6 "RC+" 7 "RC-" 8 "KS+/OC" 9 "KS-/OC" 10 "KS-/KS+" 11 "KS-/KS+/OC" 12 "frei" 13 "frei" 14 "frei" 15 "frei" ;
VAL_ 914 OBD_Fehler_Radsensor_VR 0 "kein_Fehler" 1 "KS-" 2 "KS+" 3 "OC" 4 "OOR+" 5 "OOR-" 6 "RC+" 7 "RC-" 8 "KS+/OC" 9 "KS-/OC" 10 "KS-/KS+" 11 "KS-/KS+/OC" 12 "frei" 13 "frei" 14 "frei" 15 "frei" ;
VAL_ 914 ESP_Qualifizierung_Antriebsart 0 "alte_Bedeutung_Bit_ESP_Quattro_Antrieb" 1 "neue_Bedeutung_Bit_ESP_Quattro_Antrieb" ;
VAL_ 914 ESP_Offroad_Modus 0 "kein_ESP_Offroadmodus" 1 "ESP_Offroadmodus" ;
VAL_ 914 ESP_MKB_ausloesbar 0 "Multikollisionsbremsung_nicht_freigeschaltet" 1 "Multikollisionsbremsung_freigeschaltet" ;
VAL_ 914 ESP_MKB_Status 0 "Multikollisionsbremsung_nicht_aktiv" 1 "Multikollisionsbremsung_aktiv" ;
VAL_ 914 ESP_CM_Variante 0 "Standard" 1 "Erweitert" ;
VAL_ 914 ESP_OBD_Status 0 "MIL_aus" 1 "MIL_ein" ;
VAL_ 278 ESP_QBit_Wegimpuls_VL 0 "gueltiger_Wert" 1 "Ersatz_Init_oder_Fehlerwert" ;
VAL_ 278 ESP_QBit_Wegimpuls_VR 0 "gueltiger_Wert" 1 "Ersatz_Init_oder_Fehlerwert" ;
VAL_ 278 ESP_QBit_Wegimpuls_HL 0 "gueltiger_Wert" 1 "Ersatz_Init_oder_Fehlerwert" ;
VAL_ 278 ESP_QBit_Wegimpuls_HR 0 "gueltiger_Wert" 1 "Ersatz_Init_oder_Fehlerwert" ;
VAL_ 278 ESP_Wegimpuls_VL 1021 "Init" 1022 "Unterspannung" 1023 "Fehler" ;
VAL_ 278 ESP_Wegimpuls_VR 1021 "Init" 1022 "Unterspannung" 1023 "Fehler" ;
VAL_ 278 ESP_Wegimpuls_HL 1021 "Init" 1022 "Unterspannung" 1023 "Fehler" ;
VAL_ 278 ESP_Wegimpuls_HR 1021 "Init" 1022 "Unterspannung" 1023 "Fehler" ;
VAL_ 278 ESP_VL_Fahrtrichtung 0 "Vorwaerts" 1 "Rueckwaerts" 2 "Init" 3 "ungueltig_oder_nicht_verbaut" ;
VAL_ 278 ESP_VR_Fahrtrichtung 0 "Vorwaerts" 1 "Rueckwaerts" 2 "Init" 3 "ungueltig_oder_nicht_verbaut" ;
VAL_ 278 ESP_HL_Fahrtrichtung 0 "Vorwaerts" 1 "Rueckwaerts" 2 "Init" 3 "ungueltig_oder_nicht_verbaut" ;
VAL_ 278 ESP_HR_Fahrtrichtung 0 "Vorwaerts" 1 "Rueckwaerts" 2 "Init" 3 "ungueltig_oder_nicht_verbaut" ;
VAL_ 178 ESP_HL_Radgeschw_02 65533 "Unterspannung" 65534 "Init" 65535 "Fehler" ;
VAL_ 178 ESP_HR_Radgeschw_02 65533 "Unterspannung" 65534 "Init" 65535 "Fehler" ;
VAL_ 178 ESP_VL_Radgeschw_02 65533 "Unterspannung" 65534 "Init" 65535 "Fehler" ;
VAL_ 178 ESP_VR_Radgeschw_02 65533 "Unterspannung" 65534 "Init" 65535 "Fehler" ;
VAL_ 1629 BR_Systemart 0 "ABS" 1 "ABS_ASR" 2 "ESP" 3 "ESP_mit_integrierter_EPB" ;
VAL_ 1629 ESP_Charisma_FahrPr 0 "nicht_belegt" 1 "Programm_1" 2 "Programm_2" 3 "Programm_3" 4 "Programm_4" 5 "Programm_5" 6 "Programm_6" 7 "Programm_7" 8 "Programm_8" 9 "Programm_9" 10 "Programm_10" 11 "Programm_11" 12 "Programm_12" 13 "Programm_13" 14 "Programm_14" 15 "Programm_15" ;
VAL_ 1629 ESP_Charisma_Status 0 "Init" 1 "verfuegbar" 2 "nicht_verfuegbar" 3 "asynchron_durch_Fahrerwunsch" ;
VAL_ 1629 BR_QBit_Reifenumfang 0 "gueltiger_Wert" 1 "Ersatz_Init_oder_Fehlerwert" ;
VAL_ 253 BR_Eingriffsmoment 1022 "Init" 1023 "Fehler" ;
VAL_ 253 ESP_v_Signal 65533 "Unterspannung" 65534 "Init" 65535 "Fehler" ;
VAL_ 253 ASR_Tastung_passiv 0 "ASR_aktiviert" 1 "ASR_passiv_getastet_oder_Schwellen_geaendert" ;
VAL_ 253 ESP_Tastung_passiv 0 "ESP_aktiviert" 1 "ESP_passiv_getastet_oder_Schwellen_geaendert" ;
VAL_ 253 ESP_Systemstatus 0 "iO" 1 "Fehler" ;
VAL_ 253 ASR_Schalteingriff 0 "keine Anforderung" 1 "ASR_Schaltkennfeld" 2 "Rückschaltung" 3 "Schaltverbot" ;
VAL_ 253 ESP_Haltebestaetigung 0 "kein_sicheres_Halten" 1 "sicheres_Halten" ;
VAL_ 253 ESP_QBit_v_Signal 0 "gueltiger_Wert" 1 "Ersatz_Init_oder_Fehlerwert" ;
VAL_ 253 ABS_Bremsung 0 "keine_ABS_Regelung" 1 "ABS_Regelung_aktiv" ;
VAL_ 253 ASR_Anf 0 "keine_Anforderung" 1 "ASR_Anforderung" ;
VAL_ 253 MSR_Anf 0 "keine Anfoderung" 1 "MSR-Anforderung" ;
VAL_ 253 EBV_Eingriff 0 "kein EBV-Eingriff" 1 "EBV-Eingriff" ;
VAL_ 253 EDS_Eingriff 0 "kein_EDS_Eingriff" 1 "EDS_Eingriff" ;
VAL_ 253 ESP_Eingriff 0 "kein_ESP_Eingriff" 1 "ESP_Eingriff_aktiv" ;
VAL_ 253 ESP_ASP 0 "inaktiv" 1 "aktiv" ;
VAL_ 253 ESP_Anhaltevorgang_ACC_aktiv 0 "inaktiv" 1 "aktiv" ;
VAL_ 987 BCM_01_alt 0 "aktuell" 1 "veraltet" ;
VAL_ 987 SMLS_01_alt 0 "aktuell" 1 "veraltet" ;
VAL_ 987 ZV_02_alt 0 "aktuell" 1 "veraltet" ;
VAL_ 987 Wischer_01_alt 0 "aktuell" 1 "veraltet" ;
VAL_ 987 Anhaenger_01_alt 0 "aktuell" 1 "veraltet" ;
VAL_ 987 Klima_Sensor_02_alt 0 "aktuell" 1 "veraltet" ;
VAL_ 987 VSG_01_alt 0 "aktuell" 1 "veraltet" ;
VAL_ 987 Klima_01_alt 0 "aktuell" 1 "veraltet" ;
VAL_ 987 WFS_01_alt 0 "aktuell" 1 "veraltet" ;
VAL_ 987 Licht_Anf_01_alt 0 "aktuell" 1 "veraltet" ;
VAL_ 987 ZV_HFS_offen 0 "geschlossen" 1 "offen" ;
VAL_ 987 ZV_HBFS_offen 0 "geschlossen" 1 "offen" ;
VAL_ 987 VS_VD_offen_ver 1 "Zustand des Verdecks verriegelt und offen " ;
VAL_ 987 VS_VD_zu_ver 1 "Zustand des Verdecks verriegelt und geschlossen" ;
VAL_ 987 ZV_BT_offen 1 "BT_geoeffnet" ;
VAL_ 987 BCM1_Rueckfahrlicht_Schalter 0 "nicht_betaetigt" 1 "betaetigt" ;
VAL_ 987 ZV_FT_offen 1 "FT_geoeffnet" ;
VAL_ 987 Wischer_vorne_aktiv 1 "Wischer vorne läuft" ;
VAL_ 987 AAG_Anhaenger_erkannt 0 "kein_Anhaenger_erkannt" 1 "AAG_Anhaenger_erkannt" ;
VAL_ 987 BCM1_MH_Schalter 0 "MH_geschlossen" 1 "MH_offen" ;
VAL_ 987 ZV_HD_offen 1 "Heckdeckel_auf" ;
VAL_ 987 Waschen_vorne_aktiv 1 "Waschen aktiv" ;
VAL_ 987 KL_Thermomanagement 0 "keine_Freigabe_TMM__max_Heizbedarf" 1 "kleine_Freigabe_TMM" 2 "mittlere_Freigabe_TMM" 3 "volle_Freigabe_TMM__kein_Heizbedarf" ;
VAL_ 987 WFS_Schluessel_Fahrberecht 0 "kein authorisierter Schluessel erkannt " 1 "aktive_Funkschluessel_Nr_01" 2 "aktive_Funkschluessel_Nr_02" 3 "aktive_Funkschluessel_Nr_03" 4 "aktive_Funkschluessel_Nr_04" 5 "aktive_Funkschluessel_Nr_05" 6 "aktive_Funkschluessel_Nr_06" 7 "aktive_Funkschluessel_Nr_07" 8 "aktive_Funkschluessel_Nr_08" 9 "ungueltig_09" 10 "ungueltig_10" 11 "ungueltig_11" 12 "ungueltig_12" 13 "ungueltig_13" 14 "ungueltig_14" 15 "ungueltig_15" ;
VAL_ 987 BCM1_RFahrlicht_Fzg_Anf 0 "Licht_nicht_angefordert" 1 "Licht ist einzuschalten" ;
VAL_ 987 BCM1_RFahrlicht_Ahg_Anf 0 "Licht_nicht_angefordert" 1 "Licht ist einzuschalten" ;
VAL_ 987 BH_Fernlicht 0 "nicht_betaetigt" 1 "Blinkerhebel_in_Richtung_Fernlicht_betaetigt" ;
VAL_ 987 BH_Blinker_li 0 "nicht_betaetigt" 1 "Blinkerhebel_Richtung_links_betaetigt" ;
VAL_ 987 BH_Blinker_re 0 "nicht_betaetigt" 1 "Blinkerhebel_Richtung_rechts_betaetigt" ;
VAL_ 987 BCM1_OBD_FStatus_ATemp 0 "kein Fehler" 1 "KS-" 2 "KS+" 3 "OC (Leitungsunterbrechung)" 4 "OOR+ (out of range high)" 5 "OOR- (out of range low)" 6 "RC+ (Signal unplausibel hoch)" 7 "RC- (Signal unplausibel niedrig)" 8 "KS+/OC" 9 "KS-/OC" 10 "KS-/KS+" 11 "KS-/KS+/OC (allgemeiner Fehler)" ;
VAL_ 987 BCM1_Aussen_Temp_ungef 253 "nicht verbaut" 254 "Initwert" 255 "Fehler" ;
VAL_ 989 LH_EPS_01_alt 0 "aktuell" 1 "veraltet" ;
VAL_ 989 Kessy_04_alt 0 "aktuell" 1 "veraltet" ;
VAL_ 989 LIN_2_alt 0 "aktuell" 1 "veraltet" ;
VAL_ 989 MFG_01_alt 0 "aktuell" 1 "veraltet" ;
VAL_ 989 Klima_02_alt 0 "aktuell" 1 "veraltet" ;
VAL_ 989 Parkhilfe_01_alt 0 "aktuell" 1 "veraltet" ;
VAL_ 989 ELV_01_alt 0 "aktuell" 1 "veraltet" ;
VAL_ 989 KY_StartStopp_Info 0 "Motorlauf_nicht_notwendig_(Stoppfreigabe)" 1 "Motoranlauf_nicht_zwingend_notwendig_(Stoppverbot,keine_Startanforderung)" 2 "Motoranlauf_zwingend_notwendig_(Startanforderung)" 3 "Systemfehler" ;
VAL_ 989 PH_StartStopp_Info 0 "Motorlauf_nicht_notwendig_(Stoppfreigabe)" 1 "Motoranlauf_nicht_zwingend_notwendig_(Stoppverbot,keine_Startanforderung)" 2 "Motoranlauf_zwingend_notwendig_(Startanforderung)" 3 "Systemfehler" ;
VAL_ 989 EPS_Lenkerposition 0 "unbekannt" 1 "Linkslenker" 2 "Rechtslenker" ;
VAL_ 989 MF_StartStopp_Info 0 "Motorlauf_nicht_notwendig_(Stoppfreigabe)" 1 "Motoranlauf_nicht_zwingend_notwendig_(Stoppverbot,keine_Startanforderung)" 2 "Motoranlauf_zwingend_notwendig_(Startanforderung)" 3 "Systemfehler" ;
VAL_ 989 KL_Umluftklappe_Status 0 "Frischluft" 1 "Teilumluft_10" 2 "Teilumluft_20" 3 "Teilumluft_30" 4 "Teilumluft_40" 5 "Teilumluft_50" 6 "Teilumluft_60" 7 "Teilumluft_70" 8 "Teilumluft_80" 9 "Teilumluft_90" 10 "Umluft" 15 "Fehler" ;
VAL_ 989 MFL_Tip_Down 0 "nicht_betaetigt" 1 "betaetigt" ;
VAL_ 989 MFL_Tip_Up 0 "nicht_betaetigt" 1 "betaetigt" ;
VAL_ 989 LS_Tiptronic_Fehler 0 " i. O." 1 "Fehler erkannt" ;
VAL_ 296 GE_WH_Sperre 0 "Wählhebel sperren" 1 "Wählhebel freigeben" ;
VAL_ 296 GE_Ausleuchtungsmode 0 "RDW" 1 "NAR" ;
VAL_ 296 GE_Test_Freigabe 0 "kein Test" 1 "gültige Testparameter" ;
VAL_ 296 GE_Ist_Fahrstufe 0 "Init" 1 "Position_1" 2 "Position_2" 3 "Position_3" 4 "Position_4" 5 "D" 6 "N" 7 "R" 8 "P" 10 "Position_Tipp_plus" 11 "Position_Tipp_minus" 12 "S" 14 "Tipp-Gasse" 15 "Fehler" ;
VAL_ 173 GE_MMom_Soll_02 1022 "Init" 1023 "Fehler" ;
VAL_ 173 GE_MMom_Vorhalt_02 1022 "Init" 1023 "Fehler" ;
VAL_ 173 GE_Uefkt 1023 "Fehler" ;
VAL_ 173 GE_Fahrstufe 0 "Zwischenstellung" 1 "Init" 5 "Position_P" 6 "Position_R" 7 "Position_N" 8 "Position_D" 9 "Position_S" 10 "Effizienz" 13 "Tipp_in_S" 14 "Tipp_in_D" 15 "Fehler" ;
VAL_ 173 GE_Schaltvorgang 0 "keine Schaltung" 1 "Schaltung aktiv" ;
VAL_ 173 GE_Status_Kupplung 0 "Kupplung geöffnet" 1 "Kupplung geregelt" 2 "Kupplung geschlossen" 3 "Fehler" ;
VAL_ 173 GE_MMom_Status 0 "keine Anforderung" 1 "reduzierender Getriebeeingriff" 2 "erhöhender Getriebeeingriff" 3 "Änderung mit Sprung" ;
VAL_ 173 GE_Freig_MMom_Vorhalt 0 "nicht_freigegeben" 1 "freigegeben" ;
VAL_ 173 GE_Verbot_Ausblendung 0 "kein_Verbot" 1 "Verbot" ;
VAL_ 173 GE_Zielgang 0 "Gang P/N (ausgekuppelt)" 1 "Gang 1" 2 "Gang 2" 3 "Gang 3" 4 "Gang 4" 5 "Gang 5" 6 "Gang 6" 7 "Gang 7" 8 "Gang R" 11 "Gang 8" 12 "Gang 9" 14 "Istgang nicht definiert" 15 "Fehler" ;
VAL_ 174 GE_Drehzahlmesser_Daempfung 0 "normale Dämpfung" 1 "dynamische Dämpfung" ;
VAL_ 174 GE_Schubabschalt_Unt 0 "inaktiv" 1 "aktiv" ;
VAL_ 174 GE_Freigabe_Synchro 0 "inaktiv" 1 "aktiv" ;
VAL_ 174 GE_Synchro_Wunschdrehz 511 "Fehler" ;
VAL_ 174 GE_Synchro_Zeit 255 "Fehler" ;
VAL_ 174 GE_Mom_Begr_Gradient 255 "keine Begrenzung (Init)" ;
VAL_ 174 GE_Anheb_Solldrehz_Leerlauf 255 "Fehler" ;
VAL_ 174 GE_Aufnahmemoment 1022 "Init" 1023 "Fehler" ;
VAL_ 174 GE_Anf_Zylabsch 0 "Umschaltung erlaubt" 1 "Umschaltung verboten" 3 "VMB-Empfehlung" ;
VAL_ 174 GE_HYB_DZ_Eingriff 0 "kein_Drehzahleingriff" 1 "Slip_Start" 2 "Low_Speed_Modus" ;
VAL_ 301 GE_StartStopp_Info 0 "Motorlauf_nicht_notwendig_(Stoppfreigabe)" 1 "Motoranlauf_nicht_zwingend_notwendig_(Stoppverbot,keine_Startanforderung)" 2 "Motoranlauf_zwingend_notwendig_(Startanforderung)" 3 "Systemfehler" ;
VAL_ 301 GE_Langfr_Schutzmom_02 510 "Init" 511 "Fehler" ;
VAL_ 301 GE_Eingangsdrehz 16382 "Init" 16383 "Fehler" ;
VAL_ 301 GE_Notlauf 0 "kein Notlauf / Init" 1 "Getriebe im Notlauf" ;
VAL_ 301 GE_Freig_Langfr_Schutzmom 0 "nicht freigegeben" 1 "freigegeben" ;
VAL_ 968 GE_OBD_AbsperrVent 0 "kein_Fehler" 1 "KS-" 2 "KS+" 3 "OC" 4 "OOR+" 5 "OOR-" 6 "RC+" 7 "RC-" 8 "KS+/OC" 9 "KS-/OC" 10 "KS-/KS+" 11 "KS-/KS+/OC" 12 "frei" 13 "frei" 14 "frei" 15 "frei" ;
VAL_ 968 GE_amax_moeglich 511 "Wert ist nicht definiert" ;
VAL_ 968 GE_Charisma_FahrPr 0 "nicht_belegt" 1 "Programm_1" 2 "Programm_2" 3 "Programm_3" 4 "Programm_4" 5 "Programm_5" 6 "Programm_6" 7 "Programm_7" 8 "Programm_8" 9 "Programm_9" 10 "Programm_10" 11 "Programm_11" 12 "Programm_12" 13 "Programm_13" 14 "Programm_14" 15 "Programm_15" ;
VAL_ 968 GE_Charisma_Status 0 "Init" 1 "verfuegbar" 2 "nicht_verfuegbar" 3 "asynchron_durch_Fahrerwunsch" ;
VAL_ 968 GE_Verlustmoment 255 "Fehler" ;
VAL_ 968 GE_Freigabe_Verfallsinfo_WFS 0 "aus" 1 "ein" ;
VAL_ 968 GE_Codierung_MSG 0 "Codierung iO / Init" 1 "Codierung niO" ;
VAL_ 968 GE_LaunchControl 0 "inaktiv" 1 "aktiv" ;
VAL_ 968 GE_Heizwunsch 0 "maximaler_Waermebedarf" 1 "kein_Waermebedarf" 2 "Kuehlbedarf" 3 "Notfall_(maximaler_Kuehlbedarf)" ;
VAL_ 968 GE_OBD_Status 0 "MIL aus" 1 "MIL ein" ;
VAL_ 968 GE_LFR_Adaption 0 "fuer_Adaption_geeignet" 1 "fuer_Adaption_nicht_geeignet" ;
VAL_ 968 GE_Sumpftemperatur 255 "Fehler" ;
VAL_ 158 GE_HYB_Fehlerstatus 0 "kein_Fehler" 1 "kein_Hydraulikdruck" 2 "Anforderung_N_gleich_0" 3 "beide_Fehler" ;
VAL_ 158 GE_HYB_Freigabe_K0 0 "Freigabe_K0_oeffnen" 1 "Freigabe_K0_schliessen" ;
VAL_ 158 GE_HYB_Freigabe_LL_Reg 0 "keine_DZ_reg_erlaubt" 1 "LL_Reg_freigegeben" ;
VAL_ 158 GE_HYB_Freig_sSchl_K0 0 "keine_Anf_Schliessen_K0" 1 "Anf_Schliessen_K0" ;
VAL_ 158 GE_HYB_Freig_VM_EM_Stop 0 "VM_EM_darf_nicht_stoppen" 1 "VM_EM_darf_stoppen" ;
VAL_ 158 GE_HYB_Wiederstart 0 "kein_Wiederstart_aktiv" 1 "Wiederstart_aktiv" ;
VAL_ 158 GE_HYB_Filt_MomAufbau 0 "keine_Beeinflussung_der_Filterung_durch_Getriebe" 1 "multiplikative_Konstante_fuer_MSG" 2 "multiplikative_Konstante_fuer_MSG" 3 "multiplikative_Konstante_fuer_MSG" 4 "multiplikative_Konstante_fuer_MSG" 5 "multiplikative_Konstante_fuer_MSG" 6 "multiplikative_Konstante_fuer_MSG" 7 "multiplikative_Konstante_fuer_MSG" ;
VAL_ 158 GE_HYB_nK0 255 "Fehler" ;
VAL_ 158 GE_HYB_VZ_MomEingriff_EM 0 "positiv" 1 "negativ" ;
VAL_ 158 GE_HYB_Sportfaktor 0 "nicht_sportlich" ;
VAL_ 158 GE_HYB_VM_akt_halten 0 "keine_Empfehlung" 1 "VM_aktiv_halten_starten" ;
VAL_ 158 GE_HYB_StartAnf 0 "keine_Startanforderung" 1 "Startanforderung" ;
VAL_ 158 GE_HYB_VM_Startkontr 0 "VM_StartAnf_nicht_freigegeben" 1 "VM_StartAnf_freigegeben" ;
